VERSION ""

NS_ :

BS_:

BU_: CAM TESTER FRS VCU GW ESC ACU TCM

BO_ 71 FRS_Obj_39_Part02: 8 FRS
 SG_ FRS_Msg_CheckSum_39Obj02 : 63|8@0+ (1,0) [0|255] "bit"  CAM
 SG_ FRS_Msg_AliveCounter_39Obj02 : 51|4@0+ (1,0) [0|15] "bit"  CAM
 SG_ FRS_Obj_Type_39Obj : 33|2@0+ (1,0) [0|3] "bit"  CAM
 SG_ FRS_Obj_MeasFlag_39Obj : 52|1@0+ (1,0) [0|1] "bit"  CAM
 SG_ FRS_Obj_YVelRel_39Obj : 47|11@0+ (0.1,-102.4) [-102.4|102.3] "m/s"  CAM
 SG_ FRS_Obj_XVelRel_39Obj : 7|11@0+ (0.1,-102.4) [-102.4|102.3] "m/s"  CAM
 SG_ FRS_Obj_YPos_39Obj : 12|13@0+ (0.015625,-64) [-64|63.984375] "m"  CAM
 SG_ FRS_Obj_XPos_39Obj : 31|14@0+ (0.015625,0) [0|255.984375] "m"  CAM

BO_ 70 FRS_Obj_38_Part02: 8 FRS
 SG_ FRS_Msg_CheckSum_38Obj02 : 63|8@0+ (1,0) [0|255] "bit"  CAM
 SG_ FRS_Msg_AliveCounter_38Obj02 : 51|4@0+ (1,0) [0|15] "bit"  CAM
 SG_ FRS_Obj_Type_38Obj : 33|2@0+ (1,0) [0|3] "bit"  CAM
 SG_ FRS_Obj_MeasFlag_38Obj : 52|1@0+ (1,0) [0|1] "bit"  CAM
 SG_ FRS_Obj_YVelRel_38Obj : 47|11@0+ (0.1,-102.4) [-102.4|102.3] "m/s"  CAM
 SG_ FRS_Obj_XVelRel_38Obj : 7|11@0+ (0.1,-102.4) [-102.4|102.3] "m/s"  CAM
 SG_ FRS_Obj_YPos_38Obj : 12|13@0+ (0.015625,-64) [-64|63.984375] "m"  CAM
 SG_ FRS_Obj_XPos_38Obj : 31|14@0+ (0.015625,0) [0|255.984375] "m"  CAM

BO_ 69 FRS_Obj_37_Part02: 8 FRS
 SG_ FRS_Msg_CheckSum_37Obj02 : 63|8@0+ (1,0) [0|255] "bit"  CAM
 SG_ FRS_Msg_AliveCounter_37Obj02 : 51|4@0+ (1,0) [0|15] "bit"  CAM
 SG_ FRS_Obj_Type_37Obj : 33|2@0+ (1,0) [0|3] "bit"  CAM
 SG_ FRS_Obj_MeasFlag_37Obj : 52|1@0+ (1,0) [0|1] "bit"  CAM
 SG_ FRS_Obj_YVelRel_37Obj : 47|11@0+ (0.1,-102.4) [-102.4|102.3] "m/s"  CAM
 SG_ FRS_Obj_XVelRel_37Obj : 7|11@0+ (0.1,-102.4) [-102.4|102.3] "m/s"  CAM
 SG_ FRS_Obj_YPos_37Obj : 12|13@0+ (0.015625,-64) [-64|63.984375] "m"  CAM
 SG_ FRS_Obj_XPos_37Obj : 31|14@0+ (0.015625,0) [0|255.984375] "m"  CAM

BO_ 68 FRS_Obj_36_Part02: 8 FRS
 SG_ FRS_Msg_CheckSum_36Obj02 : 63|8@0+ (1,0) [0|255] "bit"  CAM
 SG_ FRS_Msg_AliveCounter_36Obj02 : 51|4@0+ (1,0) [0|15] "bit"  CAM
 SG_ FRS_Obj_Type_36Obj : 33|2@0+ (1,0) [0|3] "bit"  CAM
 SG_ FRS_Obj_MeasFlag_36Obj : 52|1@0+ (1,0) [0|1] "bit"  CAM
 SG_ FRS_Obj_YVelRel_36Obj : 47|11@0+ (0.1,-102.4) [-102.4|102.3] "m/s"  CAM
 SG_ FRS_Obj_XVelRel_36Obj : 7|11@0+ (0.1,-102.4) [-102.4|102.3] "m/s"  CAM
 SG_ FRS_Obj_YPos_36Obj : 12|13@0+ (0.015625,-64) [-64|63.984375] "m"  CAM
 SG_ FRS_Obj_XPos_36Obj : 31|14@0+ (0.015625,0) [0|255.984375] "m"  CAM

BO_ 67 FRS_Obj_35_Part02: 8 FRS
 SG_ FRS_Msg_CheckSum_35Obj02 : 63|8@0+ (1,0) [0|255] "bit"  CAM
 SG_ FRS_Msg_AliveCounter_35Obj02 : 51|4@0+ (1,0) [0|15] "bit"  CAM
 SG_ FRS_Obj_Type_35Obj : 33|2@0+ (1,0) [0|3] "bit"  CAM
 SG_ FRS_Obj_MeasFlag_35Obj : 52|1@0+ (1,0) [0|1] "bit"  CAM
 SG_ FRS_Obj_YVelRel_35Obj : 47|11@0+ (0.1,-102.4) [-102.4|102.3] "m/s"  CAM
 SG_ FRS_Obj_XVelRel_35Obj : 7|11@0+ (0.1,-102.4) [-102.4|102.3] "m/s"  CAM
 SG_ FRS_Obj_YPos_35Obj : 12|13@0+ (0.015625,-64) [-64|63.984375] "m"  CAM
 SG_ FRS_Obj_XPos_35Obj : 31|14@0+ (0.015625,0) [0|255.984375] "m"  CAM

BO_ 66 FRS_Obj_34_Part02: 8 FRS
 SG_ FRS_Msg_CheckSum_34Obj02 : 63|8@0+ (1,0) [0|255] "bit"  CAM
 SG_ FRS_Msg_AliveCounter_34Obj02 : 51|4@0+ (1,0) [0|15] "bit"  CAM
 SG_ FRS_Obj_Type_34Obj : 33|2@0+ (1,0) [0|3] "bit"  CAM
 SG_ FRS_Obj_MeasFlag_34Obj : 52|1@0+ (1,0) [0|1] "bit"  CAM
 SG_ FRS_Obj_YVelRel_34Obj : 47|11@0+ (0.1,-102.4) [-102.4|102.3] "m/s"  CAM
 SG_ FRS_Obj_XVelRel_34Obj : 7|11@0+ (0.1,-102.4) [-102.4|102.3] "m/s"  CAM
 SG_ FRS_Obj_YPos_34Obj : 12|13@0+ (0.015625,-64) [-64|63.984375] "m"  CAM
 SG_ FRS_Obj_XPos_34Obj : 31|14@0+ (0.015625,0) [0|255.984375] "m"  CAM

BO_ 65 FRS_Obj_33_Part02: 8 FRS
 SG_ FRS_Msg_CheckSum_33Obj02 : 63|8@0+ (1,0) [0|255] "bit"  CAM
 SG_ FRS_Msg_AliveCounter_33Obj02 : 51|4@0+ (1,0) [0|15] "bit"  CAM
 SG_ FRS_Obj_Type_33Obj : 33|2@0+ (1,0) [0|3] "bit"  CAM
 SG_ FRS_Obj_MeasFlag_33Obj : 52|1@0+ (1,0) [0|1] "bit"  CAM
 SG_ FRS_Obj_YVelRel_33Obj : 47|11@0+ (0.1,-102.4) [-102.4|102.3] "m/s"  CAM
 SG_ FRS_Obj_XVelRel_33Obj : 7|11@0+ (0.1,-102.4) [-102.4|102.3] "m/s"  CAM
 SG_ FRS_Obj_YPos_33Obj : 12|13@0+ (0.015625,-64) [-64|63.984375] "m"  CAM
 SG_ FRS_Obj_XPos_33Obj : 31|14@0+ (0.015625,0) [0|255.984375] "m"  CAM

BO_ 64 FRS_Obj_32_Part02: 8 FRS
 SG_ FRS_Msg_CheckSum_32Obj02 : 63|8@0+ (1,0) [0|255] "bit"  CAM
 SG_ FRS_Msg_AliveCounter_32Obj02 : 51|4@0+ (1,0) [0|15] "bit"  CAM
 SG_ FRS_Obj_Type_32Obj : 33|2@0+ (1,0) [0|3] "bit"  CAM
 SG_ FRS_Obj_MeasFlag_32Obj : 52|1@0+ (1,0) [0|1] "bit"  CAM
 SG_ FRS_Obj_YVelRel_32Obj : 47|11@0+ (0.1,-102.4) [-102.4|102.3] "m/s"  CAM
 SG_ FRS_Obj_XVelRel_32Obj : 7|11@0+ (0.1,-102.4) [-102.4|102.3] "m/s"  CAM
 SG_ FRS_Obj_YPos_32Obj : 12|13@0+ (0.015625,-64) [-64|63.984375] "m"  CAM
 SG_ FRS_Obj_XPos_32Obj : 31|14@0+ (0.015625,0) [0|255.984375] "m"  CAM

BO_ 63 FRS_Obj_31_Part02: 8 FRS
 SG_ FRS_Msg_CheckSum_31Obj02 : 63|8@0+ (1,0) [0|255] "bit"  CAM
 SG_ FRS_Msg_AliveCounter_31Obj02 : 51|4@0+ (1,0) [0|15] "bit"  CAM
 SG_ FRS_Obj_Type_31Obj : 33|2@0+ (1,0) [0|3] "bit"  CAM
 SG_ FRS_Obj_MeasFlag_31Obj : 52|1@0+ (1,0) [0|1] "bit"  CAM
 SG_ FRS_Obj_YVelRel_31Obj : 47|11@0+ (0.1,-102.4) [-102.4|102.3] "m/s"  CAM
 SG_ FRS_Obj_XVelRel_31Obj : 7|11@0+ (0.1,-102.4) [-102.4|102.3] "m/s"  CAM
 SG_ FRS_Obj_YPos_31Obj : 12|13@0+ (0.015625,-64) [-64|63.984375] "m"  CAM
 SG_ FRS_Obj_XPos_31Obj : 31|14@0+ (0.015625,0) [0|255.984375] "m"  CAM

BO_ 62 FRS_Obj_30_Part02: 8 FRS
 SG_ FRS_Msg_CheckSum_30Obj02 : 63|8@0+ (1,0) [0|255] "bit"  CAM
 SG_ FRS_Msg_AliveCounter_30Obj02 : 51|4@0+ (1,0) [0|15] "bit"  CAM
 SG_ FRS_Obj_Type_30Obj : 33|2@0+ (1,0) [0|3] "bit"  CAM
 SG_ FRS_Obj_MeasFlag_30Obj : 52|1@0+ (1,0) [0|1] "bit"  CAM
 SG_ FRS_Obj_YVelRel_30Obj : 47|11@0+ (0.1,-102.4) [-102.4|102.3] "m/s"  CAM
 SG_ FRS_Obj_XVelRel_30Obj : 7|11@0+ (0.1,-102.4) [-102.4|102.3] "m/s"  CAM
 SG_ FRS_Obj_YPos_30Obj : 12|13@0+ (0.015625,-64) [-64|63.984375] "m"  CAM
 SG_ FRS_Obj_XPos_30Obj : 31|14@0+ (0.015625,0) [0|255.984375] "m"  CAM

BO_ 61 FRS_Obj_29_Part02: 8 FRS
 SG_ FRS_Msg_CheckSum_29Obj02 : 63|8@0+ (1,0) [0|255] "bit"  CAM
 SG_ FRS_Msg_AliveCounter_29Obj02 : 51|4@0+ (1,0) [0|15] "bit"  CAM
 SG_ FRS_Obj_Type_29Obj : 33|2@0+ (1,0) [0|3] "bit"  CAM
 SG_ FRS_Obj_MeasFlag_29Obj : 52|1@0+ (1,0) [0|1] "bit"  CAM
 SG_ FRS_Obj_YVelRel_29Obj : 47|11@0+ (0.1,-102.4) [-102.4|102.3] "m/s"  CAM
 SG_ FRS_Obj_XVelRel_29Obj : 7|11@0+ (0.1,-102.4) [-102.4|102.3] "m/s"  CAM
 SG_ FRS_Obj_YPos_29Obj : 12|13@0+ (0.015625,-64) [-64|63.984375] "m"  CAM
 SG_ FRS_Obj_XPos_29Obj : 31|14@0+ (0.015625,0) [0|255.984375] "m"  CAM

BO_ 60 FRS_Obj_28_Part02: 8 FRS
 SG_ FRS_Msg_CheckSum_28Obj02 : 63|8@0+ (1,0) [0|255] "bit"  CAM
 SG_ FRS_Msg_AliveCounter_28Obj02 : 51|4@0+ (1,0) [0|15] "bit"  CAM
 SG_ FRS_Obj_Type_28Obj : 33|2@0+ (1,0) [0|3] "bit"  CAM
 SG_ FRS_Obj_MeasFlag_28Obj : 52|1@0+ (1,0) [0|1] "bit"  CAM
 SG_ FRS_Obj_YVelRel_28Obj : 47|11@0+ (0.1,-102.4) [-102.4|102.3] "m/s"  CAM
 SG_ FRS_Obj_XVelRel_28Obj : 7|11@0+ (0.1,-102.4) [-102.4|102.3] "m/s"  CAM
 SG_ FRS_Obj_YPos_28Obj : 12|13@0+ (0.015625,-64) [-64|63.984375] "m"  CAM
 SG_ FRS_Obj_XPos_28Obj : 31|14@0+ (0.015625,0) [0|255.984375] "m"  CAM

BO_ 59 FRS_Obj_27_Part02: 8 FRS
 SG_ FRS_Msg_CheckSum_27Obj02 : 63|8@0+ (1,0) [0|255] "bit"  CAM
 SG_ FRS_Msg_AliveCounter_27Obj02 : 51|4@0+ (1,0) [0|15] "bit"  CAM
 SG_ FRS_Obj_Type_27Obj : 33|2@0+ (1,0) [0|3] "bit"  CAM
 SG_ FRS_Obj_MeasFlag_27Obj : 52|1@0+ (1,0) [0|1] "bit"  CAM
 SG_ FRS_Obj_YVelRel_27Obj : 47|11@0+ (0.1,-102.4) [-102.4|102.3] "m/s"  CAM
 SG_ FRS_Obj_XVelRel_27Obj : 7|11@0+ (0.1,-102.4) [-102.4|102.3] "m/s"  CAM
 SG_ FRS_Obj_YPos_27Obj : 12|13@0+ (0.015625,-64) [-64|63.984375] "m"  CAM
 SG_ FRS_Obj_XPos_27Obj : 31|14@0+ (0.015625,0) [0|255.984375] "m"  CAM

BO_ 58 FRS_Obj_26_Part02: 8 FRS
 SG_ FRS_Msg_CheckSum_26Obj02 : 63|8@0+ (1,0) [0|255] "bit"  CAM
 SG_ FRS_Msg_AliveCounter_26Obj02 : 51|4@0+ (1,0) [0|15] "bit"  CAM
 SG_ FRS_Obj_Type_26Obj : 33|2@0+ (1,0) [0|3] "bit"  CAM
 SG_ FRS_Obj_MeasFlag_26Obj : 52|1@0+ (1,0) [0|1] "bit"  CAM
 SG_ FRS_Obj_YVelRel_26Obj : 47|11@0+ (0.1,-102.4) [-102.4|102.3] "m/s"  CAM
 SG_ FRS_Obj_XVelRel_26Obj : 7|11@0+ (0.1,-102.4) [-102.4|102.3] "m/s"  CAM
 SG_ FRS_Obj_YPos_26Obj : 12|13@0+ (0.015625,-64) [-64|63.984375] "m"  CAM
 SG_ FRS_Obj_XPos_26Obj : 31|14@0+ (0.015625,0) [0|255.984375] "m"  CAM

BO_ 57 FRS_Obj_25_Part02: 8 FRS
 SG_ FRS_Msg_CheckSum_25Obj02 : 63|8@0+ (1,0) [0|255] "bit"  CAM
 SG_ FRS_Msg_AliveCounter_25Obj02 : 51|4@0+ (1,0) [0|15] "bit"  CAM
 SG_ FRS_Obj_Type_25Obj : 33|2@0+ (1,0) [0|3] "bit"  CAM
 SG_ FRS_Obj_MeasFlag_25Obj : 52|1@0+ (1,0) [0|1] "bit"  CAM
 SG_ FRS_Obj_YVelRel_25Obj : 47|11@0+ (0.1,-102.4) [-102.4|102.3] "m/s"  CAM
 SG_ FRS_Obj_XVelRel_25Obj : 7|11@0+ (0.1,-102.4) [-102.4|102.3] "m/s"  CAM
 SG_ FRS_Obj_YPos_25Obj : 12|13@0+ (0.015625,-64) [-64|63.984375] "m"  CAM
 SG_ FRS_Obj_XPos_25Obj : 31|14@0+ (0.015625,0) [0|255.984375] "m"  CAM

BO_ 56 FRS_Obj_24_Part02: 8 FRS
 SG_ FRS_Msg_CheckSum_24Obj02 : 63|8@0+ (1,0) [0|255] "bit"  CAM
 SG_ FRS_Msg_AliveCounter_24Obj02 : 51|4@0+ (1,0) [0|15] "bit"  CAM
 SG_ FRS_Obj_Type_24Obj : 33|2@0+ (1,0) [0|3] "bit"  CAM
 SG_ FRS_Obj_MeasFlag_24Obj : 52|1@0+ (1,0) [0|1] "bit"  CAM
 SG_ FRS_Obj_YVelRel_24Obj : 47|11@0+ (0.1,-102.4) [-102.4|102.3] "m/s"  CAM
 SG_ FRS_Obj_XVelRel_24Obj : 7|11@0+ (0.1,-102.4) [-102.4|102.3] "m/s"  CAM
 SG_ FRS_Obj_YPos_24Obj : 12|13@0+ (0.015625,-64) [-64|63.984375] "m"  CAM
 SG_ FRS_Obj_XPos_24Obj : 31|14@0+ (0.015625,0) [0|255.984375] "m"  CAM

BO_ 55 FRS_Obj_23_Part02: 8 FRS
 SG_ FRS_Msg_CheckSum_23Obj02 : 63|8@0+ (1,0) [0|255] "bit"  CAM
 SG_ FRS_Msg_AliveCounter_23Obj02 : 51|4@0+ (1,0) [0|15] "bit"  CAM
 SG_ FRS_Obj_Type_23Obj : 33|2@0+ (1,0) [0|3] "bit"  CAM
 SG_ FRS_Obj_MeasFlag_23Obj : 52|1@0+ (1,0) [0|1] "bit"  CAM
 SG_ FRS_Obj_YVelRel_23Obj : 47|11@0+ (0.1,-102.4) [-102.4|102.3] "m/s"  CAM
 SG_ FRS_Obj_XVelRel_23Obj : 7|11@0+ (0.1,-102.4) [-102.4|102.3] "m/s"  CAM
 SG_ FRS_Obj_YPos_23Obj : 12|13@0+ (0.015625,-64) [-64|63.984375] "m"  CAM
 SG_ FRS_Obj_XPos_23Obj : 31|14@0+ (0.015625,0) [0|255.984375] "m"  CAM

BO_ 54 FRS_Obj_22_Part02: 8 FRS
 SG_ FRS_Msg_CheckSum_22Obj02 : 63|8@0+ (1,0) [0|255] "bit"  CAM
 SG_ FRS_Msg_AliveCounter_22Obj02 : 51|4@0+ (1,0) [0|15] "bit"  CAM
 SG_ FRS_Obj_Type_22Obj : 33|2@0+ (1,0) [0|3] "bit"  CAM
 SG_ FRS_Obj_MeasFlag_22Obj : 52|1@0+ (1,0) [0|1] "bit"  CAM
 SG_ FRS_Obj_YVelRel_22Obj : 47|11@0+ (0.1,-102.4) [-102.4|102.3] "m/s"  CAM
 SG_ FRS_Obj_XVelRel_22Obj : 7|11@0+ (0.1,-102.4) [-102.4|102.3] "m/s"  CAM
 SG_ FRS_Obj_YPos_22Obj : 12|13@0+ (0.015625,-64) [-64|63.984375] "m"  CAM
 SG_ FRS_Obj_XPos_22Obj : 31|14@0+ (0.015625,0) [0|255.984375] "m"  CAM

BO_ 53 FRS_Obj_21_Part02: 8 FRS
 SG_ FRS_Msg_CheckSum_21Obj02 : 63|8@0+ (1,0) [0|255] "bit"  CAM
 SG_ FRS_Msg_AliveCounter_21Obj02 : 51|4@0+ (1,0) [0|15] "bit"  CAM
 SG_ FRS_Obj_Type_21Obj : 33|2@0+ (1,0) [0|3] "bit"  CAM
 SG_ FRS_Obj_MeasFlag_21Obj : 52|1@0+ (1,0) [0|1] "bit"  CAM
 SG_ FRS_Obj_YVelRel_21Obj : 47|11@0+ (0.1,-102.4) [-102.4|102.3] "m/s"  CAM
 SG_ FRS_Obj_XVelRel_21Obj : 7|11@0+ (0.1,-102.4) [-102.4|102.3] "m/s"  CAM
 SG_ FRS_Obj_YPos_21Obj : 12|13@0+ (0.015625,-64) [-64|63.984375] "m"  CAM
 SG_ FRS_Obj_XPos_21Obj : 31|14@0+ (0.015625,0) [0|255.984375] "m"  CAM

BO_ 52 FRS_Obj_20_Part02: 8 FRS
 SG_ FRS_Msg_CheckSum_20Obj02 : 63|8@0+ (1,0) [0|255] "bit"  CAM
 SG_ FRS_Msg_AliveCounter_20Obj02 : 51|4@0+ (1,0) [0|15] "bit"  CAM
 SG_ FRS_Obj_Type_20Obj : 33|2@0+ (1,0) [0|3] "bit"  CAM
 SG_ FRS_Obj_MeasFlag_20Obj : 52|1@0+ (1,0) [0|1] "bit"  CAM
 SG_ FRS_Obj_YVelRel_20Obj : 47|11@0+ (0.1,-102.4) [-102.4|102.3] "m/s"  CAM
 SG_ FRS_Obj_XVelRel_20Obj : 7|11@0+ (0.1,-102.4) [-102.4|102.3] "m/s"  CAM
 SG_ FRS_Obj_YPos_20Obj : 12|13@0+ (0.015625,-64) [-64|63.984375] "m"  CAM
 SG_ FRS_Obj_XPos_20Obj : 31|14@0+ (0.015625,0) [0|255.984375] "m"  CAM

BO_ 51 FRS_Obj_19_Part02: 8 FRS
 SG_ FRS_Msg_CheckSum_19Obj02 : 63|8@0+ (1,0) [0|255] "bit"  CAM
 SG_ FRS_Msg_AliveCounter_19Obj02 : 51|4@0+ (1,0) [0|15] "bit"  CAM
 SG_ FRS_Obj_Type_19Obj : 33|2@0+ (1,0) [0|3] "bit"  CAM
 SG_ FRS_Obj_MeasFlag_19Obj : 52|1@0+ (1,0) [0|1] "bit"  CAM
 SG_ FRS_Obj_YVelRel_19Obj : 47|11@0+ (0.1,-102.4) [-102.4|102.3] "m/s"  CAM
 SG_ FRS_Obj_XVelRel_19Obj : 7|11@0+ (0.1,-102.4) [-102.4|102.3] "m/s"  CAM
 SG_ FRS_Obj_YPos_19Obj : 12|13@0+ (0.015625,-64) [-64|63.984375] "m"  CAM
 SG_ FRS_Obj_XPos_19Obj : 31|14@0+ (0.015625,0) [0|255.984375] "m"  CAM

BO_ 50 FRS_Obj_18_Part02: 8 FRS
 SG_ FRS_Msg_CheckSum_18Obj02 : 63|8@0+ (1,0) [0|255] "bit"  CAM
 SG_ FRS_Msg_AliveCounter_18Obj02 : 51|4@0+ (1,0) [0|15] "bit"  CAM
 SG_ FRS_Obj_Type_18Obj : 33|2@0+ (1,0) [0|3] "bit"  CAM
 SG_ FRS_Obj_MeasFlag_18Obj : 52|1@0+ (1,0) [0|1] "bit"  CAM
 SG_ FRS_Obj_YVelRel_18Obj : 47|11@0+ (0.1,-102.4) [-102.4|102.3] "m/s"  CAM
 SG_ FRS_Obj_XVelRel_18Obj : 7|11@0+ (0.1,-102.4) [-102.4|102.3] "m/s"  CAM
 SG_ FRS_Obj_YPos_18Obj : 12|13@0+ (0.015625,-64) [-64|63.984375] "m"  CAM
 SG_ FRS_Obj_XPos_18Obj : 31|14@0+ (0.015625,0) [0|255.984375] "m"  CAM

BO_ 49 FRS_Obj_17_Part02: 8 FRS
 SG_ FRS_Msg_CheckSum_17Obj02 : 63|8@0+ (1,0) [0|255] "bit"  CAM
 SG_ FRS_Msg_AliveCounter_17Obj02 : 51|4@0+ (1,0) [0|15] "bit"  CAM
 SG_ FRS_Obj_Type_17Obj : 33|2@0+ (1,0) [0|3] "bit"  CAM
 SG_ FRS_Obj_MeasFlag_17Obj : 52|1@0+ (1,0) [0|1] "bit"  CAM
 SG_ FRS_Obj_YVelRel_17Obj : 47|11@0+ (0.1,-102.4) [-102.4|102.3] "m/s"  CAM
 SG_ FRS_Obj_XVelRel_17Obj : 7|11@0+ (0.1,-102.4) [-102.4|102.3] "m/s"  CAM
 SG_ FRS_Obj_YPos_17Obj : 12|13@0+ (0.015625,-64) [-64|63.984375] "m"  CAM
 SG_ FRS_Obj_XPos_17Obj : 31|14@0+ (0.015625,0) [0|255.984375] "m"  CAM

BO_ 48 FRS_Obj_16_Part02: 8 FRS
 SG_ FRS_Msg_CheckSum_16Obj02 : 63|8@0+ (1,0) [0|255] "bit"  CAM
 SG_ FRS_Msg_AliveCounter_16Obj02 : 51|4@0+ (1,0) [0|15] "bit"  CAM
 SG_ FRS_Obj_Type_16Obj : 33|2@0+ (1,0) [0|3] "bit"  CAM
 SG_ FRS_Obj_MeasFlag_16Obj : 52|1@0+ (1,0) [0|1] "bit"  CAM
 SG_ FRS_Obj_YVelRel_16Obj : 47|11@0+ (0.1,-102.4) [-102.4|102.3] "m/s"  CAM
 SG_ FRS_Obj_XVelRel_16Obj : 7|11@0+ (0.1,-102.4) [-102.4|102.3] "m/s"  CAM
 SG_ FRS_Obj_YPos_16Obj : 12|13@0+ (0.015625,-64) [-64|63.984375] "m"  CAM
 SG_ FRS_Obj_XPos_16Obj : 31|14@0+ (0.015625,0) [0|255.984375] "m"  CAM

BO_ 47 FRS_Obj_15_Part02: 8 FRS
 SG_ FRS_Msg_CheckSum_15Obj02 : 63|8@0+ (1,0) [0|255] "bit"  CAM
 SG_ FRS_Msg_AliveCounter_15Obj02 : 51|4@0+ (1,0) [0|15] "bit"  CAM
 SG_ FRS_Obj_Type_15Obj : 33|2@0+ (1,0) [0|3] "bit"  CAM
 SG_ FRS_Obj_MeasFlag_15Obj : 52|1@0+ (1,0) [0|1] "bit"  CAM
 SG_ FRS_Obj_YVelRel_15Obj : 47|11@0+ (0.1,-102.4) [-102.4|102.3] "m/s"  CAM
 SG_ FRS_Obj_XVelRel_15Obj : 7|11@0+ (0.1,-102.4) [-102.4|102.3] "m/s"  CAM
 SG_ FRS_Obj_YPos_15Obj : 12|13@0+ (0.015625,-64) [-64|63.984375] "m"  CAM
 SG_ FRS_Obj_XPos_15Obj : 31|14@0+ (0.015625,0) [0|255.984375] "m"  CAM

BO_ 46 FRS_Obj_14_Part02: 8 FRS
 SG_ FRS_Msg_CheckSum_14Obj02 : 63|8@0+ (1,0) [0|255] "bit"  CAM
 SG_ FRS_Msg_AliveCounter_14Obj02 : 51|4@0+ (1,0) [0|15] "bit"  CAM
 SG_ FRS_Obj_Type_14Obj : 33|2@0+ (1,0) [0|3] "bit"  CAM
 SG_ FRS_Obj_MeasFlag_14Obj : 52|1@0+ (1,0) [0|1] "bit"  CAM
 SG_ FRS_Obj_YVelRel_14Obj : 47|11@0+ (0.1,-102.4) [-102.4|102.3] "m/s"  CAM
 SG_ FRS_Obj_XVelRel_14Obj : 7|11@0+ (0.1,-102.4) [-102.4|102.3] "m/s"  CAM
 SG_ FRS_Obj_YPos_14Obj : 12|13@0+ (0.015625,-64) [-64|63.984375] "m"  CAM
 SG_ FRS_Obj_XPos_14Obj : 31|14@0+ (0.015625,0) [0|255.984375] "m"  CAM

BO_ 45 FRS_Obj_13_Part02: 8 FRS
 SG_ FRS_Msg_CheckSum_13Obj02 : 63|8@0+ (1,0) [0|255] "bit"  CAM
 SG_ FRS_Msg_AliveCounter_13Obj02 : 51|4@0+ (1,0) [0|15] "bit"  CAM
 SG_ FRS_Obj_Type_13Obj : 33|2@0+ (1,0) [0|3] "bit"  CAM
 SG_ FRS_Obj_MeasFlag_13Obj : 52|1@0+ (1,0) [0|1] "bit"  CAM
 SG_ FRS_Obj_YVelRel_13Obj : 47|11@0+ (0.1,-102.4) [-102.4|102.3] "m/s"  CAM
 SG_ FRS_Obj_XVelRel_13Obj : 7|11@0+ (0.1,-102.4) [-102.4|102.3] "m/s"  CAM
 SG_ FRS_Obj_YPos_13Obj : 12|13@0+ (0.015625,-64) [-64|63.984375] "m"  CAM
 SG_ FRS_Obj_XPos_13Obj : 31|14@0+ (0.015625,0) [0|255.984375] "m"  CAM

BO_ 44 FRS_Obj_12_Part02: 8 FRS
 SG_ FRS_Msg_CheckSum_12Obj02 : 63|8@0+ (1,0) [0|255] "bit"  CAM
 SG_ FRS_Msg_AliveCounter_12Obj02 : 51|4@0+ (1,0) [0|15] "bit"  CAM
 SG_ FRS_Obj_Type_12Obj : 33|2@0+ (1,0) [0|3] "bit"  CAM
 SG_ FRS_Obj_MeasFlag_12Obj : 52|1@0+ (1,0) [0|1] "bit"  CAM
 SG_ FRS_Obj_YVelRel_12Obj : 47|11@0+ (0.1,-102.4) [-102.4|102.3] "m/s"  CAM
 SG_ FRS_Obj_XVelRel_12Obj : 7|11@0+ (0.1,-102.4) [-102.4|102.3] "m/s"  CAM
 SG_ FRS_Obj_YPos_12Obj : 12|13@0+ (0.015625,-64) [-64|63.984375] "m"  CAM
 SG_ FRS_Obj_XPos_12Obj : 31|14@0+ (0.015625,0) [0|255.984375] "m"  CAM

BO_ 43 FRS_Obj_11_Part02: 8 FRS
 SG_ FRS_Msg_CheckSum_11Obj02 : 63|8@0+ (1,0) [0|255] "bit"  CAM
 SG_ FRS_Msg_AliveCounter_11Obj02 : 51|4@0+ (1,0) [0|15] "bit"  CAM
 SG_ FRS_Obj_Type_11Obj : 33|2@0+ (1,0) [0|3] "bit"  CAM
 SG_ FRS_Obj_MeasFlag_11Obj : 52|1@0+ (1,0) [0|1] "bit"  CAM
 SG_ FRS_Obj_YVelRel_11Obj : 47|11@0+ (0.1,-102.4) [-102.4|102.3] "m/s"  CAM
 SG_ FRS_Obj_XVelRel_11Obj : 7|11@0+ (0.1,-102.4) [-102.4|102.3] "m/s"  CAM
 SG_ FRS_Obj_YPos_11Obj : 12|13@0+ (0.015625,-64) [-64|63.984375] "m"  CAM
 SG_ FRS_Obj_XPos_11Obj : 31|14@0+ (0.015625,0) [0|255.984375] "m"  CAM

BO_ 42 FRS_Obj_10_Part02: 8 FRS
 SG_ FRS_Msg_CheckSum_10Obj02 : 63|8@0+ (1,0) [0|255] "bit"  CAM
 SG_ FRS_Msg_AliveCounter_10Obj02 : 51|4@0+ (1,0) [0|15] "bit"  CAM
 SG_ FRS_Obj_Type_10Obj : 33|2@0+ (1,0) [0|3] "bit"  CAM
 SG_ FRS_Obj_MeasFlag_10Obj : 52|1@0+ (1,0) [0|1] "bit"  CAM
 SG_ FRS_Obj_YVelRel_10Obj : 47|11@0+ (0.1,-102.4) [-102.4|102.3] "m/s"  CAM
 SG_ FRS_Obj_XVelRel_10Obj : 7|11@0+ (0.1,-102.4) [-102.4|102.3] "m/s"  CAM
 SG_ FRS_Obj_YPos_10Obj : 12|13@0+ (0.015625,-64) [-64|63.984375] "m"  CAM
 SG_ FRS_Obj_XPos_10Obj : 31|14@0+ (0.015625,0) [0|255.984375] "m"  CAM

BO_ 41 FRS_Obj_09_Part02: 8 FRS
 SG_ FRS_Msg_CheckSum_09Obj02 : 63|8@0+ (1,0) [0|255] "bit"  CAM
 SG_ FRS_Msg_AliveCounter_09Obj02 : 51|4@0+ (1,0) [0|15] "bit"  CAM
 SG_ FRS_Obj_Type_09Obj : 33|2@0+ (1,0) [0|3] "bit"  CAM
 SG_ FRS_Obj_MeasFlag_09Obj : 52|1@0+ (1,0) [0|1] "bit"  CAM
 SG_ FRS_Obj_YVelRel_09Obj : 47|11@0+ (0.1,-102.4) [-102.4|102.3] "m/s"  CAM
 SG_ FRS_Obj_XVelRel_09Obj : 7|11@0+ (0.1,-102.4) [-102.4|102.3] "m/s"  CAM
 SG_ FRS_Obj_YPos_09Obj : 12|13@0+ (0.015625,-64) [-64|63.984375] "m"  CAM
 SG_ FRS_Obj_XPos_09Obj : 31|14@0+ (0.015625,0) [0|255.984375] "m"  CAM

BO_ 40 FRS_Obj_08_Part02: 8 FRS
 SG_ FRS_Msg_CheckSum_08Obj02 : 63|8@0+ (1,0) [0|255] "bit"  CAM
 SG_ FRS_Msg_AliveCounter_08Obj02 : 51|4@0+ (1,0) [0|15] "bit"  CAM
 SG_ FRS_Obj_Type_08Obj : 33|2@0+ (1,0) [0|3] "bit"  CAM
 SG_ FRS_Obj_MeasFlag_08Obj : 52|1@0+ (1,0) [0|1] "bit"  CAM
 SG_ FRS_Obj_YVelRel_08Obj : 47|11@0+ (0.1,-102.4) [-102.4|102.3] "m/s"  CAM
 SG_ FRS_Obj_XVelRel_08Obj : 7|11@0+ (0.1,-102.4) [-102.4|102.3] "m/s"  CAM
 SG_ FRS_Obj_YPos_08Obj : 12|13@0+ (0.015625,-64) [-64|63.984375] "m"  CAM
 SG_ FRS_Obj_XPos_08Obj : 31|14@0+ (0.015625,0) [0|255.984375] "m"  CAM

BO_ 39 FRS_Obj_07_Part02: 8 FRS
 SG_ FRS_Msg_CheckSum_07Obj02 : 63|8@0+ (1,0) [0|255] "bit"  CAM
 SG_ FRS_Msg_AliveCounter_07Obj02 : 51|4@0+ (1,0) [0|15] "bit"  CAM
 SG_ FRS_Obj_Type_07Obj : 33|2@0+ (1,0) [0|3] "bit"  CAM
 SG_ FRS_Obj_MeasFlag_07Obj : 52|1@0+ (1,0) [0|1] "bit"  CAM
 SG_ FRS_Obj_YVelRel_07Obj : 47|11@0+ (0.1,-102.4) [-102.4|102.3] "m/s"  CAM
 SG_ FRS_Obj_XVelRel_07Obj : 7|11@0+ (0.1,-102.4) [-102.4|102.3] "m/s"  CAM
 SG_ FRS_Obj_YPos_07Obj : 12|13@0+ (0.015625,-64) [-64|63.984375] "m"  CAM
 SG_ FRS_Obj_XPos_07Obj : 31|14@0+ (0.015625,0) [0|255.984375] "m"  CAM

BO_ 38 FRS_Obj_06_Part02: 8 FRS
 SG_ FRS_Msg_CheckSum_06Obj02 : 63|8@0+ (1,0) [0|255] "bit"  CAM
 SG_ FRS_Msg_AliveCounter_06Obj02 : 51|4@0+ (1,0) [0|15] "bit"  CAM
 SG_ FRS_Obj_Type_06Obj : 33|2@0+ (1,0) [0|3] "bit"  CAM
 SG_ FRS_Obj_MeasFlag_06Obj : 52|1@0+ (1,0) [0|1] "bit"  CAM
 SG_ FRS_Obj_YVelRel_06Obj : 47|11@0+ (0.1,-102.4) [-102.4|102.3] "m/s"  CAM
 SG_ FRS_Obj_XVelRel_06Obj : 7|11@0+ (0.1,-102.4) [-102.4|102.3] "m/s"  CAM
 SG_ FRS_Obj_YPos_06Obj : 12|13@0+ (0.015625,-64) [-64|63.984375] "m"  CAM
 SG_ FRS_Obj_XPos_06Obj : 31|14@0+ (0.015625,0) [0|255.984375] "m"  CAM

BO_ 37 FRS_Obj_05_Part02: 8 FRS
 SG_ FRS_Msg_CheckSum_05Obj02 : 63|8@0+ (1,0) [0|255] "bit"  CAM
 SG_ FRS_Msg_AliveCounter_05Obj02 : 51|4@0+ (1,0) [0|15] "bit"  CAM
 SG_ FRS_Obj_Type_05Obj : 33|2@0+ (1,0) [0|3] "bit"  CAM
 SG_ FRS_Obj_MeasFlag_05Obj : 52|1@0+ (1,0) [0|1] "bit"  CAM
 SG_ FRS_Obj_YVelRel_05Obj : 47|11@0+ (0.1,-102.4) [-102.4|102.3] "m/s"  CAM
 SG_ FRS_Obj_XVelRel_05Obj : 7|11@0+ (0.1,-102.4) [-102.4|102.3] "m/s"  CAM
 SG_ FRS_Obj_YPos_05Obj : 12|13@0+ (0.015625,-64) [-64|63.984375] "m"  CAM
 SG_ FRS_Obj_XPos_05Obj : 31|14@0+ (0.015625,0) [0|255.984375] "m"  CAM

BO_ 36 FRS_Obj_04_Part02: 8 FRS
 SG_ FRS_Msg_CheckSum_04Obj02 : 63|8@0+ (1,0) [0|255] "bit"  CAM
 SG_ FRS_Msg_AliveCounter_04Obj02 : 51|4@0+ (1,0) [0|15] "bit"  CAM
 SG_ FRS_Obj_Type_04Obj : 33|2@0+ (1,0) [0|3] "bit"  CAM
 SG_ FRS_Obj_MeasFlag_04Obj : 52|1@0+ (1,0) [0|1] "bit"  CAM
 SG_ FRS_Obj_YVelRel_04Obj : 47|11@0+ (0.1,-102.4) [-102.4|102.3] "m/s"  CAM
 SG_ FRS_Obj_XVelRel_04Obj : 7|11@0+ (0.1,-102.4) [-102.4|102.3] "m/s"  CAM
 SG_ FRS_Obj_YPos_04Obj : 12|13@0+ (0.015625,-64) [-64|63.984375] "m"  CAM
 SG_ FRS_Obj_XPos_04Obj : 31|14@0+ (0.015625,0) [0|255.984375] "m"  CAM

BO_ 35 FRS_Obj_03_Part02: 8 FRS
 SG_ FRS_Msg_CheckSum_03Obj02 : 63|8@0+ (1,0) [0|255] "bit"  CAM
 SG_ FRS_Msg_AliveCounter_03Obj02 : 51|4@0+ (1,0) [0|15] "bit"  CAM
 SG_ FRS_Obj_Type_03Obj : 33|2@0+ (1,0) [0|3] "bit"  CAM
 SG_ FRS_Obj_MeasFlag_03Obj : 52|1@0+ (1,0) [0|1] "bit"  CAM
 SG_ FRS_Obj_YVelRel_03Obj : 47|11@0+ (0.1,-102.4) [-102.4|102.3] "m/s"  CAM
 SG_ FRS_Obj_XVelRel_03Obj : 7|11@0+ (0.1,-102.4) [-102.4|102.3] "m/s"  CAM
 SG_ FRS_Obj_YPos_03Obj : 12|13@0+ (0.015625,-64) [-64|63.984375] "m"  CAM
 SG_ FRS_Obj_XPos_03Obj : 31|14@0+ (0.015625,0) [0|255.984375] "m"  CAM

BO_ 34 FRS_Obj_02_Part02: 8 FRS
 SG_ FRS_Msg_CheckSum_02Obj02 : 63|8@0+ (1,0) [0|255] "bit"  CAM
 SG_ FRS_Msg_AliveCounter_02Obj02 : 51|4@0+ (1,0) [0|15] "bit"  CAM
 SG_ FRS_Obj_Type_02Obj : 33|2@0+ (1,0) [0|3] "bit"  CAM
 SG_ FRS_Obj_MeasFlag_02Obj : 52|1@0+ (1,0) [0|1] "bit"  CAM
 SG_ FRS_Obj_YVelRel_02Obj : 47|11@0+ (0.1,-102.4) [-102.4|102.3] "m/s"  CAM
 SG_ FRS_Obj_XVelRel_02Obj : 7|11@0+ (0.1,-102.4) [-102.4|102.3] "m/s"  CAM
 SG_ FRS_Obj_YPos_02Obj : 12|13@0+ (0.015625,-64) [-64|63.984375] "m"  CAM
 SG_ FRS_Obj_XPos_02Obj : 31|14@0+ (0.015625,0) [0|255.984375] "m"  CAM

BO_ 33 FRS_Obj_01_Part02: 8 FRS
 SG_ FRS_Msg_CheckSum_01Obj02 : 63|8@0+ (1,0) [0|255] "bit"  CAM
 SG_ FRS_Msg_AliveCounter_01Obj02 : 51|4@0+ (1,0) [0|15] "bit"  CAM
 SG_ FRS_Obj_Type_01Obj : 33|2@0+ (1,0) [0|3] "bit"  CAM
 SG_ FRS_Obj_MeasFlag_01Obj : 52|1@0+ (1,0) [0|1] "bit"  CAM
 SG_ FRS_Obj_YVelRel_01Obj : 47|11@0+ (0.1,-102.4) [-102.4|102.3] "m/s"  CAM
 SG_ FRS_Obj_XVelRel_01Obj : 7|11@0+ (0.1,-102.4) [-102.4|102.3] "m/s"  CAM
 SG_ FRS_Obj_YPos_01Obj : 12|13@0+ (0.015625,-64) [-64|63.984375] "m"  CAM
 SG_ FRS_Obj_XPos_01Obj : 31|14@0+ (0.015625,0) [0|255.984375] "m"  CAM

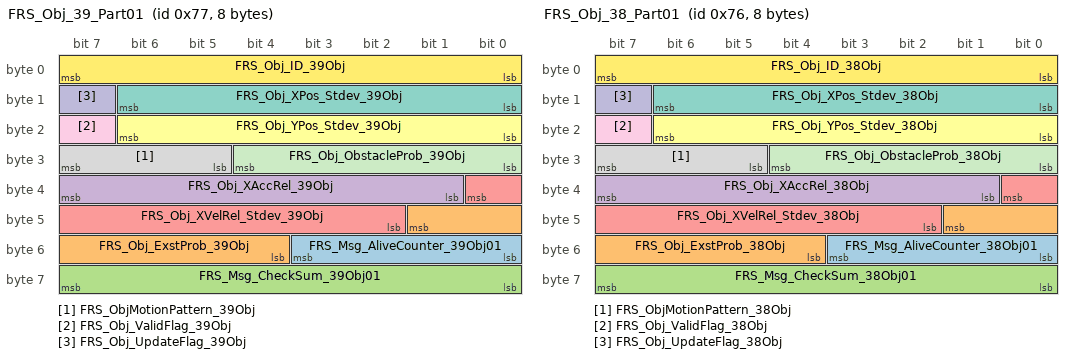
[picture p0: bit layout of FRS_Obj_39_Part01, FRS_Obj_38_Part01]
BO_ 119 FRS_Obj_39_Part01: 8 FRS
 SG_ FRS_Msg_AliveCounter_39Obj01 : 51|4@0+ (1,0) [0|15] "bit"  CAM
 SG_ FRS_Obj_ExstProb_39Obj : 41|6@0+ (1.5873,0) [0|99.9999] "%"  CAM
 SG_ FRS_Msg_CheckSum_39Obj01 : 63|8@0+ (1,0) [0|255] "bit"  CAM
 SG_ FRS_Obj_XAccRel_39Obj : 39|7@0+ (0.15,-9.6) [-9.6|9.45] "m/s2"  CAM
 SG_ FRS_Obj_XVelRel_Stdev_39Obj : 32|7@0+ (0.05,0) [0|6.35] "m/s"  CAM
 SG_ FRS_Obj_YPos_Stdev_39Obj : 22|7@0+ (0.1,0) [0|12.7] "m"  CAM
 SG_ FRS_Obj_XPos_Stdev_39Obj : 14|7@0+ (0.1,0) [0|12.7] "m"  CAM
 SG_ FRS_ObjMotionPattern_39Obj : 31|3@0+ (1,0) [0|7] "bit"  CAM
 SG_ FRS_Obj_ValidFlag_39Obj : 23|1@0+ (1,0) [0|1] "bit"  CAM
 SG_ FRS_Obj_UpdateFlag_39Obj : 15|1@0+ (1,0) [0|1] "bit"  CAM
 SG_ FRS_Obj_ObstacleProb_39Obj : 28|5@0+ (3.2258,0) [0|99.9998] "%"  CAM
 SG_ FRS_Obj_ID_39Obj : 7|8@0+ (1,0) [0|255] "bit"  CAM

BO_ 118 FRS_Obj_38_Part01: 8 FRS
 SG_ FRS_Msg_AliveCounter_38Obj01 : 51|4@0+ (1,0) [0|15] "bit"  CAM
 SG_ FRS_Obj_ExstProb_38Obj : 41|6@0+ (1.5873,0) [0|99.9999] "%"  CAM
 SG_ FRS_Msg_CheckSum_38Obj01 : 63|8@0+ (1,0) [0|255] "bit"  CAM
 SG_ FRS_Obj_XAccRel_38Obj : 39|7@0+ (0.15,-9.6) [-9.6|9.45] "m/s2"  CAM
 SG_ FRS_Obj_XVelRel_Stdev_38Obj : 32|7@0+ (0.05,0) [0|6.35] "m/s"  CAM
 SG_ FRS_Obj_YPos_Stdev_38Obj : 22|7@0+ (0.1,0) [0|12.7] "m"  CAM
 SG_ FRS_Obj_XPos_Stdev_38Obj : 14|7@0+ (0.1,0) [0|12.7] "m"  CAM
 SG_ FRS_ObjMotionPattern_38Obj : 31|3@0+ (1,0) [0|7] "bit"  CAM
 SG_ FRS_Obj_ValidFlag_38Obj : 23|1@0+ (1,0) [0|1] "bit"  CAM
 SG_ FRS_Obj_UpdateFlag_38Obj : 15|1@0+ (1,0) [0|1] "bit"  CAM
 SG_ FRS_Obj_ObstacleProb_38Obj : 28|5@0+ (3.2258,0) [0|99.9998] "%"  CAM
 SG_ FRS_Obj_ID_38Obj : 7|8@0+ (1,0) [0|255] "bit"  CAM

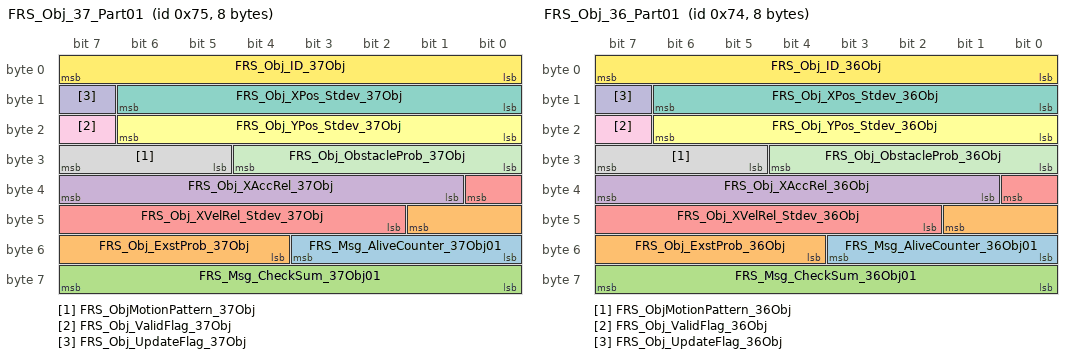
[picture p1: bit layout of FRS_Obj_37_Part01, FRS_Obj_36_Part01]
BO_ 117 FRS_Obj_37_Part01: 8 FRS
 SG_ FRS_Msg_AliveCounter_37Obj01 : 51|4@0+ (1,0) [0|15] "bit"  CAM
 SG_ FRS_Obj_ExstProb_37Obj : 41|6@0+ (1.5873,0) [0|99.9999] "%"  CAM
 SG_ FRS_Msg_CheckSum_37Obj01 : 63|8@0+ (1,0) [0|255] "bit"  CAM
 SG_ FRS_Obj_XAccRel_37Obj : 39|7@0+ (0.15,-9.6) [-9.6|9.45] "m/s2"  CAM
 SG_ FRS_Obj_XVelRel_Stdev_37Obj : 32|7@0+ (0.05,0) [0|6.35] "m/s"  CAM
 SG_ FRS_Obj_YPos_Stdev_37Obj : 22|7@0+ (0.1,0) [0|12.7] "m"  CAM
 SG_ FRS_Obj_XPos_Stdev_37Obj : 14|7@0+ (0.1,0) [0|12.7] "m"  CAM
 SG_ FRS_ObjMotionPattern_37Obj : 31|3@0+ (1,0) [0|7] "bit"  CAM
 SG_ FRS_Obj_ValidFlag_37Obj : 23|1@0+ (1,0) [0|1] "bit"  CAM
 SG_ FRS_Obj_UpdateFlag_37Obj : 15|1@0+ (1,0) [0|1] "bit"  CAM
 SG_ FRS_Obj_ObstacleProb_37Obj : 28|5@0+ (3.2258,0) [0|99.9998] "%"  CAM
 SG_ FRS_Obj_ID_37Obj : 7|8@0+ (1,0) [0|255] "bit"  CAM

BO_ 116 FRS_Obj_36_Part01: 8 FRS
 SG_ FRS_Msg_AliveCounter_36Obj01 : 51|4@0+ (1,0) [0|15] "bit"  CAM
 SG_ FRS_Obj_ExstProb_36Obj : 41|6@0+ (1.5873,0) [0|99.9999] "%"  CAM
 SG_ FRS_Msg_CheckSum_36Obj01 : 63|8@0+ (1,0) [0|255] "bit"  CAM
 SG_ FRS_Obj_XAccRel_36Obj : 39|7@0+ (0.15,-9.6) [-9.6|9.45] "m/s2"  CAM
 SG_ FRS_Obj_XVelRel_Stdev_36Obj : 32|7@0+ (0.05,0) [0|6.35] "m/s"  CAM
 SG_ FRS_Obj_YPos_Stdev_36Obj : 22|7@0+ (0.1,0) [0|12.7] "m"  CAM
 SG_ FRS_Obj_XPos_Stdev_36Obj : 14|7@0+ (0.1,0) [0|12.7] "m"  CAM
 SG_ FRS_ObjMotionPattern_36Obj : 31|3@0+ (1,0) [0|7] "bit"  CAM
 SG_ FRS_Obj_ValidFlag_36Obj : 23|1@0+ (1,0) [0|1] "bit"  CAM
 SG_ FRS_Obj_UpdateFlag_36Obj : 15|1@0+ (1,0) [0|1] "bit"  CAM
 SG_ FRS_Obj_ObstacleProb_36Obj : 28|5@0+ (3.2258,0) [0|99.9998] "%"  CAM
 SG_ FRS_Obj_ID_36Obj : 7|8@0+ (1,0) [0|255] "bit"  CAM

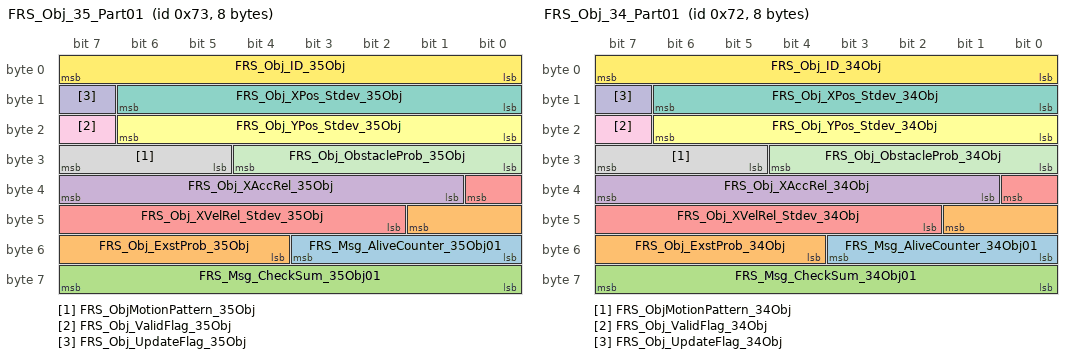
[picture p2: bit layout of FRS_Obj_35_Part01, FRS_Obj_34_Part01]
BO_ 115 FRS_Obj_35_Part01: 8 FRS
 SG_ FRS_Msg_AliveCounter_35Obj01 : 51|4@0+ (1,0) [0|15] "bit"  CAM
 SG_ FRS_Obj_ExstProb_35Obj : 41|6@0+ (1.5873,0) [0|99.9999] "%"  CAM
 SG_ FRS_Msg_CheckSum_35Obj01 : 63|8@0+ (1,0) [0|255] "bit"  CAM
 SG_ FRS_Obj_XAccRel_35Obj : 39|7@0+ (0.15,-9.6) [-9.6|9.45] "m/s2"  CAM
 SG_ FRS_Obj_XVelRel_Stdev_35Obj : 32|7@0+ (0.05,0) [0|6.35] "m/s"  CAM
 SG_ FRS_Obj_YPos_Stdev_35Obj : 22|7@0+ (0.1,0) [0|12.7] "m"  CAM
 SG_ FRS_Obj_XPos_Stdev_35Obj : 14|7@0+ (0.1,0) [0|12.7] "m"  CAM
 SG_ FRS_ObjMotionPattern_35Obj : 31|3@0+ (1,0) [0|7] "bit"  CAM
 SG_ FRS_Obj_ValidFlag_35Obj : 23|1@0+ (1,0) [0|1] "bit"  CAM
 SG_ FRS_Obj_UpdateFlag_35Obj : 15|1@0+ (1,0) [0|1] "bit"  CAM
 SG_ FRS_Obj_ObstacleProb_35Obj : 28|5@0+ (3.2258,0) [0|99.9998] "%"  CAM
 SG_ FRS_Obj_ID_35Obj : 7|8@0+ (1,0) [0|255] "bit"  CAM

BO_ 114 FRS_Obj_34_Part01: 8 FRS
 SG_ FRS_Msg_AliveCounter_34Obj01 : 51|4@0+ (1,0) [0|15] "bit"  CAM
 SG_ FRS_Obj_ExstProb_34Obj : 41|6@0+ (1.5873,0) [0|99.9999] "%"  CAM
 SG_ FRS_Msg_CheckSum_34Obj01 : 63|8@0+ (1,0) [0|255] "bit"  CAM
 SG_ FRS_Obj_XAccRel_34Obj : 39|7@0+ (0.15,-9.6) [-9.6|9.45] "m/s2"  CAM
 SG_ FRS_Obj_XVelRel_Stdev_34Obj : 32|7@0+ (0.05,0) [0|6.35] "m/s"  CAM
 SG_ FRS_Obj_YPos_Stdev_34Obj : 22|7@0+ (0.1,0) [0|12.7] "m"  CAM
 SG_ FRS_Obj_XPos_Stdev_34Obj : 14|7@0+ (0.1,0) [0|12.7] "m"  CAM
 SG_ FRS_ObjMotionPattern_34Obj : 31|3@0+ (1,0) [0|7] "bit"  CAM
 SG_ FRS_Obj_ValidFlag_34Obj : 23|1@0+ (1,0) [0|1] "bit"  CAM
 SG_ FRS_Obj_UpdateFlag_34Obj : 15|1@0+ (1,0) [0|1] "bit"  CAM
 SG_ FRS_Obj_ObstacleProb_34Obj : 28|5@0+ (3.2258,0) [0|99.9998] "%"  CAM
 SG_ FRS_Obj_ID_34Obj : 7|8@0+ (1,0) [0|255] "bit"  CAM

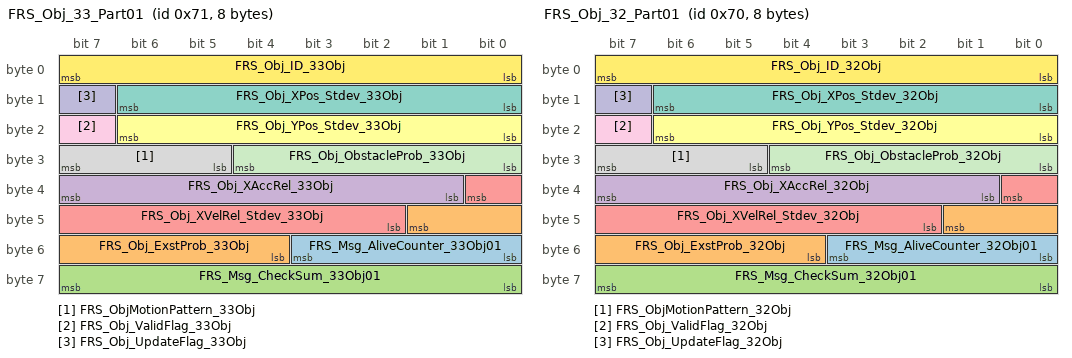
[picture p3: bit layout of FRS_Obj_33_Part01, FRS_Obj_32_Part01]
BO_ 113 FRS_Obj_33_Part01: 8 FRS
 SG_ FRS_Msg_AliveCounter_33Obj01 : 51|4@0+ (1,0) [0|15] "bit"  CAM
 SG_ FRS_Obj_ExstProb_33Obj : 41|6@0+ (1.5873,0) [0|99.9999] "%"  CAM
 SG_ FRS_Msg_CheckSum_33Obj01 : 63|8@0+ (1,0) [0|255] "bit"  CAM
 SG_ FRS_Obj_XAccRel_33Obj : 39|7@0+ (0.15,-9.6) [-9.6|9.45] "m/s2"  CAM
 SG_ FRS_Obj_XVelRel_Stdev_33Obj : 32|7@0+ (0.05,0) [0|6.35] "m/s"  CAM
 SG_ FRS_Obj_YPos_Stdev_33Obj : 22|7@0+ (0.1,0) [0|12.7] "m"  CAM
 SG_ FRS_Obj_XPos_Stdev_33Obj : 14|7@0+ (0.1,0) [0|12.7] "m"  CAM
 SG_ FRS_ObjMotionPattern_33Obj : 31|3@0+ (1,0) [0|7] "bit"  CAM
 SG_ FRS_Obj_ValidFlag_33Obj : 23|1@0+ (1,0) [0|1] "bit"  CAM
 SG_ FRS_Obj_UpdateFlag_33Obj : 15|1@0+ (1,0) [0|1] "bit"  CAM
 SG_ FRS_Obj_ObstacleProb_33Obj : 28|5@0+ (3.2258,0) [0|99.9998] "%"  CAM
 SG_ FRS_Obj_ID_33Obj : 7|8@0+ (1,0) [0|255] "bit"  CAM

BO_ 112 FRS_Obj_32_Part01: 8 FRS
 SG_ FRS_Msg_AliveCounter_32Obj01 : 51|4@0+ (1,0) [0|15] "bit"  CAM
 SG_ FRS_Obj_ExstProb_32Obj : 41|6@0+ (1.5873,0) [0|99.9999] "%"  CAM
 SG_ FRS_Msg_CheckSum_32Obj01 : 63|8@0+ (1,0) [0|255] "bit"  CAM
 SG_ FRS_Obj_XAccRel_32Obj : 39|7@0+ (0.15,-9.6) [-9.6|9.45] "m/s2"  CAM
 SG_ FRS_Obj_XVelRel_Stdev_32Obj : 32|7@0+ (0.05,0) [0|6.35] "m/s"  CAM
 SG_ FRS_Obj_YPos_Stdev_32Obj : 22|7@0+ (0.1,0) [0|12.7] "m"  CAM
 SG_ FRS_Obj_XPos_Stdev_32Obj : 14|7@0+ (0.1,0) [0|12.7] "m"  CAM
 SG_ FRS_ObjMotionPattern_32Obj : 31|3@0+ (1,0) [0|7] "bit"  CAM
 SG_ FRS_Obj_ValidFlag_32Obj : 23|1@0+ (1,0) [0|1] "bit"  CAM
 SG_ FRS_Obj_UpdateFlag_32Obj : 15|1@0+ (1,0) [0|1] "bit"  CAM
 SG_ FRS_Obj_ObstacleProb_32Obj : 28|5@0+ (3.2258,0) [0|99.9998] "%"  CAM
 SG_ FRS_Obj_ID_32Obj : 7|8@0+ (1,0) [0|255] "bit"  CAM

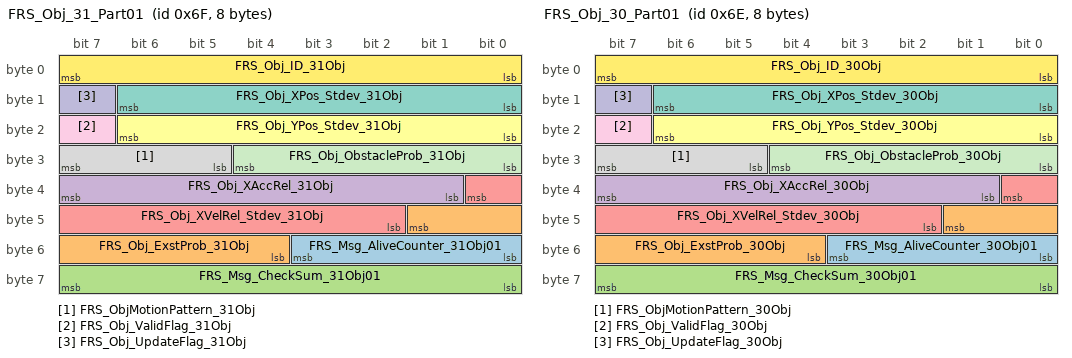
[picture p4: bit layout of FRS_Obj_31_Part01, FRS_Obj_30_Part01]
BO_ 111 FRS_Obj_31_Part01: 8 FRS
 SG_ FRS_Msg_AliveCounter_31Obj01 : 51|4@0+ (1,0) [0|15] "bit"  CAM
 SG_ FRS_Obj_ExstProb_31Obj : 41|6@0+ (1.5873,0) [0|99.9999] "%"  CAM
 SG_ FRS_Msg_CheckSum_31Obj01 : 63|8@0+ (1,0) [0|255] "bit"  CAM
 SG_ FRS_Obj_XAccRel_31Obj : 39|7@0+ (0.15,-9.6) [-9.6|9.45] "m/s2"  CAM
 SG_ FRS_Obj_XVelRel_Stdev_31Obj : 32|7@0+ (0.05,0) [0|6.35] "m/s"  CAM
 SG_ FRS_Obj_YPos_Stdev_31Obj : 22|7@0+ (0.1,0) [0|12.7] "m"  CAM
 SG_ FRS_Obj_XPos_Stdev_31Obj : 14|7@0+ (0.1,0) [0|12.7] "m"  CAM
 SG_ FRS_ObjMotionPattern_31Obj : 31|3@0+ (1,0) [0|7] "bit"  CAM
 SG_ FRS_Obj_ValidFlag_31Obj : 23|1@0+ (1,0) [0|1] "bit"  CAM
 SG_ FRS_Obj_UpdateFlag_31Obj : 15|1@0+ (1,0) [0|1] "bit"  CAM
 SG_ FRS_Obj_ObstacleProb_31Obj : 28|5@0+ (3.2258,0) [0|99.9998] "%"  CAM
 SG_ FRS_Obj_ID_31Obj : 7|8@0+ (1,0) [0|255] "bit"  CAM

BO_ 110 FRS_Obj_30_Part01: 8 FRS
 SG_ FRS_Msg_AliveCounter_30Obj01 : 51|4@0+ (1,0) [0|15] "bit"  CAM
 SG_ FRS_Obj_ExstProb_30Obj : 41|6@0+ (1.5873,0) [0|99.9999] "%"  CAM
 SG_ FRS_Msg_CheckSum_30Obj01 : 63|8@0+ (1,0) [0|255] "bit"  CAM
 SG_ FRS_Obj_XAccRel_30Obj : 39|7@0+ (0.15,-9.6) [-9.6|9.45] "m/s2"  CAM
 SG_ FRS_Obj_XVelRel_Stdev_30Obj : 32|7@0+ (0.05,0) [0|6.35] "m/s"  CAM
 SG_ FRS_Obj_YPos_Stdev_30Obj : 22|7@0+ (0.1,0) [0|12.7] "m"  CAM
 SG_ FRS_Obj_XPos_Stdev_30Obj : 14|7@0+ (0.1,0) [0|12.7] "m"  CAM
 SG_ FRS_ObjMotionPattern_30Obj : 31|3@0+ (1,0) [0|7] "bit"  CAM
 SG_ FRS_Obj_ValidFlag_30Obj : 23|1@0+ (1,0) [0|1] "bit"  CAM
 SG_ FRS_Obj_UpdateFlag_30Obj : 15|1@0+ (1,0) [0|1] "bit"  CAM
 SG_ FRS_Obj_ObstacleProb_30Obj : 28|5@0+ (3.2258,0) [0|99.9998] "%"  CAM
 SG_ FRS_Obj_ID_30Obj : 7|8@0+ (1,0) [0|255] "bit"  CAM

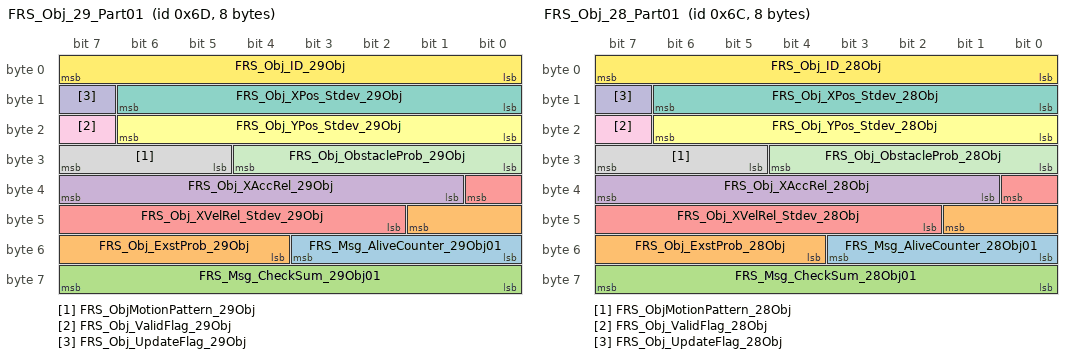
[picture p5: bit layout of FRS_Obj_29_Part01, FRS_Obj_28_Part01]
BO_ 109 FRS_Obj_29_Part01: 8 FRS
 SG_ FRS_Msg_AliveCounter_29Obj01 : 51|4@0+ (1,0) [0|15] "bit"  CAM
 SG_ FRS_Obj_ExstProb_29Obj : 41|6@0+ (1.5873,0) [0|99.9999] "%"  CAM
 SG_ FRS_Msg_CheckSum_29Obj01 : 63|8@0+ (1,0) [0|255] "bit"  CAM
 SG_ FRS_Obj_XAccRel_29Obj : 39|7@0+ (0.15,-9.6) [-9.6|9.45] "m/s2"  CAM
 SG_ FRS_Obj_XVelRel_Stdev_29Obj : 32|7@0+ (0.05,0) [0|6.35] "m/s"  CAM
 SG_ FRS_Obj_YPos_Stdev_29Obj : 22|7@0+ (0.1,0) [0|12.7] "m"  CAM
 SG_ FRS_Obj_XPos_Stdev_29Obj : 14|7@0+ (0.1,0) [0|12.7] "m"  CAM
 SG_ FRS_ObjMotionPattern_29Obj : 31|3@0+ (1,0) [0|7] "bit"  CAM
 SG_ FRS_Obj_ValidFlag_29Obj : 23|1@0+ (1,0) [0|1] "bit"  CAM
 SG_ FRS_Obj_UpdateFlag_29Obj : 15|1@0+ (1,0) [0|1] "bit"  CAM
 SG_ FRS_Obj_ObstacleProb_29Obj : 28|5@0+ (3.2258,0) [0|99.9998] "%"  CAM
 SG_ FRS_Obj_ID_29Obj : 7|8@0+ (1,0) [0|255] "bit"  CAM

BO_ 108 FRS_Obj_28_Part01: 8 FRS
 SG_ FRS_Msg_AliveCounter_28Obj01 : 51|4@0+ (1,0) [0|15] "bit"  CAM
 SG_ FRS_Obj_ExstProb_28Obj : 41|6@0+ (1.5873,0) [0|99.9999] "%"  CAM
 SG_ FRS_Msg_CheckSum_28Obj01 : 63|8@0+ (1,0) [0|255] "bit"  CAM
 SG_ FRS_Obj_XAccRel_28Obj : 39|7@0+ (0.15,-9.6) [-9.6|9.45] "m/s2"  CAM
 SG_ FRS_Obj_XVelRel_Stdev_28Obj : 32|7@0+ (0.05,0) [0|6.35] "m/s"  CAM
 SG_ FRS_Obj_YPos_Stdev_28Obj : 22|7@0+ (0.1,0) [0|12.7] "m"  CAM
 SG_ FRS_Obj_XPos_Stdev_28Obj : 14|7@0+ (0.1,0) [0|12.7] "m"  CAM
 SG_ FRS_ObjMotionPattern_28Obj : 31|3@0+ (1,0) [0|7] "bit"  CAM
 SG_ FRS_Obj_ValidFlag_28Obj : 23|1@0+ (1,0) [0|1] "bit"  CAM
 SG_ FRS_Obj_UpdateFlag_28Obj : 15|1@0+ (1,0) [0|1] "bit"  CAM
 SG_ FRS_Obj_ObstacleProb_28Obj : 28|5@0+ (3.2258,0) [0|99.9998] "%"  CAM
 SG_ FRS_Obj_ID_28Obj : 7|8@0+ (1,0) [0|255] "bit"  CAM

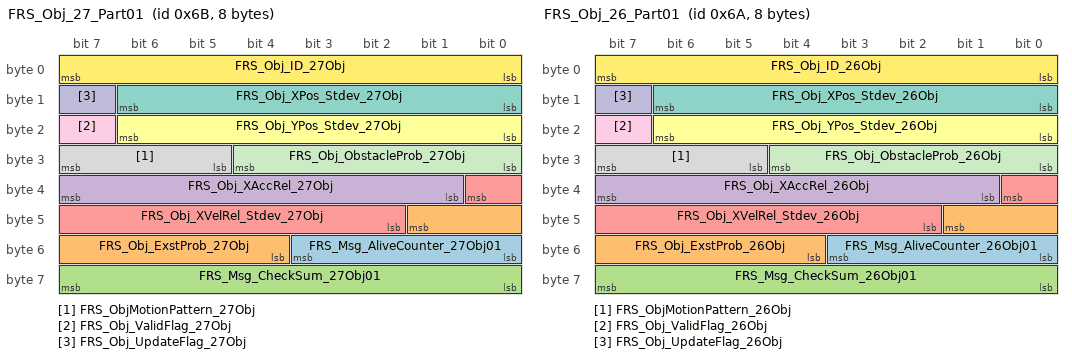
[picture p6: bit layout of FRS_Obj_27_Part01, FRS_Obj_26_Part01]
BO_ 107 FRS_Obj_27_Part01: 8 FRS
 SG_ FRS_Msg_AliveCounter_27Obj01 : 51|4@0+ (1,0) [0|15] "bit"  CAM
 SG_ FRS_Obj_ExstProb_27Obj : 41|6@0+ (1.5873,0) [0|99.9999] "%"  CAM
 SG_ FRS_Msg_CheckSum_27Obj01 : 63|8@0+ (1,0) [0|255] "bit"  CAM
 SG_ FRS_Obj_XAccRel_27Obj : 39|7@0+ (0.15,-9.6) [-9.6|9.45] "m/s2"  CAM
 SG_ FRS_Obj_XVelRel_Stdev_27Obj : 32|7@0+ (0.05,0) [0|6.35] "m/s"  CAM
 SG_ FRS_Obj_YPos_Stdev_27Obj : 22|7@0+ (0.1,0) [0|12.7] "m"  CAM
 SG_ FRS_Obj_XPos_Stdev_27Obj : 14|7@0+ (0.1,0) [0|12.7] "m"  CAM
 SG_ FRS_ObjMotionPattern_27Obj : 31|3@0+ (1,0) [0|7] "bit"  CAM
 SG_ FRS_Obj_ValidFlag_27Obj : 23|1@0+ (1,0) [0|1] "bit"  CAM
 SG_ FRS_Obj_UpdateFlag_27Obj : 15|1@0+ (1,0) [0|1] "bit"  CAM
 SG_ FRS_Obj_ObstacleProb_27Obj : 28|5@0+ (3.2258,0) [0|99.9998] "%"  CAM
 SG_ FRS_Obj_ID_27Obj : 7|8@0+ (1,0) [0|255] "bit"  CAM

BO_ 106 FRS_Obj_26_Part01: 8 FRS
 SG_ FRS_Msg_AliveCounter_26Obj01 : 51|4@0+ (1,0) [0|15] "bit"  CAM
 SG_ FRS_Obj_ExstProb_26Obj : 41|6@0+ (1.5873,0) [0|99.9999] "%"  CAM
 SG_ FRS_Msg_CheckSum_26Obj01 : 63|8@0+ (1,0) [0|255] "bit"  CAM
 SG_ FRS_Obj_XAccRel_26Obj : 39|7@0+ (0.15,-9.6) [-9.6|9.45] "m/s2"  CAM
 SG_ FRS_Obj_XVelRel_Stdev_26Obj : 32|7@0+ (0.05,0) [0|6.35] "m/s"  CAM
 SG_ FRS_Obj_YPos_Stdev_26Obj : 22|7@0+ (0.1,0) [0|12.7] "m"  CAM
 SG_ FRS_Obj_XPos_Stdev_26Obj : 14|7@0+ (0.1,0) [0|12.7] "m"  CAM
 SG_ FRS_ObjMotionPattern_26Obj : 31|3@0+ (1,0) [0|7] "bit"  CAM
 SG_ FRS_Obj_ValidFlag_26Obj : 23|1@0+ (1,0) [0|1] "bit"  CAM
 SG_ FRS_Obj_UpdateFlag_26Obj : 15|1@0+ (1,0) [0|1] "bit"  CAM
 SG_ FRS_Obj_ObstacleProb_26Obj : 28|5@0+ (3.2258,0) [0|99.9998] "%"  CAM
 SG_ FRS_Obj_ID_26Obj : 7|8@0+ (1,0) [0|255] "bit"  CAM

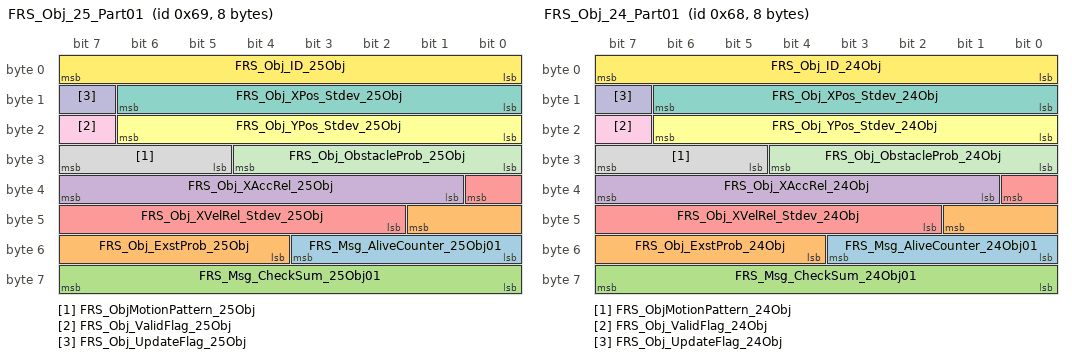
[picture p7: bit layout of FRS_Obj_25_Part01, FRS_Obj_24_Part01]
BO_ 105 FRS_Obj_25_Part01: 8 FRS
 SG_ FRS_Msg_AliveCounter_25Obj01 : 51|4@0+ (1,0) [0|15] "bit"  CAM
 SG_ FRS_Obj_ExstProb_25Obj : 41|6@0+ (1.5873,0) [0|99.9999] "%"  CAM
 SG_ FRS_Msg_CheckSum_25Obj01 : 63|8@0+ (1,0) [0|255] "bit"  CAM
 SG_ FRS_Obj_XAccRel_25Obj : 39|7@0+ (0.15,-9.6) [-9.6|9.45] "m/s2"  CAM
 SG_ FRS_Obj_XVelRel_Stdev_25Obj : 32|7@0+ (0.05,0) [0|6.35] "m/s"  CAM
 SG_ FRS_Obj_YPos_Stdev_25Obj : 22|7@0+ (0.1,0) [0|12.7] "m"  CAM
 SG_ FRS_Obj_XPos_Stdev_25Obj : 14|7@0+ (0.1,0) [0|12.7] "m"  CAM
 SG_ FRS_ObjMotionPattern_25Obj : 31|3@0+ (1,0) [0|7] "bit"  CAM
 SG_ FRS_Obj_ValidFlag_25Obj : 23|1@0+ (1,0) [0|1] "bit"  CAM
 SG_ FRS_Obj_UpdateFlag_25Obj : 15|1@0+ (1,0) [0|1] "bit"  CAM
 SG_ FRS_Obj_ObstacleProb_25Obj : 28|5@0+ (3.2258,0) [0|99.9998] "%"  CAM
 SG_ FRS_Obj_ID_25Obj : 7|8@0+ (1,0) [0|255] "bit"  CAM

BO_ 104 FRS_Obj_24_Part01: 8 FRS
 SG_ FRS_Msg_AliveCounter_24Obj01 : 51|4@0+ (1,0) [0|15] "bit"  CAM
 SG_ FRS_Obj_ExstProb_24Obj : 41|6@0+ (1.5873,0) [0|99.9999] "%"  CAM
 SG_ FRS_Msg_CheckSum_24Obj01 : 63|8@0+ (1,0) [0|255] "bit"  CAM
 SG_ FRS_Obj_XAccRel_24Obj : 39|7@0+ (0.15,-9.6) [-9.6|9.45] "m/s2"  CAM
 SG_ FRS_Obj_XVelRel_Stdev_24Obj : 32|7@0+ (0.05,0) [0|6.35] "m/s"  CAM
 SG_ FRS_Obj_YPos_Stdev_24Obj : 22|7@0+ (0.1,0) [0|12.7] "m"  CAM
 SG_ FRS_Obj_XPos_Stdev_24Obj : 14|7@0+ (0.1,0) [0|12.7] "m"  CAM
 SG_ FRS_ObjMotionPattern_24Obj : 31|3@0+ (1,0) [0|7] "bit"  CAM
 SG_ FRS_Obj_ValidFlag_24Obj : 23|1@0+ (1,0) [0|1] "bit"  CAM
 SG_ FRS_Obj_UpdateFlag_24Obj : 15|1@0+ (1,0) [0|1] "bit"  CAM
 SG_ FRS_Obj_ObstacleProb_24Obj : 28|5@0+ (3.2258,0) [0|99.9998] "%"  CAM
 SG_ FRS_Obj_ID_24Obj : 7|8@0+ (1,0) [0|255] "bit"  CAM

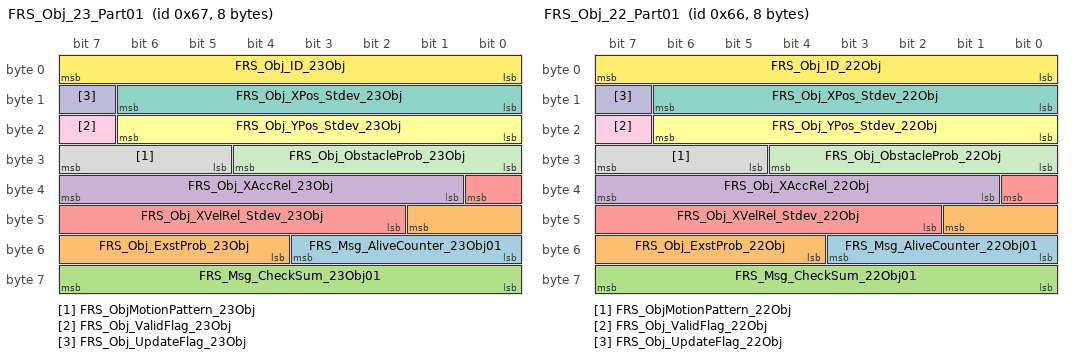
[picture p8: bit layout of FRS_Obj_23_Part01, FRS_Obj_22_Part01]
BO_ 103 FRS_Obj_23_Part01: 8 FRS
 SG_ FRS_Msg_AliveCounter_23Obj01 : 51|4@0+ (1,0) [0|15] "bit"  CAM
 SG_ FRS_Obj_ExstProb_23Obj : 41|6@0+ (1.5873,0) [0|99.9999] "%"  CAM
 SG_ FRS_Msg_CheckSum_23Obj01 : 63|8@0+ (1,0) [0|255] "bit"  CAM
 SG_ FRS_Obj_XAccRel_23Obj : 39|7@0+ (0.15,-9.6) [-9.6|9.45] "m/s2"  CAM
 SG_ FRS_Obj_XVelRel_Stdev_23Obj : 32|7@0+ (0.05,0) [0|6.35] "m/s"  CAM
 SG_ FRS_Obj_YPos_Stdev_23Obj : 22|7@0+ (0.1,0) [0|12.7] "m"  CAM
 SG_ FRS_Obj_XPos_Stdev_23Obj : 14|7@0+ (0.1,0) [0|12.7] "m"  CAM
 SG_ FRS_ObjMotionPattern_23Obj : 31|3@0+ (1,0) [0|7] "bit"  CAM
 SG_ FRS_Obj_ValidFlag_23Obj : 23|1@0+ (1,0) [0|1] "bit"  CAM
 SG_ FRS_Obj_UpdateFlag_23Obj : 15|1@0+ (1,0) [0|1] "bit"  CAM
 SG_ FRS_Obj_ObstacleProb_23Obj : 28|5@0+ (3.2258,0) [0|99.9998] "%"  CAM
 SG_ FRS_Obj_ID_23Obj : 7|8@0+ (1,0) [0|255] "bit"  CAM

BO_ 102 FRS_Obj_22_Part01: 8 FRS
 SG_ FRS_Msg_AliveCounter_22Obj01 : 51|4@0+ (1,0) [0|15] "bit"  CAM
 SG_ FRS_Obj_ExstProb_22Obj : 41|6@0+ (1.5873,0) [0|99.9999] "%"  CAM
 SG_ FRS_Msg_CheckSum_22Obj01 : 63|8@0+ (1,0) [0|255] "bit"  CAM
 SG_ FRS_Obj_XAccRel_22Obj : 39|7@0+ (0.15,-9.6) [-9.6|9.45] "m/s2"  CAM
 SG_ FRS_Obj_XVelRel_Stdev_22Obj : 32|7@0+ (0.05,0) [0|6.35] "m/s"  CAM
 SG_ FRS_Obj_YPos_Stdev_22Obj : 22|7@0+ (0.1,0) [0|12.7] "m"  CAM
 SG_ FRS_Obj_XPos_Stdev_22Obj : 14|7@0+ (0.1,0) [0|12.7] "m"  CAM
 SG_ FRS_ObjMotionPattern_22Obj : 31|3@0+ (1,0) [0|7] "bit"  CAM
 SG_ FRS_Obj_ValidFlag_22Obj : 23|1@0+ (1,0) [0|1] "bit"  CAM
 SG_ FRS_Obj_UpdateFlag_22Obj : 15|1@0+ (1,0) [0|1] "bit"  CAM
 SG_ FRS_Obj_ObstacleProb_22Obj : 28|5@0+ (3.2258,0) [0|99.9998] "%"  CAM
 SG_ FRS_Obj_ID_22Obj : 7|8@0+ (1,0) [0|255] "bit"  CAM

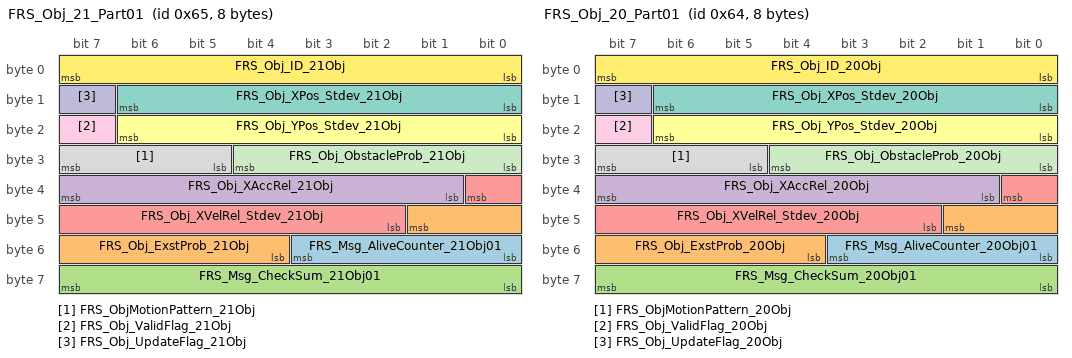
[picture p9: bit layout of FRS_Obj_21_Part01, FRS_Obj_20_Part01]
BO_ 101 FRS_Obj_21_Part01: 8 FRS
 SG_ FRS_Msg_AliveCounter_21Obj01 : 51|4@0+ (1,0) [0|15] "bit"  CAM
 SG_ FRS_Obj_ExstProb_21Obj : 41|6@0+ (1.5873,0) [0|99.9999] "%"  CAM
 SG_ FRS_Msg_CheckSum_21Obj01 : 63|8@0+ (1,0) [0|255] "bit"  CAM
 SG_ FRS_Obj_XAccRel_21Obj : 39|7@0+ (0.15,-9.6) [-9.6|9.45] "m/s2"  CAM
 SG_ FRS_Obj_XVelRel_Stdev_21Obj : 32|7@0+ (0.05,0) [0|6.35] "m/s"  CAM
 SG_ FRS_Obj_YPos_Stdev_21Obj : 22|7@0+ (0.1,0) [0|12.7] "m"  CAM
 SG_ FRS_Obj_XPos_Stdev_21Obj : 14|7@0+ (0.1,0) [0|12.7] "m"  CAM
 SG_ FRS_ObjMotionPattern_21Obj : 31|3@0+ (1,0) [0|7] "bit"  CAM
 SG_ FRS_Obj_ValidFlag_21Obj : 23|1@0+ (1,0) [0|1] "bit"  CAM
 SG_ FRS_Obj_UpdateFlag_21Obj : 15|1@0+ (1,0) [0|1] "bit"  CAM
 SG_ FRS_Obj_ObstacleProb_21Obj : 28|5@0+ (3.2258,0) [0|99.9998] "%"  CAM
 SG_ FRS_Obj_ID_21Obj : 7|8@0+ (1,0) [0|255] "bit"  CAM

BO_ 100 FRS_Obj_20_Part01: 8 FRS
 SG_ FRS_Msg_AliveCounter_20Obj01 : 51|4@0+ (1,0) [0|15] "bit"  CAM
 SG_ FRS_Obj_ExstProb_20Obj : 41|6@0+ (1.5873,0) [0|99.9999] "%"  CAM
 SG_ FRS_Msg_CheckSum_20Obj01 : 63|8@0+ (1,0) [0|255] "bit"  CAM
 SG_ FRS_Obj_XAccRel_20Obj : 39|7@0+ (0.15,-9.6) [-9.6|9.45] "m/s2"  CAM
 SG_ FRS_Obj_XVelRel_Stdev_20Obj : 32|7@0+ (0.05,0) [0|6.35] "m/s"  CAM
 SG_ FRS_Obj_YPos_Stdev_20Obj : 22|7@0+ (0.1,0) [0|12.7] "m"  CAM
 SG_ FRS_Obj_XPos_Stdev_20Obj : 14|7@0+ (0.1,0) [0|12.7] "m"  CAM
 SG_ FRS_ObjMotionPattern_20Obj : 31|3@0+ (1,0) [0|7] "bit"  CAM
 SG_ FRS_Obj_ValidFlag_20Obj : 23|1@0+ (1,0) [0|1] "bit"  CAM
 SG_ FRS_Obj_UpdateFlag_20Obj : 15|1@0+ (1,0) [0|1] "bit"  CAM
 SG_ FRS_Obj_ObstacleProb_20Obj : 28|5@0+ (3.2258,0) [0|99.9998] "%"  CAM
 SG_ FRS_Obj_ID_20Obj : 7|8@0+ (1,0) [0|255] "bit"  CAM

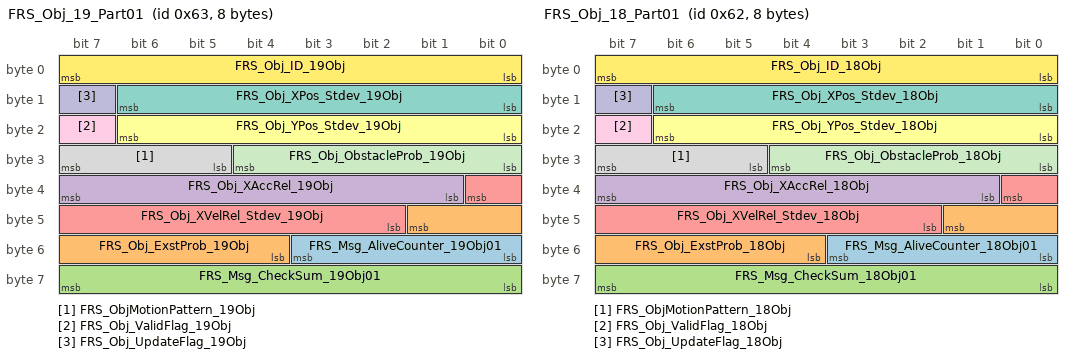
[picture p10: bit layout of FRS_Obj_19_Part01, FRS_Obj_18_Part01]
BO_ 99 FRS_Obj_19_Part01: 8 FRS
 SG_ FRS_Msg_AliveCounter_19Obj01 : 51|4@0+ (1,0) [0|15] "bit"  CAM
 SG_ FRS_Obj_ExstProb_19Obj : 41|6@0+ (1.5873,0) [0|99.9999] "%"  CAM
 SG_ FRS_Msg_CheckSum_19Obj01 : 63|8@0+ (1,0) [0|255] "bit"  CAM
 SG_ FRS_Obj_XAccRel_19Obj : 39|7@0+ (0.15,-9.6) [-9.6|9.45] "m/s2"  CAM
 SG_ FRS_Obj_XVelRel_Stdev_19Obj : 32|7@0+ (0.05,0) [0|6.35] "m/s"  CAM
 SG_ FRS_Obj_YPos_Stdev_19Obj : 22|7@0+ (0.1,0) [0|12.7] "m"  CAM
 SG_ FRS_Obj_XPos_Stdev_19Obj : 14|7@0+ (0.1,0) [0|12.7] "m"  CAM
 SG_ FRS_ObjMotionPattern_19Obj : 31|3@0+ (1,0) [0|7] "bit"  CAM
 SG_ FRS_Obj_ValidFlag_19Obj : 23|1@0+ (1,0) [0|1] "bit"  CAM
 SG_ FRS_Obj_UpdateFlag_19Obj : 15|1@0+ (1,0) [0|1] "bit"  CAM
 SG_ FRS_Obj_ObstacleProb_19Obj : 28|5@0+ (3.2258,0) [0|99.9998] "%"  CAM
 SG_ FRS_Obj_ID_19Obj : 7|8@0+ (1,0) [0|255] "bit"  CAM

BO_ 98 FRS_Obj_18_Part01: 8 FRS
 SG_ FRS_Msg_AliveCounter_18Obj01 : 51|4@0+ (1,0) [0|15] "bit"  CAM
 SG_ FRS_Obj_ExstProb_18Obj : 41|6@0+ (1.5873,0) [0|99.9999] "%"  CAM
 SG_ FRS_Msg_CheckSum_18Obj01 : 63|8@0+ (1,0) [0|255] "bit"  CAM
 SG_ FRS_Obj_XAccRel_18Obj : 39|7@0+ (0.15,-9.6) [-9.6|9.45] "m/s2"  CAM
 SG_ FRS_Obj_XVelRel_Stdev_18Obj : 32|7@0+ (0.05,0) [0|6.35] "m/s"  CAM
 SG_ FRS_Obj_YPos_Stdev_18Obj : 22|7@0+ (0.1,0) [0|12.7] "m"  CAM
 SG_ FRS_Obj_XPos_Stdev_18Obj : 14|7@0+ (0.1,0) [0|12.7] "m"  CAM
 SG_ FRS_ObjMotionPattern_18Obj : 31|3@0+ (1,0) [0|7] "bit"  CAM
 SG_ FRS_Obj_ValidFlag_18Obj : 23|1@0+ (1,0) [0|1] "bit"  CAM
 SG_ FRS_Obj_UpdateFlag_18Obj : 15|1@0+ (1,0) [0|1] "bit"  CAM
 SG_ FRS_Obj_ObstacleProb_18Obj : 28|5@0+ (3.2258,0) [0|99.9998] "%"  CAM
 SG_ FRS_Obj_ID_18Obj : 7|8@0+ (1,0) [0|255] "bit"  CAM

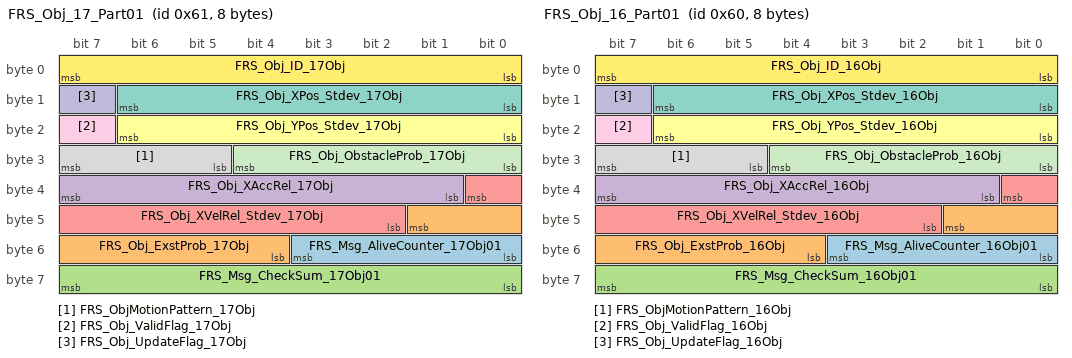
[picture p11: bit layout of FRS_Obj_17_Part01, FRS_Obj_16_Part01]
BO_ 97 FRS_Obj_17_Part01: 8 FRS
 SG_ FRS_Msg_AliveCounter_17Obj01 : 51|4@0+ (1,0) [0|15] "bit"  CAM
 SG_ FRS_Obj_ExstProb_17Obj : 41|6@0+ (1.5873,0) [0|99.9999] "%"  CAM
 SG_ FRS_Msg_CheckSum_17Obj01 : 63|8@0+ (1,0) [0|255] "bit"  CAM
 SG_ FRS_Obj_XAccRel_17Obj : 39|7@0+ (0.15,-9.6) [-9.6|9.45] "m/s2"  CAM
 SG_ FRS_Obj_XVelRel_Stdev_17Obj : 32|7@0+ (0.05,0) [0|6.35] "m/s"  CAM
 SG_ FRS_Obj_YPos_Stdev_17Obj : 22|7@0+ (0.1,0) [0|12.7] "m"  CAM
 SG_ FRS_Obj_XPos_Stdev_17Obj : 14|7@0+ (0.1,0) [0|12.7] "m"  CAM
 SG_ FRS_ObjMotionPattern_17Obj : 31|3@0+ (1,0) [0|7] "bit"  CAM
 SG_ FRS_Obj_ValidFlag_17Obj : 23|1@0+ (1,0) [0|1] "bit"  CAM
 SG_ FRS_Obj_UpdateFlag_17Obj : 15|1@0+ (1,0) [0|1] "bit"  CAM
 SG_ FRS_Obj_ObstacleProb_17Obj : 28|5@0+ (3.2258,0) [0|99.9998] "%"  CAM
 SG_ FRS_Obj_ID_17Obj : 7|8@0+ (1,0) [0|255] "bit"  CAM

BO_ 96 FRS_Obj_16_Part01: 8 FRS
 SG_ FRS_Msg_AliveCounter_16Obj01 : 51|4@0+ (1,0) [0|15] "bit"  CAM
 SG_ FRS_Obj_ExstProb_16Obj : 41|6@0+ (1.5873,0) [0|99.9999] "%"  CAM
 SG_ FRS_Msg_CheckSum_16Obj01 : 63|8@0+ (1,0) [0|255] "bit"  CAM
 SG_ FRS_Obj_XAccRel_16Obj : 39|7@0+ (0.15,-9.6) [-9.6|9.45] "m/s2"  CAM
 SG_ FRS_Obj_XVelRel_Stdev_16Obj : 32|7@0+ (0.05,0) [0|6.35] "m/s"  CAM
 SG_ FRS_Obj_YPos_Stdev_16Obj : 22|7@0+ (0.1,0) [0|12.7] "m"  CAM
 SG_ FRS_Obj_XPos_Stdev_16Obj : 14|7@0+ (0.1,0) [0|12.7] "m"  CAM
 SG_ FRS_ObjMotionPattern_16Obj : 31|3@0+ (1,0) [0|7] "bit"  CAM
 SG_ FRS_Obj_ValidFlag_16Obj : 23|1@0+ (1,0) [0|1] "bit"  CAM
 SG_ FRS_Obj_UpdateFlag_16Obj : 15|1@0+ (1,0) [0|1] "bit"  CAM
 SG_ FRS_Obj_ObstacleProb_16Obj : 28|5@0+ (3.2258,0) [0|99.9998] "%"  CAM
 SG_ FRS_Obj_ID_16Obj : 7|8@0+ (1,0) [0|255] "bit"  CAM

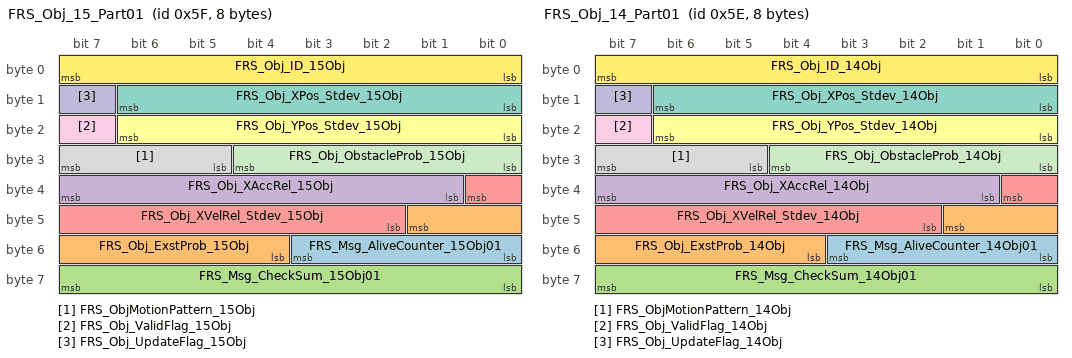
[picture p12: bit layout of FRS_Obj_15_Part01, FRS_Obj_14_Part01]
BO_ 95 FRS_Obj_15_Part01: 8 FRS
 SG_ FRS_Msg_AliveCounter_15Obj01 : 51|4@0+ (1,0) [0|15] "bit"  CAM
 SG_ FRS_Obj_ExstProb_15Obj : 41|6@0+ (1.5873,0) [0|99.9999] "%"  CAM
 SG_ FRS_Msg_CheckSum_15Obj01 : 63|8@0+ (1,0) [0|255] "bit"  CAM
 SG_ FRS_Obj_XAccRel_15Obj : 39|7@0+ (0.15,-9.6) [-9.6|9.45] "m/s2"  CAM
 SG_ FRS_Obj_XVelRel_Stdev_15Obj : 32|7@0+ (0.05,0) [0|6.35] "m/s"  CAM
 SG_ FRS_Obj_YPos_Stdev_15Obj : 22|7@0+ (0.1,0) [0|12.7] "m"  CAM
 SG_ FRS_Obj_XPos_Stdev_15Obj : 14|7@0+ (0.1,0) [0|12.7] "m"  CAM
 SG_ FRS_ObjMotionPattern_15Obj : 31|3@0+ (1,0) [0|7] "bit"  CAM
 SG_ FRS_Obj_ValidFlag_15Obj : 23|1@0+ (1,0) [0|1] "bit"  CAM
 SG_ FRS_Obj_UpdateFlag_15Obj : 15|1@0+ (1,0) [0|1] "bit"  CAM
 SG_ FRS_Obj_ObstacleProb_15Obj : 28|5@0+ (3.2258,0) [0|99.9998] "%"  CAM
 SG_ FRS_Obj_ID_15Obj : 7|8@0+ (1,0) [0|255] "bit"  CAM

BO_ 94 FRS_Obj_14_Part01: 8 FRS
 SG_ FRS_Msg_AliveCounter_14Obj01 : 51|4@0+ (1,0) [0|15] "bit"  CAM
 SG_ FRS_Obj_ExstProb_14Obj : 41|6@0+ (1.5873,0) [0|99.9999] "%"  CAM
 SG_ FRS_Msg_CheckSum_14Obj01 : 63|8@0+ (1,0) [0|255] "bit"  CAM
 SG_ FRS_Obj_XAccRel_14Obj : 39|7@0+ (0.15,-9.6) [-9.6|9.45] "m/s2"  CAM
 SG_ FRS_Obj_XVelRel_Stdev_14Obj : 32|7@0+ (0.05,0) [0|6.35] "m/s"  CAM
 SG_ FRS_Obj_YPos_Stdev_14Obj : 22|7@0+ (0.1,0) [0|12.7] "m"  CAM
 SG_ FRS_Obj_XPos_Stdev_14Obj : 14|7@0+ (0.1,0) [0|12.7] "m"  CAM
 SG_ FRS_ObjMotionPattern_14Obj : 31|3@0+ (1,0) [0|7] "bit"  CAM
 SG_ FRS_Obj_ValidFlag_14Obj : 23|1@0+ (1,0) [0|1] "bit"  CAM
 SG_ FRS_Obj_UpdateFlag_14Obj : 15|1@0+ (1,0) [0|1] "bit"  CAM
 SG_ FRS_Obj_ObstacleProb_14Obj : 28|5@0+ (3.2258,0) [0|99.9998] "%"  CAM
 SG_ FRS_Obj_ID_14Obj : 7|8@0+ (1,0) [0|255] "bit"  CAM

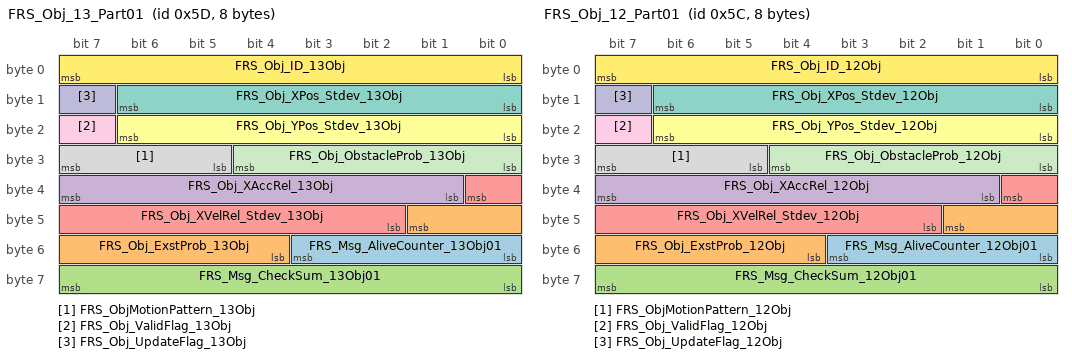
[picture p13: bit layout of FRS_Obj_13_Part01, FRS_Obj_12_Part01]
BO_ 93 FRS_Obj_13_Part01: 8 FRS
 SG_ FRS_Msg_AliveCounter_13Obj01 : 51|4@0+ (1,0) [0|15] "bit"  CAM
 SG_ FRS_Obj_ExstProb_13Obj : 41|6@0+ (1.5873,0) [0|99.9999] "%"  CAM
 SG_ FRS_Msg_CheckSum_13Obj01 : 63|8@0+ (1,0) [0|255] "bit"  CAM
 SG_ FRS_Obj_XAccRel_13Obj : 39|7@0+ (0.15,-9.6) [-9.6|9.45] "m/s2"  CAM
 SG_ FRS_Obj_XVelRel_Stdev_13Obj : 32|7@0+ (0.05,0) [0|6.35] "m/s"  CAM
 SG_ FRS_Obj_YPos_Stdev_13Obj : 22|7@0+ (0.1,0) [0|12.7] "m"  CAM
 SG_ FRS_Obj_XPos_Stdev_13Obj : 14|7@0+ (0.1,0) [0|12.7] "m"  CAM
 SG_ FRS_ObjMotionPattern_13Obj : 31|3@0+ (1,0) [0|7] "bit"  CAM
 SG_ FRS_Obj_ValidFlag_13Obj : 23|1@0+ (1,0) [0|1] "bit"  CAM
 SG_ FRS_Obj_UpdateFlag_13Obj : 15|1@0+ (1,0) [0|1] "bit"  CAM
 SG_ FRS_Obj_ObstacleProb_13Obj : 28|5@0+ (3.2258,0) [0|99.9998] "%"  CAM
 SG_ FRS_Obj_ID_13Obj : 7|8@0+ (1,0) [0|255] "bit"  CAM

BO_ 92 FRS_Obj_12_Part01: 8 FRS
 SG_ FRS_Msg_AliveCounter_12Obj01 : 51|4@0+ (1,0) [0|15] "bit"  CAM
 SG_ FRS_Obj_ExstProb_12Obj : 41|6@0+ (1.5873,0) [0|99.9999] "%"  CAM
 SG_ FRS_Msg_CheckSum_12Obj01 : 63|8@0+ (1,0) [0|255] "bit"  CAM
 SG_ FRS_Obj_XAccRel_12Obj : 39|7@0+ (0.15,-9.6) [-9.6|9.45] "m/s2"  CAM
 SG_ FRS_Obj_XVelRel_Stdev_12Obj : 32|7@0+ (0.05,0) [0|6.35] "m/s"  CAM
 SG_ FRS_Obj_YPos_Stdev_12Obj : 22|7@0+ (0.1,0) [0|12.7] "m"  CAM
 SG_ FRS_Obj_XPos_Stdev_12Obj : 14|7@0+ (0.1,0) [0|12.7] "m"  CAM
 SG_ FRS_ObjMotionPattern_12Obj : 31|3@0+ (1,0) [0|7] "bit"  CAM
 SG_ FRS_Obj_ValidFlag_12Obj : 23|1@0+ (1,0) [0|1] "bit"  CAM
 SG_ FRS_Obj_UpdateFlag_12Obj : 15|1@0+ (1,0) [0|1] "bit"  CAM
 SG_ FRS_Obj_ObstacleProb_12Obj : 28|5@0+ (3.2258,0) [0|99.9998] "%"  CAM
 SG_ FRS_Obj_ID_12Obj : 7|8@0+ (1,0) [0|255] "bit"  CAM

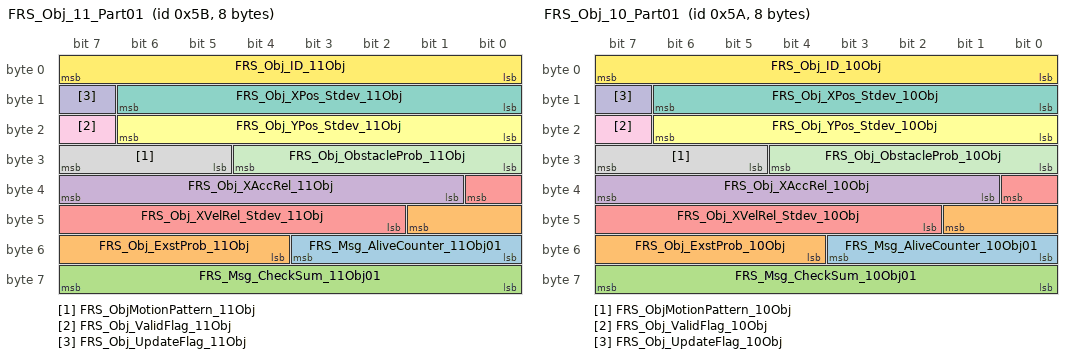
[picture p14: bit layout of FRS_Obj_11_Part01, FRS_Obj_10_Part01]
BO_ 91 FRS_Obj_11_Part01: 8 FRS
 SG_ FRS_Msg_AliveCounter_11Obj01 : 51|4@0+ (1,0) [0|15] "bit"  CAM
 SG_ FRS_Obj_ExstProb_11Obj : 41|6@0+ (1.5873,0) [0|99.9999] "%"  CAM
 SG_ FRS_Msg_CheckSum_11Obj01 : 63|8@0+ (1,0) [0|255] "bit"  CAM
 SG_ FRS_Obj_XAccRel_11Obj : 39|7@0+ (0.15,-9.6) [-9.6|9.45] "m/s2"  CAM
 SG_ FRS_Obj_XVelRel_Stdev_11Obj : 32|7@0+ (0.05,0) [0|6.35] "m/s"  CAM
 SG_ FRS_Obj_YPos_Stdev_11Obj : 22|7@0+ (0.1,0) [0|12.7] "m"  CAM
 SG_ FRS_Obj_XPos_Stdev_11Obj : 14|7@0+ (0.1,0) [0|12.7] "m"  CAM
 SG_ FRS_ObjMotionPattern_11Obj : 31|3@0+ (1,0) [0|7] "bit"  CAM
 SG_ FRS_Obj_ValidFlag_11Obj : 23|1@0+ (1,0) [0|1] "bit"  CAM
 SG_ FRS_Obj_UpdateFlag_11Obj : 15|1@0+ (1,0) [0|1] "bit"  CAM
 SG_ FRS_Obj_ObstacleProb_11Obj : 28|5@0+ (3.2258,0) [0|99.9998] "%"  CAM
 SG_ FRS_Obj_ID_11Obj : 7|8@0+ (1,0) [0|255] "bit"  CAM

BO_ 90 FRS_Obj_10_Part01: 8 FRS
 SG_ FRS_Msg_AliveCounter_10Obj01 : 51|4@0+ (1,0) [0|15] "bit"  CAM
 SG_ FRS_Obj_ExstProb_10Obj : 41|6@0+ (1.5873,0) [0|99.9999] "%"  CAM
 SG_ FRS_Msg_CheckSum_10Obj01 : 63|8@0+ (1,0) [0|255] "bit"  CAM
 SG_ FRS_Obj_XAccRel_10Obj : 39|7@0+ (0.15,-9.6) [-9.6|9.45] "m/s2"  CAM
 SG_ FRS_Obj_XVelRel_Stdev_10Obj : 32|7@0+ (0.05,0) [0|6.35] "m/s"  CAM
 SG_ FRS_Obj_YPos_Stdev_10Obj : 22|7@0+ (0.1,0) [0|12.7] "m"  CAM
 SG_ FRS_Obj_XPos_Stdev_10Obj : 14|7@0+ (0.1,0) [0|12.7] "m"  CAM
 SG_ FRS_ObjMotionPattern_10Obj : 31|3@0+ (1,0) [0|7] "bit"  CAM
 SG_ FRS_Obj_ValidFlag_10Obj : 23|1@0+ (1,0) [0|1] "bit"  CAM
 SG_ FRS_Obj_UpdateFlag_10Obj : 15|1@0+ (1,0) [0|1] "bit"  CAM
 SG_ FRS_Obj_ObstacleProb_10Obj : 28|5@0+ (3.2258,0) [0|99.9998] "%"  CAM
 SG_ FRS_Obj_ID_10Obj : 7|8@0+ (1,0) [0|255] "bit"  CAM

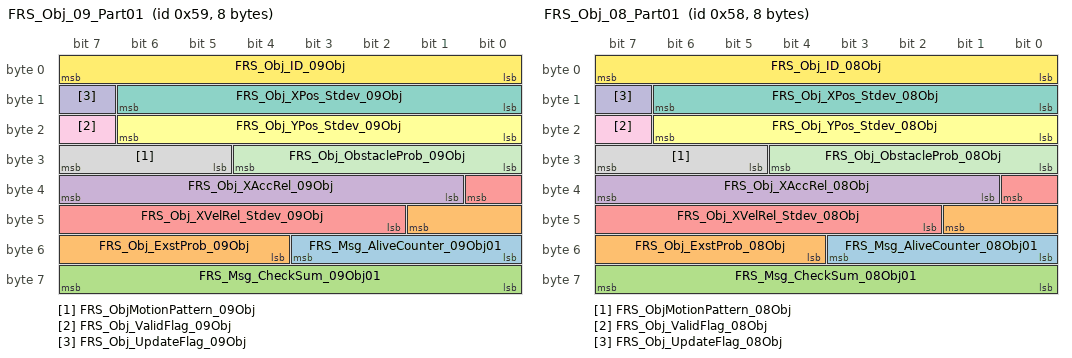
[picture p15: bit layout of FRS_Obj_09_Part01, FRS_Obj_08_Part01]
BO_ 89 FRS_Obj_09_Part01: 8 FRS
 SG_ FRS_Msg_AliveCounter_09Obj01 : 51|4@0+ (1,0) [0|15] "bit"  CAM
 SG_ FRS_Obj_ExstProb_09Obj : 41|6@0+ (1.5873,0) [0|99.9999] "%"  CAM
 SG_ FRS_Msg_CheckSum_09Obj01 : 63|8@0+ (1,0) [0|255] "bit"  CAM
 SG_ FRS_Obj_XAccRel_09Obj : 39|7@0+ (0.15,-9.6) [-9.6|9.45] "m/s2"  CAM
 SG_ FRS_Obj_XVelRel_Stdev_09Obj : 32|7@0+ (0.05,0) [0|6.35] "m/s"  CAM
 SG_ FRS_Obj_YPos_Stdev_09Obj : 22|7@0+ (0.1,0) [0|12.7] "m"  CAM
 SG_ FRS_Obj_XPos_Stdev_09Obj : 14|7@0+ (0.1,0) [0|12.7] "m"  CAM
 SG_ FRS_ObjMotionPattern_09Obj : 31|3@0+ (1,0) [0|7] "bit"  CAM
 SG_ FRS_Obj_ValidFlag_09Obj : 23|1@0+ (1,0) [0|1] "bit"  CAM
 SG_ FRS_Obj_UpdateFlag_09Obj : 15|1@0+ (1,0) [0|1] "bit"  CAM
 SG_ FRS_Obj_ObstacleProb_09Obj : 28|5@0+ (3.2258,0) [0|99.9998] "%"  CAM
 SG_ FRS_Obj_ID_09Obj : 7|8@0+ (1,0) [0|255] "bit"  CAM

BO_ 88 FRS_Obj_08_Part01: 8 FRS
 SG_ FRS_Msg_AliveCounter_08Obj01 : 51|4@0+ (1,0) [0|15] "bit"  CAM
 SG_ FRS_Obj_ExstProb_08Obj : 41|6@0+ (1.5873,0) [0|99.9999] "%"  CAM
 SG_ FRS_Msg_CheckSum_08Obj01 : 63|8@0+ (1,0) [0|255] "bit"  CAM
 SG_ FRS_Obj_XAccRel_08Obj : 39|7@0+ (0.15,-9.6) [-9.6|9.45] "m/s2"  CAM
 SG_ FRS_Obj_XVelRel_Stdev_08Obj : 32|7@0+ (0.05,0) [0|6.35] "m/s"  CAM
 SG_ FRS_Obj_YPos_Stdev_08Obj : 22|7@0+ (0.1,0) [0|12.7] "m"  CAM
 SG_ FRS_Obj_XPos_Stdev_08Obj : 14|7@0+ (0.1,0) [0|12.7] "m"  CAM
 SG_ FRS_ObjMotionPattern_08Obj : 31|3@0+ (1,0) [0|7] "bit"  CAM
 SG_ FRS_Obj_ValidFlag_08Obj : 23|1@0+ (1,0) [0|1] "bit"  CAM
 SG_ FRS_Obj_UpdateFlag_08Obj : 15|1@0+ (1,0) [0|1] "bit"  CAM
 SG_ FRS_Obj_ObstacleProb_08Obj : 28|5@0+ (3.2258,0) [0|99.9998] "%"  CAM
 SG_ FRS_Obj_ID_08Obj : 7|8@0+ (1,0) [0|255] "bit"  CAM

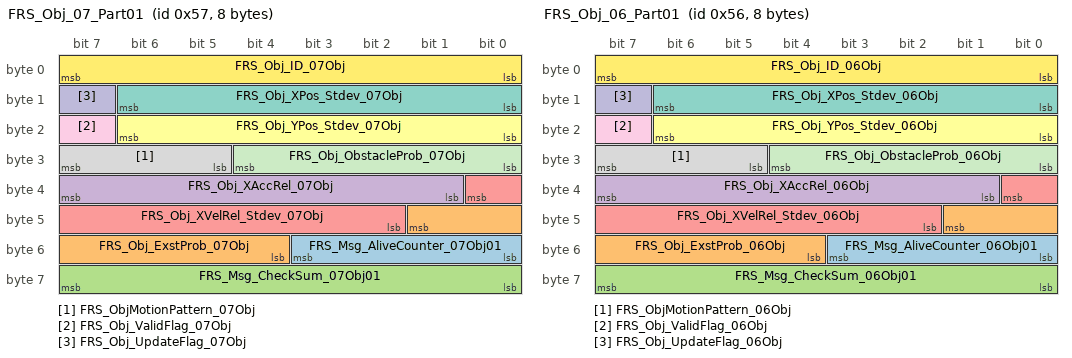
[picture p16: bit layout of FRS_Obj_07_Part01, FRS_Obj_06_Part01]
BO_ 87 FRS_Obj_07_Part01: 8 FRS
 SG_ FRS_Msg_AliveCounter_07Obj01 : 51|4@0+ (1,0) [0|15] "bit"  CAM
 SG_ FRS_Obj_ExstProb_07Obj : 41|6@0+ (1.5873,0) [0|99.9999] "%"  CAM
 SG_ FRS_Msg_CheckSum_07Obj01 : 63|8@0+ (1,0) [0|255] "bit"  CAM
 SG_ FRS_Obj_XAccRel_07Obj : 39|7@0+ (0.15,-9.6) [-9.6|9.45] "m/s2"  CAM
 SG_ FRS_Obj_XVelRel_Stdev_07Obj : 32|7@0+ (0.05,0) [0|6.35] "m/s"  CAM
 SG_ FRS_Obj_YPos_Stdev_07Obj : 22|7@0+ (0.1,0) [0|12.7] "m"  CAM
 SG_ FRS_Obj_XPos_Stdev_07Obj : 14|7@0+ (0.1,0) [0|12.7] "m"  CAM
 SG_ FRS_ObjMotionPattern_07Obj : 31|3@0+ (1,0) [0|7] "bit"  CAM
 SG_ FRS_Obj_ValidFlag_07Obj : 23|1@0+ (1,0) [0|1] "bit"  CAM
 SG_ FRS_Obj_UpdateFlag_07Obj : 15|1@0+ (1,0) [0|1] "bit"  CAM
 SG_ FRS_Obj_ObstacleProb_07Obj : 28|5@0+ (3.2258,0) [0|99.9998] "%"  CAM
 SG_ FRS_Obj_ID_07Obj : 7|8@0+ (1,0) [0|255] "bit"  CAM

BO_ 86 FRS_Obj_06_Part01: 8 FRS
 SG_ FRS_Msg_AliveCounter_06Obj01 : 51|4@0+ (1,0) [0|15] "bit"  CAM
 SG_ FRS_Obj_ExstProb_06Obj : 41|6@0+ (1.5873,0) [0|99.9999] "%"  CAM
 SG_ FRS_Msg_CheckSum_06Obj01 : 63|8@0+ (1,0) [0|255] "bit"  CAM
 SG_ FRS_Obj_XAccRel_06Obj : 39|7@0+ (0.15,-9.6) [-9.6|9.45] "m/s2"  CAM
 SG_ FRS_Obj_XVelRel_Stdev_06Obj : 32|7@0+ (0.05,0) [0|6.35] "m/s"  CAM
 SG_ FRS_Obj_YPos_Stdev_06Obj : 22|7@0+ (0.1,0) [0|12.7] "m"  CAM
 SG_ FRS_Obj_XPos_Stdev_06Obj : 14|7@0+ (0.1,0) [0|12.7] "m"  CAM
 SG_ FRS_ObjMotionPattern_06Obj : 31|3@0+ (1,0) [0|7] "bit"  CAM
 SG_ FRS_Obj_ValidFlag_06Obj : 23|1@0+ (1,0) [0|1] "bit"  CAM
 SG_ FRS_Obj_UpdateFlag_06Obj : 15|1@0+ (1,0) [0|1] "bit"  CAM
 SG_ FRS_Obj_ObstacleProb_06Obj : 28|5@0+ (3.2258,0) [0|99.9998] "%"  CAM
 SG_ FRS_Obj_ID_06Obj : 7|8@0+ (1,0) [0|255] "bit"  CAM

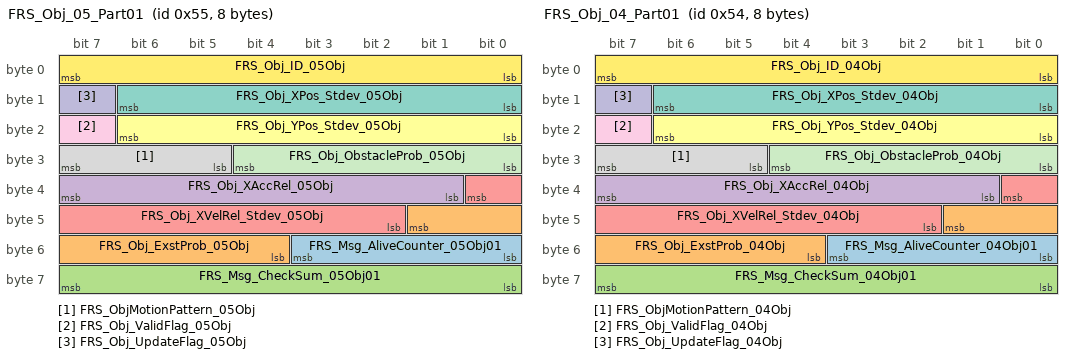
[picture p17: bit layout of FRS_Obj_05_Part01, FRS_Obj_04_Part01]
BO_ 85 FRS_Obj_05_Part01: 8 FRS
 SG_ FRS_Msg_AliveCounter_05Obj01 : 51|4@0+ (1,0) [0|15] "bit"  CAM
 SG_ FRS_Obj_ExstProb_05Obj : 41|6@0+ (1.5873,0) [0|99.9999] "%"  CAM
 SG_ FRS_Msg_CheckSum_05Obj01 : 63|8@0+ (1,0) [0|255] "bit"  CAM
 SG_ FRS_Obj_XAccRel_05Obj : 39|7@0+ (0.15,-9.6) [-9.6|9.45] "m/s2"  CAM
 SG_ FRS_Obj_XVelRel_Stdev_05Obj : 32|7@0+ (0.05,0) [0|6.35] "m/s"  CAM
 SG_ FRS_Obj_YPos_Stdev_05Obj : 22|7@0+ (0.1,0) [0|12.7] "m"  CAM
 SG_ FRS_Obj_XPos_Stdev_05Obj : 14|7@0+ (0.1,0) [0|12.7] "m"  CAM
 SG_ FRS_ObjMotionPattern_05Obj : 31|3@0+ (1,0) [0|7] "bit"  CAM
 SG_ FRS_Obj_ValidFlag_05Obj : 23|1@0+ (1,0) [0|1] "bit"  CAM
 SG_ FRS_Obj_UpdateFlag_05Obj : 15|1@0+ (1,0) [0|1] "bit"  CAM
 SG_ FRS_Obj_ObstacleProb_05Obj : 28|5@0+ (3.2258,0) [0|99.9998] "%"  CAM
 SG_ FRS_Obj_ID_05Obj : 7|8@0+ (1,0) [0|255] "bit"  CAM

BO_ 84 FRS_Obj_04_Part01: 8 FRS
 SG_ FRS_Msg_AliveCounter_04Obj01 : 51|4@0+ (1,0) [0|15] "bit"  CAM
 SG_ FRS_Obj_ExstProb_04Obj : 41|6@0+ (1.5873,0) [0|99.9999] "%"  CAM
 SG_ FRS_Msg_CheckSum_04Obj01 : 63|8@0+ (1,0) [0|255] "bit"  CAM
 SG_ FRS_Obj_XAccRel_04Obj : 39|7@0+ (0.15,-9.6) [-9.6|9.45] "m/s2"  CAM
 SG_ FRS_Obj_XVelRel_Stdev_04Obj : 32|7@0+ (0.05,0) [0|6.35] "m/s"  CAM
 SG_ FRS_Obj_YPos_Stdev_04Obj : 22|7@0+ (0.1,0) [0|12.7] "m"  CAM
 SG_ FRS_Obj_XPos_Stdev_04Obj : 14|7@0+ (0.1,0) [0|12.7] "m"  CAM
 SG_ FRS_ObjMotionPattern_04Obj : 31|3@0+ (1,0) [0|7] "bit"  CAM
 SG_ FRS_Obj_ValidFlag_04Obj : 23|1@0+ (1,0) [0|1] "bit"  CAM
 SG_ FRS_Obj_UpdateFlag_04Obj : 15|1@0+ (1,0) [0|1] "bit"  CAM
 SG_ FRS_Obj_ObstacleProb_04Obj : 28|5@0+ (3.2258,0) [0|99.9998] "%"  CAM
 SG_ FRS_Obj_ID_04Obj : 7|8@0+ (1,0) [0|255] "bit"  CAM

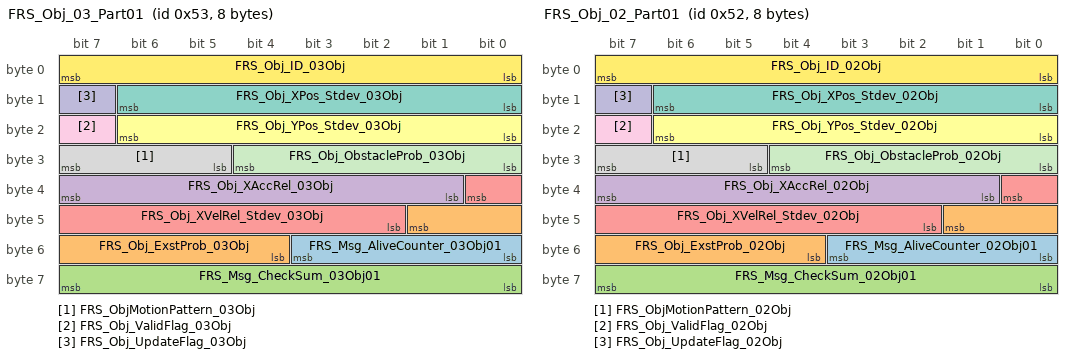
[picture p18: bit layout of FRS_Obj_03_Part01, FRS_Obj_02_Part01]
BO_ 83 FRS_Obj_03_Part01: 8 FRS
 SG_ FRS_Msg_AliveCounter_03Obj01 : 51|4@0+ (1,0) [0|15] "bit"  CAM
 SG_ FRS_Obj_ExstProb_03Obj : 41|6@0+ (1.5873,0) [0|99.9999] "%"  CAM
 SG_ FRS_Msg_CheckSum_03Obj01 : 63|8@0+ (1,0) [0|255] "bit"  CAM
 SG_ FRS_Obj_XAccRel_03Obj : 39|7@0+ (0.15,-9.6) [-9.6|9.45] "m/s2"  CAM
 SG_ FRS_Obj_XVelRel_Stdev_03Obj : 32|7@0+ (0.05,0) [0|6.35] "m/s"  CAM
 SG_ FRS_Obj_YPos_Stdev_03Obj : 22|7@0+ (0.1,0) [0|12.7] "m"  CAM
 SG_ FRS_Obj_XPos_Stdev_03Obj : 14|7@0+ (0.1,0) [0|12.7] "m"  CAM
 SG_ FRS_ObjMotionPattern_03Obj : 31|3@0+ (1,0) [0|7] "bit"  CAM
 SG_ FRS_Obj_ValidFlag_03Obj : 23|1@0+ (1,0) [0|1] "bit"  CAM
 SG_ FRS_Obj_UpdateFlag_03Obj : 15|1@0+ (1,0) [0|1] "bit"  CAM
 SG_ FRS_Obj_ObstacleProb_03Obj : 28|5@0+ (3.2258,0) [0|99.9998] "%"  CAM
 SG_ FRS_Obj_ID_03Obj : 7|8@0+ (1,0) [0|255] "bit"  CAM

BO_ 82 FRS_Obj_02_Part01: 8 FRS
 SG_ FRS_Msg_AliveCounter_02Obj01 : 51|4@0+ (1,0) [0|15] "bit"  CAM
 SG_ FRS_Obj_ExstProb_02Obj : 41|6@0+ (1.5873,0) [0|99.9999] "%"  CAM
 SG_ FRS_Msg_CheckSum_02Obj01 : 63|8@0+ (1,0) [0|255] "bit"  CAM
 SG_ FRS_Obj_XAccRel_02Obj : 39|7@0+ (0.15,-9.6) [-9.6|9.45] "m/s2"  CAM
 SG_ FRS_Obj_XVelRel_Stdev_02Obj : 32|7@0+ (0.05,0) [0|6.35] "m/s"  CAM
 SG_ FRS_Obj_YPos_Stdev_02Obj : 22|7@0+ (0.1,0) [0|12.7] "m"  CAM
 SG_ FRS_Obj_XPos_Stdev_02Obj : 14|7@0+ (0.1,0) [0|12.7] "m"  CAM
 SG_ FRS_ObjMotionPattern_02Obj : 31|3@0+ (1,0) [0|7] "bit"  CAM
 SG_ FRS_Obj_ValidFlag_02Obj : 23|1@0+ (1,0) [0|1] "bit"  CAM
 SG_ FRS_Obj_UpdateFlag_02Obj : 15|1@0+ (1,0) [0|1] "bit"  CAM
 SG_ FRS_Obj_ObstacleProb_02Obj : 28|5@0+ (3.2258,0) [0|99.9998] "%"  CAM
 SG_ FRS_Obj_ID_02Obj : 7|8@0+ (1,0) [0|255] "bit"  CAM

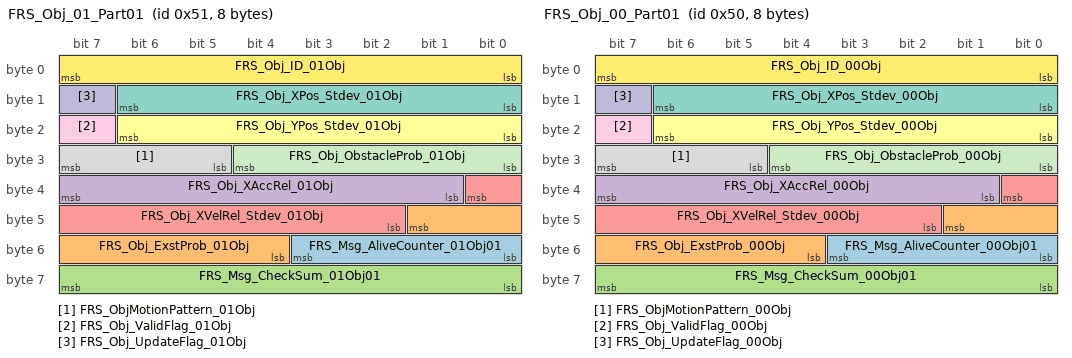
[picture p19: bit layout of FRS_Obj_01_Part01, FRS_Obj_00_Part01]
BO_ 81 FRS_Obj_01_Part01: 8 FRS
 SG_ FRS_Msg_AliveCounter_01Obj01 : 51|4@0+ (1,0) [0|15] "bit"  CAM
 SG_ FRS_Obj_ExstProb_01Obj : 41|6@0+ (1.5873,0) [0|99.9999] "%"  CAM
 SG_ FRS_Msg_CheckSum_01Obj01 : 63|8@0+ (1,0) [0|255] "bit"  CAM
 SG_ FRS_Obj_XAccRel_01Obj : 39|7@0+ (0.15,-9.6) [-9.6|9.45] "m/s2"  CAM
 SG_ FRS_Obj_XVelRel_Stdev_01Obj : 32|7@0+ (0.05,0) [0|6.35] "m/s"  CAM
 SG_ FRS_Obj_YPos_Stdev_01Obj : 22|7@0+ (0.1,0) [0|12.7] "m"  CAM
 SG_ FRS_Obj_XPos_Stdev_01Obj : 14|7@0+ (0.1,0) [0|12.7] "m"  CAM
 SG_ FRS_ObjMotionPattern_01Obj : 31|3@0+ (1,0) [0|7] "bit"  CAM
 SG_ FRS_Obj_ValidFlag_01Obj : 23|1@0+ (1,0) [0|1] "bit"  CAM
 SG_ FRS_Obj_UpdateFlag_01Obj : 15|1@0+ (1,0) [0|1] "bit"  CAM
 SG_ FRS_Obj_ObstacleProb_01Obj : 28|5@0+ (3.2258,0) [0|99.9998] "%"  CAM
 SG_ FRS_Obj_ID_01Obj : 7|8@0+ (1,0) [0|255] "bit"  CAM

BO_ 32 FRS_Obj_00_Part02: 8 FRS
 SG_ FRS_Msg_CheckSum_00Obj02 : 63|8@0+ (1,0) [0|255] "bit"  CAM
 SG_ FRS_Msg_AliveCounter_00Obj02 : 51|4@0+ (1,0) [0|15] "bit"  CAM
 SG_ FRS_Obj_Type_00Obj : 33|2@0+ (1,0) [0|3] "bit"  CAM
 SG_ FRS_Obj_MeasFlag_00Obj : 52|1@0+ (1,0) [0|1] "bit"  CAM
 SG_ FRS_Obj_YVelRel_00Obj : 47|11@0+ (0.1,-102.4) [-102.4|102.3] "m/s"  CAM
 SG_ FRS_Obj_XVelRel_00Obj : 7|11@0+ (0.1,-102.4) [-102.4|102.3] "m/s"  CAM
 SG_ FRS_Obj_YPos_00Obj : 12|13@0+ (0.015625,-64) [-64|63.984375] "m"  CAM
 SG_ FRS_Obj_XPos_00Obj : 31|14@0+ (0.015625,0) [0|255.984375] "m"  CAM

BO_ 80 FRS_Obj_00_Part01: 8 FRS
 SG_ FRS_Msg_AliveCounter_00Obj01 : 51|4@0+ (1,0) [0|15] "bit"  CAM
 SG_ FRS_Obj_ExstProb_00Obj : 41|6@0+ (1.5873,0) [0|99.9999] "%"  CAM
 SG_ FRS_Msg_CheckSum_00Obj01 : 63|8@0+ (1,0) [0|255] "bit"  CAM
 SG_ FRS_Obj_XAccRel_00Obj : 39|7@0+ (0.15,-9.6) [-9.6|9.45] "m/s2"  CAM
 SG_ FRS_Obj_XVelRel_Stdev_00Obj : 32|7@0+ (0.05,0) [0|6.35] "m/s"  CAM
 SG_ FRS_Obj_YPos_Stdev_00Obj : 22|7@0+ (0.1,0) [0|12.7] "m"  CAM
 SG_ FRS_Obj_XPos_Stdev_00Obj : 14|7@0+ (0.1,0) [0|12.7] "m"  CAM
 SG_ FRS_ObjMotionPattern_00Obj : 31|3@0+ (1,0) [0|7] "bit"  CAM
 SG_ FRS_Obj_ValidFlag_00Obj : 23|1@0+ (1,0) [0|1] "bit"  CAM
 SG_ FRS_Obj_UpdateFlag_00Obj : 15|1@0+ (1,0) [0|1] "bit"  CAM
 SG_ FRS_Obj_ObstacleProb_00Obj : 28|5@0+ (3.2258,0) [0|99.9998] "%"  CAM
 SG_ FRS_Obj_ID_00Obj : 7|8@0+ (1,0) [0|255] "bit"  CAM

BO_ 128 FRS_Status: 8 FRS
 SG_ FRS_Status_HWErr : 55|1@0+ (1,0) [0|1] "bit"  CAM
 SG_ FRS_Status_BlkProg : 40|1@0+ (1,0) [0|1] "bit"  CAM
 SG_ FRS_Status_MisAlign : 54|3@0+ (1,0) [0|7] "bit"  CAM
 SG_ FRS_Fail : 41|1@0+ (1,0) [0|1] "bit"  CAM
 SG_ FRS_MeasEnabled : 42|1@0+ (1,0) [0|1] "bit"  CAM
 SG_ FRS_Host_Yaw : 37|11@0+ (0.1,-102.4) [-102.4|102.3] "deg/s"  CAM
 SG_ FRS_HostSpeed : 17|12@0+ (0.025,-20) [-20|82.375] "m/s"  CAM
 SG_ FRS_TimeStamp : 1|16@0+ (1,0) [0|65535] "s"  CAM
 SG_ FRS_Latency : 7|6@0+ (3,0) [0|189] "ms"  CAM
 SG_ FRS_Msg_CheckSum : 63|8@0+ (1,0) [0|255] "bit"  CAM
 SG_ FRS_Msg_AliveCounter : 51|4@0+ (1,0) [0|15] "bit"  CAM

BO_ 1074 NWM_FRS: 8 FRS
 SG_ FRS_AWB : 12|1@0+ (1,0) [0|1] "bit" Vector__XXX
 SG_ FRS_Address : 7|8@0+ (1,0) [0|127] "bit" Vector__XXX
 SG_ FRS_RMR : 8|1@0+ (1,0) [0|1] "bit" Vector__XXX
 SG_ FRS_NMSts : 24|1@0+ (1,0) [0|1] "bit" Vector__XXX
 SG_ FRS_Stayawake_reasons : 39|32@0+ (1,0) [0|127] "bit" Vector__XXX
 SG_ FRS_Wakeup_reasons : 23|8@0+ (1,0) [0|255] "bit" Vector__XXX

BO_ 291 ESC_RearWheelSpeedsKPH: 8 ESC
 SG_ ESC_RWheelSpeedsKPH_CheckSum : 63|8@0+ (1,0) [0|255] "bit"  FRS
 SG_ ESC_RWheelSpeedsKPH_AliveCounter : 51|4@0+ (1,0) [0|15] "bit"  FRS
 SG_ ESC_RRWheelSpeedKPH : 23|13@0+ (0.05625,0) [0|460.63125] "KPH"  FRS
 SG_ ESC_RRWheelSpeedInvalid : 24|1@0+ (1,0) [0|1] "bit"  FRS
 SG_ ESC_RRWheelDirection : 26|2@0+ (1,0) [0|3] "bit"  FRS
 SG_ ESC_RLWheelSpeedKPH : 7|13@0+ (0.05625,0) [0|460.63125] "KPH"  FRS
 SG_ ESC_RLWheelDirection : 10|2@0+ (1,0) [0|3] "bit"  FRS
 SG_ ESC_RLWheelSpeedInvalid : 8|1@0+ (1,0) [0|1] "bit"  FRS

BO_ 290 ESC_FrontWheelSpeedsKPH: 8 ESC
 SG_ ESC_FWheelSpeedsKPH_CheckSum : 63|8@0+ (1,0) [0|255] "bit"  FRS
 SG_ ESC_FWheelSpeedsKPH_AliveCounter : 51|4@0+ (1,0) [0|15] "bit"  FRS
 SG_ ESC_FRWheelDirection : 26|2@0+ (1,0) [0|3] "bit"  FRS
 SG_ ESC_FRWheelSpeedInvalid : 24|1@0+ (1,0) [0|1] "bit"  FRS
 SG_ ESC_FRWheelSpeedKPH : 23|13@0+ (0.05625,0) [0|460.63125] "KPH"  FRS
 SG_ ESC_FLWheelDirection : 10|2@0+ (1,0) [0|3] "bit"  FRS
 SG_ ESC_FLWheelSpeedInvalid : 8|1@0+ (1,0) [0|1] "bit"  FRS
 SG_ ESC_FLWheelSpeedKPH : 7|13@0+ (0.05625,0) [0|460.63125] "KPH"  FRS

BO_ 2015 Func_DiagReq: 8 GW
 SG_ Func_DiagReq_RXNpdu : 7|64@0+ (1,0) [0|0] ""  FRS

BO_ 804 AlvBlMsg_TX: 8 FRS
 SG_ AlvBlMsg_TXNpdu : 7|64@0+ (1,0) [0|0] ""  GW

BO_ 1010 AlvBlMsg_RX: 8 GW
 SG_ AlvBlMsg_RXNpdu : 7|64@0+ (1,0) [0|0] ""  FRS

BO_ 1704 DevelopMessage_TX: 8 FRS
 SG_ DevelopMessage_TXNpdu : 7|64@0+ (1,0) [0|0] ""  TESTER

BO_ 1696 DevelopMessage_RX: 8 TESTER
 SG_ DevelopMessage_RXNpdu : 7|64@0+ (1,0) [0|0] ""  FRS

BO_ 357 VCU_ModeControl: 8 VCU
 SG_ VCU_ModeControl_CheckSum : 63|8@0+ (1,0) [0|255] "bit"  FRS
 SG_ VCU_ModeControl_AliveCounter : 51|4@0+ (1,0) [0|15] "bit"  FRS
 SG_ VCU_CurrentGearPosition : 23|4@0+ (1,0) [0|15] "bit"  FRS

BO_ 304 YRS1: 8 ACU
 SG_ YRS_LateralSensorState : 12|2@0+ (1,0) [0|3] "bit"  FRS
 SG_ YRS1_CheckSum : 7|8@0+ (1,0) [0|255] "bit"  FRS
 SG_ YRS_LateralAcce : 23|16@0+ (0.001,-2) [-2|2] "g"  FRS
 SG_ YRS_YawRate : 39|16@0+ (0.01,-180) [-180|180] "°/s"  FRS
 SG_ YRS1_AliveCounter : 59|4@0+ (1,0) [0|15] "bit"  FRS
 SG_ YRS_YawRateSensorState : 10|2@0+ (1,0) [0|3] "bit"  FRS

BO_ 305 YRS2: 8 ACU
 SG_ YRS_LongitSensorState : 15|2@0+ (1,0) [0|3] "bit"  FRS
 SG_ YRS2_CheckSum : 7|8@0+ (1,0) [0|255] "bit"  FRS
 SG_ YRS_LongitAcce : 23|16@0+ (0.001,-2) [-2|2] "g"  FRS
 SG_ YRS2_AliveCounter : 59|4@0+ (1,0) [0|15] "bit"  FRS

BO_ 224 SAS_Status: 8 TCM
 SG_ SAS_FailureSts : 31|1@0+ (1,0) [0|1] "bit"  FRS
 SG_ SAS_Status_AliveCounter : 39|4@0+ (1,0) [0|15] "bit"  FRS
 SG_ SAS_Status_CheckSum : 47|8@0+ (1,0) [0|255] "bit"  FRS
 SG_ SAS_SteerWheelAngle : 7|16@0- (0.1,0) [-780|779.9] "°/bit"  FRS

BO_ 293 ESC_Status: 8 ESC
 SG_ ESC_VehicleSpeedInvalid : 18|1@0+ (1,0) [0|1] "bit"  FRS
 SG_ ESC_VehicleSpeed : 15|13@0+ (0.05625,0) [0|460.63125] "KPH"  FRS
 SG_ ESC_Status_AliveCounter : 51|4@0+ (1,0) [0|15] "bit"  FRS
 SG_ ESC_Status_CheckSum : 63|8@0+ (1,0) [0|255] "bit"  FRS

BO_ 133 EMS_EngineRPM: 8 GW
 SG_ EMS_EngineRPM_AliveCounter : 63|4@0+ (1,0) [0|15] "bit"  FRS
 SG_ EMS_EngineRPM_CheckSum : 39|8@0+ (1,0) [0|255] "bit"  FRS
 SG_ EMS_EngStatus : 47|3@0+ (1,0) [0|7] "bit"  FRS

BO_ 275 TCU_Status: 8 GW
 SG_ TCU_Status_AliveCounter : 51|4@0+ (1,0) [0|15] "bit"  FRS
 SG_ TCU_CurrentGearPosition : 39|4@0+ (1,0) [0|15] "bit"  FRS
 SG_ TCU_Status_CheckSum : 63|8@0+ (1,0) [0|255] "bit"  FRS

BO_ 608 IPK_SettingRequest: 8 GW
 SG_ IPK_AEB_FCWSenlevel : 15|2@0+ (1,0) [0|3] "bit"  FRS
 SG_ IPK_ALOD_ControlTypeReq : 7|2@0+ (1,0) [0|3] "bit"  FRS
 SG_ IPK_AEB_AEBStateReq : 3|2@0+ (1,0) [0|3] "bit"  FRS
 SG_ IPK_AEB_FCWStateReq : 1|2@0+ (1,0) [0|3] "bit"  FRS

BO_ 1009 IPK_TotalOdometer: 8 GW
 SG_ IPK_IPKTotalOdometer : 7|24@0+ (0.1,0) [0|999999] "KM"  FRS

CM_ " ";
CM_ BO_ 304 "Transmitted by ACU , including ACU YRS signals";
CM_ SG_ 304 YRS1_CheckSum "YRS1_Checksum";
CM_ SG_ 304 YRS_LateralAcce "Indicates Lateral Acceleration
0x0FA1~0xFFFF: Invalid";
CM_ SG_ 304 YRS_YawRate "Indicates Yaw Rate
0x8CA1~0xFFFF: Invalid";
CM_ SG_ 304 YRS1_AliveCounter "Indicates the message sending number";
CM_ SG_ 304 YRS_YawRateSensorState "Indicates YawRate Sensor State";
CM_ BO_ 305 "Transmitted by ACU , including ACU YRS signals";
CM_ SG_ 305 YRS2_CheckSum "YRS2_CheckSum";
CM_ SG_ 305 YRS_LongitAcce "Indicates Longitudinal Acceleration
0x0FA1~0xFFFF: Invalid";
CM_ SG_ 305 YRS2_AliveCounter "Indicates the message sending number";
CM_ BO_ 224 "Transmitted by SAS, including SAS sensor status singals";
CM_ SG_ 224 SAS_FailureSts "SAS failure status";
CM_ SG_ 224 SAS_Status_AliveCounter "Message counter";
CM_ SG_ 224 SAS_Status_CheckSum "SAS_Status checksum ";
CM_ SG_ 224 SAS_SteerWheelAngle "Actual steering wheel angle";
CM_ BO_ 293 "Transmitted by ESC, including ESC status ,Vehicle Speed and Brake switch status";
CM_ SG_ 293 ESC_VehicleSpeedInvalid "Signal from ABS_ESC to indicate if VehicleSpeed is valid";
CM_ SG_ 293 ESC_VehicleSpeed "Vehicle Speed";
CM_ SG_ 293 ESC_Status_AliveCounter "Message Rolling counter";
CM_ SG_ 293 ESC_Status_CheckSum "ESC_Status checksum ";
CM_ BO_ 133 "Transmitted by EMS, including RPM and accel. padel position status";
CM_ SG_ 133 EMS_EngStatus "Engine running status";
CM_ BO_ 275 "Transmitted by TCU, including TCU req and states";
CM_ SG_ 275 TCU_CurrentGearPosition "TCU current Gear status";
CM_ SG_ 275 TCU_Status_CheckSum "TCU_Status checksum ";
CM_ BO_ 608 "Transmitted by IPK, including IPK for FRS, FCS command signal";
CM_ BO_ 1009 "Transmitted by IPK , including Total Odometer";
CM_ SG_ 1009 IPK_IPKTotalOdometer "The total odometer displayed in IPK";
BA_DEF_  "NmAsrWaitBusSleepTime" INT 0 65535;
BA_DEF_  "NmAsrTimeoutTime" INT 0 65535;
BA_DEF_  "NmAsrRepeatMessageTime" INT 0 65535;
BA_DEF_ BU_  "NmAsrNodeIdentifier" INT 0 255;
BA_DEF_ BU_  "NmAsrNode" ENUM  "no","yes";
BA_DEF_  "NmAsrMessageCount" INT 0 256;
BA_DEF_ BO_  "NmAsrMessage" ENUM  "no","yes";
BA_DEF_ BU_  "NmAsrCanMsgReducedTime" INT 0 65535;
BA_DEF_  "NmAsrCanMsgCycleTime" INT 0 65535;
BA_DEF_  "NmAsrBaseAddress" HEX 0 65535;
BA_DEF_ BO_  "DiagState" ENUM  "No","Yes";
BA_DEF_ BO_  "DiagRequest" ENUM  "No","Yes";
BA_DEF_ BO_  "GenMsgSendType" ENUM  "Cyclic","NotUsed","NotUsed","NotUsed","NotUsed","NotUsed","NotUsed","NotUsed","NoMsgSendType";
BA_DEF_ BO_  "GenMsgCycleTime" INT 0 0;
BA_DEF_ SG_  "GenSigSendType" ENUM  "Cyclic","OnWrite","NotUsed","OnChange","NotUsed","NotUsed","NotUsed","NoSigSendType";
BA_DEF_ SG_  "GenSigStartValue" INT 0 0;
BA_DEF_ SG_  "GenSigInactiveValue" INT 0 0;
BA_DEF_  "DBName" STRING ;
BA_DEF_ BU_  "NodeLayerModules" STRING ;
BA_DEF_ BU_  "ILUsed" ENUM  "No","Yes";
BA_DEF_  "Manufacturer" STRING ;
BA_DEF_  "NmType" STRING ;
BA_DEF_ BO_  "GenMsgILSupport" ENUM  "No","Yes";
BA_DEF_  "BusType" STRING ;
BA_DEF_DEF_  "NmAsrWaitBusSleepTime" 750;
BA_DEF_DEF_  "NmAsrTimeoutTime" 1000;
BA_DEF_DEF_  "NmAsrRepeatMessageTime" 400;
BA_DEF_DEF_  "NmAsrNodeIdentifier" 0;
BA_DEF_DEF_  "NmAsrNode" "yes";
BA_DEF_DEF_  "NmAsrMessageCount" 64;
BA_DEF_DEF_  "NmAsrMessage" "no";
BA_DEF_DEF_  "NmAsrCanMsgReducedTime" 50;
BA_DEF_DEF_  "NmAsrCanMsgCycleTime" 100;
BA_DEF_DEF_  "NmAsrBaseAddress" 1024;
BA_DEF_DEF_  "DiagState" "No";
BA_DEF_DEF_  "DiagRequest" "No";
BA_DEF_DEF_  "GenMsgSendType" "NoMsgSendType";
BA_DEF_DEF_  "GenMsgCycleTime" 0;
BA_DEF_DEF_  "GenSigSendType" "Cyclic";
BA_DEF_DEF_  "GenSigStartValue" 0;
BA_DEF_DEF_  "GenSigInactiveValue" 0;
BA_DEF_DEF_  "DBName" "";
BA_DEF_DEF_  "NodeLayerModules" "CANoeILNLVector.dll";
BA_DEF_DEF_  "ILUsed" "Yes";
BA_DEF_DEF_  "Manufacturer" "";
BA_DEF_DEF_  "NmType" "";
BA_DEF_DEF_  "GenMsgILSupport" "Yes";
BA_DEF_DEF_  "BusType" "CAN";
BA_ "NmAsrCanMsgCycleTime" 500;
BA_ "NmAsrRepeatMessageTime" 1600;
BA_ "NmAsrTimeoutTime" 2000;
BA_ "NmAsrWaitBusSleepTime" 2000;
BA_ "NmType" "NmAsr";
BA_ "Manufacturer" "vector";
BA_ "DBName" "FS11Public";
BA_ "NmAsrNodeIdentifier" BU_ FRS 40;
BA_ "NmAsrCanMsgReducedTime" BU_ FRS 250;
BA_ "GenMsgCycleTime" BO_ 71 50;
BA_ "GenMsgSendType" BO_ 71 0;
BA_ "GenMsgCycleTime" BO_ 70 50;
BA_ "GenMsgSendType" BO_ 70 0;
BA_ "GenMsgCycleTime" BO_ 69 50;
BA_ "GenMsgSendType" BO_ 69 0;
BA_ "GenMsgCycleTime" BO_ 68 50;
BA_ "GenMsgSendType" BO_ 68 0;
BA_ "GenMsgCycleTime" BO_ 67 50;
BA_ "GenMsgSendType" BO_ 67 0;
BA_ "GenMsgCycleTime" BO_ 66 50;
BA_ "GenMsgSendType" BO_ 66 0;
BA_ "GenMsgCycleTime" BO_ 65 50;
BA_ "GenMsgSendType" BO_ 65 0;
BA_ "GenMsgCycleTime" BO_ 64 50;
BA_ "GenMsgSendType" BO_ 64 0;
BA_ "GenMsgCycleTime" BO_ 63 50;
BA_ "GenMsgSendType" BO_ 63 0;
BA_ "GenMsgCycleTime" BO_ 62 50;
BA_ "GenMsgSendType" BO_ 62 0;
BA_ "GenMsgCycleTime" BO_ 61 50;
BA_ "GenMsgSendType" BO_ 61 0;
BA_ "GenMsgCycleTime" BO_ 60 50;
BA_ "GenMsgSendType" BO_ 60 0;
BA_ "GenMsgCycleTime" BO_ 59 50;
BA_ "GenMsgSendType" BO_ 59 0;
BA_ "GenMsgCycleTime" BO_ 58 50;
BA_ "GenMsgSendType" BO_ 58 0;
BA_ "GenMsgCycleTime" BO_ 57 50;
BA_ "GenMsgSendType" BO_ 57 0;
BA_ "GenMsgCycleTime" BO_ 56 50;
BA_ "GenMsgSendType" BO_ 56 0;
BA_ "GenMsgCycleTime" BO_ 55 50;
BA_ "GenMsgSendType" BO_ 55 0;
BA_ "GenMsgCycleTime" BO_ 54 50;
BA_ "GenMsgSendType" BO_ 54 0;
BA_ "GenMsgCycleTime" BO_ 53 50;
BA_ "GenMsgSendType" BO_ 53 0;
BA_ "GenMsgCycleTime" BO_ 52 50;
BA_ "GenMsgSendType" BO_ 52 0;
BA_ "GenMsgCycleTime" BO_ 51 50;
BA_ "GenMsgSendType" BO_ 51 0;
BA_ "GenMsgCycleTime" BO_ 50 50;
BA_ "GenMsgSendType" BO_ 50 0;
BA_ "GenMsgCycleTime" BO_ 49 50;
BA_ "GenMsgSendType" BO_ 49 0;
BA_ "GenMsgCycleTime" BO_ 48 50;
BA_ "GenMsgSendType" BO_ 48 0;
BA_ "GenMsgCycleTime" BO_ 47 50;
BA_ "GenMsgSendType" BO_ 47 0;
BA_ "GenMsgCycleTime" BO_ 46 50;
BA_ "GenMsgSendType" BO_ 46 0;
BA_ "GenMsgCycleTime" BO_ 45 50;
BA_ "GenMsgSendType" BO_ 45 0;
BA_ "GenMsgCycleTime" BO_ 44 50;
BA_ "GenMsgSendType" BO_ 44 0;
BA_ "GenMsgCycleTime" BO_ 43 50;
BA_ "GenMsgSendType" BO_ 43 0;
BA_ "GenMsgCycleTime" BO_ 42 50;
BA_ "GenMsgSendType" BO_ 42 0;
BA_ "GenMsgCycleTime" BO_ 41 50;
BA_ "GenMsgSendType" BO_ 41 0;
BA_ "GenMsgCycleTime" BO_ 40 50;
BA_ "GenMsgSendType" BO_ 40 0;
BA_ "GenMsgCycleTime" BO_ 39 50;
BA_ "GenMsgSendType" BO_ 39 0;
BA_ "GenMsgCycleTime" BO_ 38 50;
BA_ "GenMsgSendType" BO_ 38 0;
BA_ "GenMsgCycleTime" BO_ 37 50;
BA_ "GenMsgSendType" BO_ 37 0;
BA_ "GenMsgCycleTime" BO_ 36 50;
BA_ "GenMsgSendType" BO_ 36 0;
BA_ "GenMsgCycleTime" BO_ 35 50;
BA_ "GenMsgSendType" BO_ 35 0;
BA_ "GenMsgCycleTime" BO_ 34 50;
BA_ "GenMsgSendType" BO_ 34 0;
BA_ "GenMsgCycleTime" BO_ 33 50;
BA_ "GenMsgSendType" BO_ 33 0;
BA_ "GenMsgSendType" BO_ 119 0;
BA_ "GenMsgCycleTime" BO_ 119 50;
BA_ "GenMsgSendType" BO_ 118 0;
BA_ "GenMsgCycleTime" BO_ 118 50;
BA_ "GenMsgSendType" BO_ 117 0;
BA_ "GenMsgCycleTime" BO_ 117 50;
BA_ "GenMsgSendType" BO_ 116 0;
BA_ "GenMsgCycleTime" BO_ 116 50;
BA_ "GenMsgSendType" BO_ 115 0;
BA_ "GenMsgCycleTime" BO_ 115 50;
BA_ "GenMsgSendType" BO_ 114 0;
BA_ "GenMsgCycleTime" BO_ 114 50;
BA_ "GenMsgSendType" BO_ 113 0;
BA_ "GenMsgCycleTime" BO_ 113 50;
BA_ "GenMsgSendType" BO_ 112 0;
BA_ "GenMsgCycleTime" BO_ 112 50;
BA_ "GenMsgSendType" BO_ 111 0;
BA_ "GenMsgCycleTime" BO_ 111 50;
BA_ "GenMsgSendType" BO_ 110 0;
BA_ "GenMsgCycleTime" BO_ 110 50;
BA_ "GenMsgSendType" BO_ 109 0;
BA_ "GenMsgCycleTime" BO_ 109 50;
BA_ "GenMsgSendType" BO_ 108 0;
BA_ "GenMsgCycleTime" BO_ 108 50;
BA_ "GenMsgSendType" BO_ 107 0;
BA_ "GenMsgCycleTime" BO_ 107 50;
BA_ "GenMsgSendType" BO_ 106 0;
BA_ "GenMsgCycleTime" BO_ 106 50;
BA_ "GenMsgSendType" BO_ 105 0;
BA_ "GenMsgCycleTime" BO_ 105 50;
BA_ "GenMsgSendType" BO_ 104 0;
BA_ "GenMsgCycleTime" BO_ 104 50;
BA_ "GenMsgSendType" BO_ 103 0;
BA_ "GenMsgCycleTime" BO_ 103 50;
BA_ "GenMsgSendType" BO_ 102 0;
BA_ "GenMsgCycleTime" BO_ 102 50;
BA_ "GenMsgSendType" BO_ 101 0;
BA_ "GenMsgCycleTime" BO_ 101 50;
BA_ "GenMsgSendType" BO_ 100 0;
BA_ "GenMsgCycleTime" BO_ 100 50;
BA_ "GenMsgSendType" BO_ 99 0;
BA_ "GenMsgCycleTime" BO_ 99 50;
BA_ "GenMsgSendType" BO_ 98 0;
BA_ "GenMsgCycleTime" BO_ 98 50;
BA_ "GenMsgSendType" BO_ 97 0;
BA_ "GenMsgCycleTime" BO_ 97 50;
BA_ "GenMsgSendType" BO_ 96 0;
BA_ "GenMsgCycleTime" BO_ 96 50;
BA_ "GenMsgSendType" BO_ 95 0;
BA_ "GenMsgCycleTime" BO_ 95 50;
BA_ "GenMsgSendType" BO_ 94 0;
BA_ "GenMsgCycleTime" BO_ 94 50;
BA_ "GenMsgSendType" BO_ 93 0;
BA_ "GenMsgCycleTime" BO_ 93 50;
BA_ "GenMsgSendType" BO_ 92 0;
BA_ "GenMsgCycleTime" BO_ 92 50;
BA_ "GenMsgSendType" BO_ 91 0;
BA_ "GenMsgCycleTime" BO_ 91 50;
BA_ "GenMsgSendType" BO_ 90 0;
BA_ "GenMsgCycleTime" BO_ 90 50;
BA_ "GenMsgSendType" BO_ 89 0;
BA_ "GenMsgCycleTime" BO_ 89 50;
BA_ "GenMsgSendType" BO_ 88 0;
BA_ "GenMsgCycleTime" BO_ 88 50;
BA_ "GenMsgSendType" BO_ 87 0;
BA_ "GenMsgCycleTime" BO_ 87 50;
BA_ "GenMsgSendType" BO_ 86 0;
BA_ "GenMsgCycleTime" BO_ 86 50;
BA_ "GenMsgSendType" BO_ 85 0;
BA_ "GenMsgCycleTime" BO_ 85 50;
BA_ "GenMsgSendType" BO_ 84 0;
BA_ "GenMsgCycleTime" BO_ 84 50;
BA_ "GenMsgSendType" BO_ 83 0;
BA_ "GenMsgCycleTime" BO_ 83 50;
BA_ "GenMsgSendType" BO_ 82 0;
BA_ "GenMsgCycleTime" BO_ 82 50;
BA_ "GenMsgSendType" BO_ 81 0;
BA_ "GenMsgCycleTime" BO_ 81 50;
BA_ "GenMsgSendType" BO_ 32 0;
BA_ "GenMsgCycleTime" BO_ 32 50;
BA_ "GenMsgSendType" BO_ 80 0;
BA_ "GenMsgCycleTime" BO_ 80 50;
BA_ "GenMsgSendType" BO_ 128 0;
BA_ "GenMsgCycleTime" BO_ 128 50;
BA_ "GenMsgILSupport" BO_ 1074 0;
BA_ "NmAsrMessage" BO_ 1074 1;
BA_ "GenMsgSendType" BO_ 291 0;
BA_ "GenMsgCycleTime" BO_ 291 20;
BA_ "GenMsgSendType" BO_ 290 0;
BA_ "GenMsgCycleTime" BO_ 290 20;
BA_ "GenMsgILSupport" BO_ 2015 0;
BA_ "DiagRequest" BO_ 2015 1;
BA_ "DiagState" BO_ 2015 1;
BA_ "GenMsgILSupport" BO_ 804 0;
BA_ "GenMsgILSupport" BO_ 1010 0;
BA_ "GenMsgILSupport" BO_ 1704 0;
BA_ "GenMsgILSupport" BO_ 1696 0;
BA_ "GenMsgSendType" BO_ 357 0;
BA_ "GenMsgCycleTime" BO_ 357 20;
BA_ "GenMsgSendType" BO_ 304 0;
BA_ "GenMsgCycleTime" BO_ 304 20;
BA_ "GenMsgSendType" BO_ 305 0;
BA_ "GenMsgCycleTime" BO_ 305 20;
BA_ "GenMsgSendType" BO_ 224 0;
BA_ "GenMsgCycleTime" BO_ 224 10;
BA_ "GenMsgSendType" BO_ 293 0;
BA_ "GenMsgCycleTime" BO_ 293 20;
BA_ "GenMsgSendType" BO_ 133 0;
BA_ "GenMsgCycleTime" BO_ 133 10;
BA_ "GenMsgSendType" BO_ 275 0;
BA_ "GenMsgCycleTime" BO_ 275 20;
BA_ "GenMsgSendType" BO_ 608 0;
BA_ "GenMsgCycleTime" BO_ 608 100;
BA_ "GenMsgSendType" BO_ 1009 0;
BA_ "GenMsgCycleTime" BO_ 1009 1000;
BA_ "GenSigStartValue" SG_ 71 FRS_Obj_YVelRel_39Obj 1024;
BA_ "GenSigStartValue" SG_ 71 FRS_Obj_XVelRel_39Obj 1024;
BA_ "GenSigStartValue" SG_ 71 FRS_Obj_YPos_39Obj 4096;
BA_ "GenSigStartValue" SG_ 70 FRS_Obj_YVelRel_38Obj 1024;
BA_ "GenSigStartValue" SG_ 70 FRS_Obj_XVelRel_38Obj 1024;
BA_ "GenSigStartValue" SG_ 70 FRS_Obj_YPos_38Obj 4096;
BA_ "GenSigStartValue" SG_ 69 FRS_Obj_YVelRel_37Obj 1024;
BA_ "GenSigStartValue" SG_ 69 FRS_Obj_XVelRel_37Obj 1024;
BA_ "GenSigStartValue" SG_ 69 FRS_Obj_YPos_37Obj 4096;
BA_ "GenSigStartValue" SG_ 68 FRS_Obj_YVelRel_36Obj 1024;
BA_ "GenSigStartValue" SG_ 68 FRS_Obj_XVelRel_36Obj 1024;
BA_ "GenSigStartValue" SG_ 68 FRS_Obj_YPos_36Obj 4096;
BA_ "GenSigStartValue" SG_ 67 FRS_Obj_YVelRel_35Obj 1024;
BA_ "GenSigStartValue" SG_ 67 FRS_Obj_XVelRel_35Obj 1024;
BA_ "GenSigStartValue" SG_ 67 FRS_Obj_YPos_35Obj 4096;
BA_ "GenSigStartValue" SG_ 66 FRS_Obj_YVelRel_34Obj 1024;
BA_ "GenSigStartValue" SG_ 66 FRS_Obj_XVelRel_34Obj 1024;
BA_ "GenSigStartValue" SG_ 66 FRS_Obj_YPos_34Obj 4096;
BA_ "GenSigStartValue" SG_ 65 FRS_Obj_YVelRel_33Obj 1024;
BA_ "GenSigStartValue" SG_ 65 FRS_Obj_XVelRel_33Obj 1024;
BA_ "GenSigStartValue" SG_ 65 FRS_Obj_YPos_33Obj 4096;
BA_ "GenSigStartValue" SG_ 64 FRS_Obj_YVelRel_32Obj 1024;
BA_ "GenSigStartValue" SG_ 64 FRS_Obj_XVelRel_32Obj 1024;
BA_ "GenSigStartValue" SG_ 64 FRS_Obj_YPos_32Obj 4096;
BA_ "GenSigStartValue" SG_ 63 FRS_Obj_YVelRel_31Obj 1024;
BA_ "GenSigStartValue" SG_ 63 FRS_Obj_XVelRel_31Obj 1024;
BA_ "GenSigStartValue" SG_ 63 FRS_Obj_YPos_31Obj 4096;
BA_ "GenSigStartValue" SG_ 62 FRS_Obj_YVelRel_30Obj 1024;
BA_ "GenSigStartValue" SG_ 62 FRS_Obj_XVelRel_30Obj 1024;
BA_ "GenSigStartValue" SG_ 62 FRS_Obj_YPos_30Obj 4096;
BA_ "GenSigStartValue" SG_ 61 FRS_Obj_YVelRel_29Obj 1024;
BA_ "GenSigStartValue" SG_ 61 FRS_Obj_XVelRel_29Obj 1024;
BA_ "GenSigStartValue" SG_ 61 FRS_Obj_YPos_29Obj 4096;
BA_ "GenSigStartValue" SG_ 60 FRS_Obj_YVelRel_28Obj 1024;
BA_ "GenSigStartValue" SG_ 60 FRS_Obj_XVelRel_28Obj 1024;
BA_ "GenSigStartValue" SG_ 60 FRS_Obj_YPos_28Obj 4096;
BA_ "GenSigStartValue" SG_ 59 FRS_Obj_YVelRel_27Obj 1024;
BA_ "GenSigStartValue" SG_ 59 FRS_Obj_XVelRel_27Obj 1024;
BA_ "GenSigStartValue" SG_ 59 FRS_Obj_YPos_27Obj 4096;
BA_ "GenSigStartValue" SG_ 58 FRS_Obj_YVelRel_26Obj 1024;
BA_ "GenSigStartValue" SG_ 58 FRS_Obj_XVelRel_26Obj 1024;
BA_ "GenSigStartValue" SG_ 58 FRS_Obj_YPos_26Obj 4096;
BA_ "GenSigStartValue" SG_ 57 FRS_Obj_YVelRel_25Obj 1024;
BA_ "GenSigStartValue" SG_ 57 FRS_Obj_XVelRel_25Obj 1024;
BA_ "GenSigStartValue" SG_ 57 FRS_Obj_YPos_25Obj 4096;
BA_ "GenSigStartValue" SG_ 56 FRS_Obj_YVelRel_24Obj 1024;
BA_ "GenSigStartValue" SG_ 56 FRS_Obj_XVelRel_24Obj 1024;
BA_ "GenSigStartValue" SG_ 56 FRS_Obj_YPos_24Obj 4096;
BA_ "GenSigStartValue" SG_ 55 FRS_Obj_YVelRel_23Obj 1024;
BA_ "GenSigStartValue" SG_ 55 FRS_Obj_XVelRel_23Obj 1024;
BA_ "GenSigStartValue" SG_ 55 FRS_Obj_YPos_23Obj 4096;
BA_ "GenSigStartValue" SG_ 54 FRS_Obj_YVelRel_22Obj 1024;
BA_ "GenSigStartValue" SG_ 54 FRS_Obj_XVelRel_22Obj 1024;
BA_ "GenSigStartValue" SG_ 54 FRS_Obj_YPos_22Obj 4096;
BA_ "GenSigStartValue" SG_ 53 FRS_Obj_YVelRel_21Obj 1024;
BA_ "GenSigStartValue" SG_ 53 FRS_Obj_XVelRel_21Obj 1024;
BA_ "GenSigStartValue" SG_ 53 FRS_Obj_YPos_21Obj 4096;
BA_ "GenSigStartValue" SG_ 52 FRS_Obj_YVelRel_20Obj 1024;
BA_ "GenSigStartValue" SG_ 52 FRS_Obj_XVelRel_20Obj 1024;
BA_ "GenSigStartValue" SG_ 52 FRS_Obj_YPos_20Obj 4096;
BA_ "GenSigStartValue" SG_ 51 FRS_Obj_YVelRel_19Obj 1024;
BA_ "GenSigStartValue" SG_ 51 FRS_Obj_XVelRel_19Obj 1024;
BA_ "GenSigStartValue" SG_ 51 FRS_Obj_YPos_19Obj 4096;
BA_ "GenSigStartValue" SG_ 50 FRS_Obj_YVelRel_18Obj 1024;
BA_ "GenSigStartValue" SG_ 50 FRS_Obj_XVelRel_18Obj 1024;
BA_ "GenSigStartValue" SG_ 50 FRS_Obj_YPos_18Obj 4096;
BA_ "GenSigStartValue" SG_ 49 FRS_Obj_YVelRel_17Obj 1024;
BA_ "GenSigStartValue" SG_ 49 FRS_Obj_XVelRel_17Obj 1024;
BA_ "GenSigStartValue" SG_ 49 FRS_Obj_YPos_17Obj 4096;
BA_ "GenSigStartValue" SG_ 48 FRS_Obj_YVelRel_16Obj 1024;
BA_ "GenSigStartValue" SG_ 48 FRS_Obj_XVelRel_16Obj 1024;
BA_ "GenSigStartValue" SG_ 48 FRS_Obj_YPos_16Obj 4096;
BA_ "GenSigStartValue" SG_ 47 FRS_Obj_YVelRel_15Obj 1024;
BA_ "GenSigStartValue" SG_ 47 FRS_Obj_XVelRel_15Obj 1024;
BA_ "GenSigStartValue" SG_ 47 FRS_Obj_YPos_15Obj 4096;
BA_ "GenSigStartValue" SG_ 46 FRS_Obj_YVelRel_14Obj 1024;
BA_ "GenSigStartValue" SG_ 46 FRS_Obj_XVelRel_14Obj 1024;
BA_ "GenSigStartValue" SG_ 46 FRS_Obj_YPos_14Obj 4096;
BA_ "GenSigStartValue" SG_ 45 FRS_Obj_YVelRel_13Obj 1024;
BA_ "GenSigStartValue" SG_ 45 FRS_Obj_XVelRel_13Obj 1024;
BA_ "GenSigStartValue" SG_ 45 FRS_Obj_YPos_13Obj 4096;
BA_ "GenSigStartValue" SG_ 44 FRS_Obj_YVelRel_12Obj 1024;
BA_ "GenSigStartValue" SG_ 44 FRS_Obj_XVelRel_12Obj 1024;
BA_ "GenSigStartValue" SG_ 44 FRS_Obj_YPos_12Obj 4096;
BA_ "GenSigStartValue" SG_ 43 FRS_Obj_YVelRel_11Obj 1024;
BA_ "GenSigStartValue" SG_ 43 FRS_Obj_XVelRel_11Obj 1024;
BA_ "GenSigStartValue" SG_ 43 FRS_Obj_YPos_11Obj 4096;
BA_ "GenSigStartValue" SG_ 42 FRS_Obj_YVelRel_10Obj 1024;
BA_ "GenSigStartValue" SG_ 42 FRS_Obj_XVelRel_10Obj 1024;
BA_ "GenSigStartValue" SG_ 42 FRS_Obj_YPos_10Obj 4096;
BA_ "GenSigStartValue" SG_ 41 FRS_Obj_YVelRel_09Obj 1024;
BA_ "GenSigStartValue" SG_ 41 FRS_Obj_XVelRel_09Obj 1024;
BA_ "GenSigStartValue" SG_ 41 FRS_Obj_YPos_09Obj 4096;
BA_ "GenSigStartValue" SG_ 40 FRS_Obj_YVelRel_08Obj 1024;
BA_ "GenSigStartValue" SG_ 40 FRS_Obj_XVelRel_08Obj 1024;
BA_ "GenSigStartValue" SG_ 40 FRS_Obj_YPos_08Obj 4096;
BA_ "GenSigStartValue" SG_ 39 FRS_Obj_YVelRel_07Obj 1024;
BA_ "GenSigStartValue" SG_ 39 FRS_Obj_XVelRel_07Obj 1024;
BA_ "GenSigStartValue" SG_ 39 FRS_Obj_YPos_07Obj 4096;
BA_ "GenSigStartValue" SG_ 38 FRS_Obj_YVelRel_06Obj 1024;
BA_ "GenSigStartValue" SG_ 38 FRS_Obj_XVelRel_06Obj 1024;
BA_ "GenSigStartValue" SG_ 38 FRS_Obj_YPos_06Obj 4096;
BA_ "GenSigStartValue" SG_ 37 FRS_Obj_YVelRel_05Obj 1024;
BA_ "GenSigStartValue" SG_ 37 FRS_Obj_XVelRel_05Obj 1024;
BA_ "GenSigStartValue" SG_ 37 FRS_Obj_YPos_05Obj 4096;
BA_ "GenSigStartValue" SG_ 36 FRS_Obj_YVelRel_04Obj 1024;
BA_ "GenSigStartValue" SG_ 36 FRS_Obj_XVelRel_04Obj 1024;
BA_ "GenSigStartValue" SG_ 36 FRS_Obj_YPos_04Obj 4096;
BA_ "GenSigStartValue" SG_ 35 FRS_Obj_YVelRel_03Obj 1024;
BA_ "GenSigStartValue" SG_ 35 FRS_Obj_XVelRel_03Obj 1024;
BA_ "GenSigStartValue" SG_ 35 FRS_Obj_YPos_03Obj 4096;
BA_ "GenSigStartValue" SG_ 34 FRS_Obj_YVelRel_02Obj 1024;
BA_ "GenSigStartValue" SG_ 34 FRS_Obj_XVelRel_02Obj 1024;
BA_ "GenSigStartValue" SG_ 34 FRS_Obj_YPos_02Obj 4096;
BA_ "GenSigStartValue" SG_ 33 FRS_Obj_YVelRel_01Obj 1024;
BA_ "GenSigStartValue" SG_ 33 FRS_Obj_XVelRel_01Obj 1024;
BA_ "GenSigStartValue" SG_ 33 FRS_Obj_YPos_01Obj 4096;
BA_ "GenSigStartValue" SG_ 119 FRS_Obj_XAccRel_39Obj 64;
BA_ "GenSigStartValue" SG_ 119 FRS_Obj_ID_39Obj 255;
BA_ "GenSigStartValue" SG_ 118 FRS_Obj_XAccRel_38Obj 64;
BA_ "GenSigStartValue" SG_ 118 FRS_Obj_ID_38Obj 255;
BA_ "GenSigStartValue" SG_ 117 FRS_Obj_XAccRel_37Obj 64;
BA_ "GenSigStartValue" SG_ 117 FRS_Obj_ID_37Obj 255;
BA_ "GenSigStartValue" SG_ 116 FRS_Obj_XAccRel_36Obj 64;
BA_ "GenSigStartValue" SG_ 116 FRS_Obj_ID_36Obj 255;
BA_ "GenSigStartValue" SG_ 115 FRS_Obj_XAccRel_35Obj 64;
BA_ "GenSigStartValue" SG_ 115 FRS_Obj_ID_35Obj 255;
BA_ "GenSigStartValue" SG_ 114 FRS_Obj_XAccRel_34Obj 64;
BA_ "GenSigStartValue" SG_ 114 FRS_Obj_ID_34Obj 255;
BA_ "GenSigStartValue" SG_ 113 FRS_Obj_XAccRel_33Obj 64;
BA_ "GenSigStartValue" SG_ 113 FRS_Obj_ID_33Obj 255;
BA_ "GenSigStartValue" SG_ 112 FRS_Obj_XAccRel_32Obj 64;
BA_ "GenSigStartValue" SG_ 112 FRS_Obj_ID_32Obj 255;
BA_ "GenSigStartValue" SG_ 111 FRS_Obj_XAccRel_31Obj 64;
BA_ "GenSigStartValue" SG_ 111 FRS_Obj_ID_31Obj 255;
BA_ "GenSigStartValue" SG_ 110 FRS_Obj_XAccRel_30Obj 64;
BA_ "GenSigStartValue" SG_ 110 FRS_Obj_ID_30Obj 255;
BA_ "GenSigStartValue" SG_ 109 FRS_Obj_XAccRel_29Obj 64;
BA_ "GenSigStartValue" SG_ 109 FRS_Obj_ID_29Obj 255;
BA_ "GenSigStartValue" SG_ 108 FRS_Obj_XAccRel_28Obj 64;
BA_ "GenSigStartValue" SG_ 108 FRS_Obj_ID_28Obj 255;
BA_ "GenSigStartValue" SG_ 107 FRS_Obj_XAccRel_27Obj 64;
BA_ "GenSigStartValue" SG_ 107 FRS_Obj_ID_27Obj 255;
BA_ "GenSigStartValue" SG_ 106 FRS_Obj_XAccRel_26Obj 64;
BA_ "GenSigStartValue" SG_ 106 FRS_Obj_ID_26Obj 255;
BA_ "GenSigStartValue" SG_ 105 FRS_Obj_XAccRel_25Obj 64;
BA_ "GenSigStartValue" SG_ 105 FRS_Obj_ID_25Obj 255;
BA_ "GenSigStartValue" SG_ 104 FRS_Obj_XAccRel_24Obj 64;
BA_ "GenSigStartValue" SG_ 104 FRS_Obj_ID_24Obj 255;
BA_ "GenSigStartValue" SG_ 103 FRS_Obj_XAccRel_23Obj 64;
BA_ "GenSigStartValue" SG_ 103 FRS_Obj_ID_23Obj 255;
BA_ "GenSigStartValue" SG_ 102 FRS_Obj_XAccRel_22Obj 64;
BA_ "GenSigStartValue" SG_ 102 FRS_Obj_ID_22Obj 255;
BA_ "GenSigStartValue" SG_ 101 FRS_Obj_XAccRel_21Obj 64;
BA_ "GenSigStartValue" SG_ 101 FRS_Obj_ID_21Obj 255;
BA_ "GenSigStartValue" SG_ 100 FRS_Obj_XAccRel_20Obj 64;
BA_ "GenSigStartValue" SG_ 100 FRS_Obj_ID_20Obj 255;
BA_ "GenSigStartValue" SG_ 99 FRS_Obj_XAccRel_19Obj 64;
BA_ "GenSigStartValue" SG_ 99 FRS_Obj_ID_19Obj 255;
BA_ "GenSigStartValue" SG_ 98 FRS_Obj_XAccRel_18Obj 64;
BA_ "GenSigStartValue" SG_ 98 FRS_Obj_ID_18Obj 255;
BA_ "GenSigStartValue" SG_ 97 FRS_Obj_XAccRel_17Obj 64;
BA_ "GenSigStartValue" SG_ 97 FRS_Obj_ID_17Obj 255;
BA_ "GenSigStartValue" SG_ 96 FRS_Obj_XAccRel_16Obj 64;
BA_ "GenSigStartValue" SG_ 96 FRS_Obj_ID_16Obj 255;
BA_ "GenSigStartValue" SG_ 95 FRS_Obj_XAccRel_15Obj 64;
BA_ "GenSigStartValue" SG_ 95 FRS_Obj_ID_15Obj 255;
BA_ "GenSigStartValue" SG_ 94 FRS_Obj_XAccRel_14Obj 64;
BA_ "GenSigStartValue" SG_ 94 FRS_Obj_ID_14Obj 255;
BA_ "GenSigStartValue" SG_ 93 FRS_Obj_XAccRel_13Obj 64;
BA_ "GenSigStartValue" SG_ 93 FRS_Obj_ID_13Obj 255;
BA_ "GenSigStartValue" SG_ 92 FRS_Obj_XAccRel_12Obj 64;
BA_ "GenSigStartValue" SG_ 92 FRS_Obj_ID_12Obj 255;
BA_ "GenSigStartValue" SG_ 91 FRS_Obj_XAccRel_11Obj 64;
BA_ "GenSigStartValue" SG_ 91 FRS_Obj_ID_11Obj 255;
BA_ "GenSigStartValue" SG_ 90 FRS_Obj_XAccRel_10Obj 64;
BA_ "GenSigStartValue" SG_ 90 FRS_Obj_ID_10Obj 255;
BA_ "GenSigStartValue" SG_ 89 FRS_Obj_XAccRel_09Obj 64;
BA_ "GenSigStartValue" SG_ 89 FRS_Obj_ID_09Obj 255;
BA_ "GenSigStartValue" SG_ 88 FRS_Obj_XAccRel_08Obj 64;
BA_ "GenSigStartValue" SG_ 88 FRS_Obj_ID_08Obj 255;
BA_ "GenSigStartValue" SG_ 87 FRS_Obj_XAccRel_07Obj 64;
BA_ "GenSigStartValue" SG_ 87 FRS_Obj_ID_07Obj 255;
BA_ "GenSigStartValue" SG_ 86 FRS_Obj_XAccRel_06Obj 64;
BA_ "GenSigStartValue" SG_ 86 FRS_Obj_ID_06Obj 255;
BA_ "GenSigStartValue" SG_ 85 FRS_Obj_XAccRel_05Obj 64;
BA_ "GenSigStartValue" SG_ 85 FRS_Obj_ID_05Obj 255;
BA_ "GenSigStartValue" SG_ 84 FRS_Obj_XAccRel_04Obj 64;
BA_ "GenSigStartValue" SG_ 84 FRS_Obj_ID_04Obj 255;
BA_ "GenSigStartValue" SG_ 83 FRS_Obj_XAccRel_03Obj 64;
BA_ "GenSigStartValue" SG_ 83 FRS_Obj_ID_03Obj 255;
BA_ "GenSigStartValue" SG_ 82 FRS_Obj_XAccRel_02Obj 64;
BA_ "GenSigStartValue" SG_ 82 FRS_Obj_ID_02Obj 255;
BA_ "GenSigStartValue" SG_ 81 FRS_Obj_XAccRel_01Obj 64;
BA_ "GenSigStartValue" SG_ 81 FRS_Obj_ID_01Obj 255;
BA_ "GenSigStartValue" SG_ 32 FRS_Obj_YVelRel_00Obj 1024;
BA_ "GenSigStartValue" SG_ 32 FRS_Obj_XVelRel_00Obj 1024;
BA_ "GenSigStartValue" SG_ 32 FRS_Obj_YPos_00Obj 4096;
BA_ "GenSigStartValue" SG_ 80 FRS_Obj_XAccRel_00Obj 64;
BA_ "GenSigStartValue" SG_ 80 FRS_Obj_ID_00Obj 255;
BA_ "GenSigStartValue" SG_ 128 FRS_MeasEnabled 1;
BA_ "GenSigStartValue" SG_ 128 FRS_Host_Yaw 1024;
BA_ "GenSigStartValue" SG_ 128 FRS_HostSpeed 800;
BA_ "GenSigStartValue" SG_ 291 ESC_RRWheelSpeedInvalid 1;
BA_ "GenSigStartValue" SG_ 291 ESC_RRWheelDirection 3;
BA_ "GenSigStartValue" SG_ 291 ESC_RLWheelDirection 3;
BA_ "GenSigStartValue" SG_ 291 ESC_RLWheelSpeedInvalid 1;
BA_ "GenSigStartValue" SG_ 290 ESC_FRWheelDirection 3;
BA_ "GenSigStartValue" SG_ 290 ESC_FRWheelSpeedInvalid 1;
BA_ "GenSigStartValue" SG_ 290 ESC_FLWheelDirection 3;
BA_ "GenSigStartValue" SG_ 290 ESC_FLWheelSpeedInvalid 1;
BA_ "GenSigSendType" SG_ 2015 Func_DiagReq_RXNpdu 7;
BA_ "GenSigSendType" SG_ 804 AlvBlMsg_TXNpdu 7;
BA_ "GenSigSendType" SG_ 1010 AlvBlMsg_RXNpdu 7;
BA_ "GenSigSendType" SG_ 1704 DevelopMessage_TXNpdu 7;
BA_ "GenSigSendType" SG_ 1696 DevelopMessage_RXNpdu 7;
BA_ "GenSigStartValue" SG_ 357 VCU_CurrentGearPosition 15;
BA_ "GenSigInactiveValue" SG_ 357 VCU_CurrentGearPosition 15;
BA_ "GenSigStartValue" SG_ 304 YRS_LateralSensorState 3;
BA_ "GenSigStartValue" SG_ 304 YRS_YawRateSensorState 3;
BA_ "GenSigStartValue" SG_ 305 YRS_LongitSensorState 3;
BA_ "GenSigInactiveValue" SG_ 224 SAS_SteerWheelAngle 32767;
BA_ "GenSigInactiveValue" SG_ 293 ESC_VehicleSpeedInvalid 1;
BA_ "GenSigStartValue" SG_ 275 TCU_CurrentGearPosition 15;
BA_ "GenSigInactiveValue" SG_ 275 TCU_CurrentGearPosition 15;
VAL_ 71 FRS_Obj_Type_39Obj 3 "Pedestrian" 2 "2 wheeler" 1 "4 wheeler" 0 "Unknown" ;
VAL_ 71 FRS_Obj_MeasFlag_39Obj 1 "Obj extrapolated in this cycle" 0 "Object measured in this cycle" ;
VAL_ 70 FRS_Obj_Type_38Obj 3 "Pedestrian" 2 "2 wheeler" 1 "4 wheeler" 0 "Unknown" ;
VAL_ 70 FRS_Obj_MeasFlag_38Obj 1 "Obj extrapolated in this cycle" 0 "Object measured in this cycle" ;
VAL_ 69 FRS_Obj_Type_37Obj 3 "Pedestrian" 2 "2 wheeler" 1 "4 wheeler" 0 "Unknown" ;
VAL_ 69 FRS_Obj_MeasFlag_37Obj 1 "Obj extrapolated in this cycle" 0 "Object measured in this cycle" ;
VAL_ 68 FRS_Obj_Type_36Obj 3 "Pedestrian" 2 "2 wheeler" 1 "4 wheeler" 0 "Unknown" ;
VAL_ 68 FRS_Obj_MeasFlag_36Obj 1 "Obj extrapolated in this cycle" 0 "Object measured in this cycle" ;
VAL_ 67 FRS_Obj_Type_35Obj 3 "Pedestrian" 2 "2 wheeler" 1 "4 wheeler" 0 "Unknown" ;
VAL_ 67 FRS_Obj_MeasFlag_35Obj 1 "Obj extrapolated in this cycle" 0 "Object measured in this cycle" ;
VAL_ 66 FRS_Obj_Type_34Obj 3 "Pedestrian" 2 "2 wheeler" 1 "4 wheeler" 0 "Unknown" ;
VAL_ 66 FRS_Obj_MeasFlag_34Obj 1 "Obj extrapolated in this cycle" 0 "Object measured in this cycle" ;
VAL_ 65 FRS_Obj_Type_33Obj 3 "Pedestrian" 2 "2 wheeler" 1 "4 wheeler" 0 "Unknown" ;
VAL_ 65 FRS_Obj_MeasFlag_33Obj 1 "Obj extrapolated in this cycle" 0 "Object measured in this cycle" ;
VAL_ 64 FRS_Obj_Type_32Obj 3 "Pedestrian" 2 "2 wheeler" 1 "4 wheeler" 0 "Unknown" ;
VAL_ 64 FRS_Obj_MeasFlag_32Obj 1 "Obj extrapolated in this cycle" 0 "Object measured in this cycle" ;
VAL_ 63 FRS_Obj_Type_31Obj 3 "Pedestrian" 2 "2 wheeler" 1 "4 wheeler" 0 "Unknown" ;
VAL_ 63 FRS_Obj_MeasFlag_31Obj 1 "Obj extrapolated in this cycle" 0 "Object measured in this cycle" ;
VAL_ 62 FRS_Obj_Type_30Obj 3 "Pedestrian" 2 "2 wheeler" 1 "4 wheeler" 0 "Unknown" ;
VAL_ 62 FRS_Obj_MeasFlag_30Obj 1 "Obj extrapolated in this cycle" 0 "Object measured in this cycle" ;
VAL_ 61 FRS_Obj_Type_29Obj 3 "Pedestrian" 2 "2 wheeler" 1 "4 wheeler" 0 "Unknown" ;
VAL_ 61 FRS_Obj_MeasFlag_29Obj 1 "Obj extrapolated in this cycle" 0 "Object measured in this cycle" ;
VAL_ 60 FRS_Obj_Type_28Obj 3 "Pedestrian" 2 "2 wheeler" 1 "4 wheeler" 0 "Unknown" ;
VAL_ 60 FRS_Obj_MeasFlag_28Obj 1 "Obj extrapolated in this cycle" 0 "Object measured in this cycle" ;
VAL_ 59 FRS_Obj_Type_27Obj 3 "Pedestrian" 2 "2 wheeler" 1 "4 wheeler" 0 "Unknown" ;
VAL_ 59 FRS_Obj_MeasFlag_27Obj 1 "Obj extrapolated in this cycle" 0 "Object measured in this cycle" ;
VAL_ 58 FRS_Obj_Type_26Obj 3 "Pedestrian" 2 "2 wheeler" 1 "4 wheeler" 0 "Unknown" ;
VAL_ 58 FRS_Obj_MeasFlag_26Obj 1 "Obj extrapolated in this cycle" 0 "Object measured in this cycle" ;
VAL_ 57 FRS_Obj_Type_25Obj 3 "Pedestrian" 2 "2 wheeler" 1 "4 wheeler" 0 "Unknown" ;
VAL_ 57 FRS_Obj_MeasFlag_25Obj 1 "Obj extrapolated in this cycle" 0 "Object measured in this cycle" ;
VAL_ 56 FRS_Obj_Type_24Obj 3 "Pedestrian" 2 "2 wheeler" 1 "4 wheeler" 0 "Unknown" ;
VAL_ 56 FRS_Obj_MeasFlag_24Obj 1 "Obj extrapolated in this cycle" 0 "Object measured in this cycle" ;
VAL_ 55 FRS_Obj_Type_23Obj 3 "Pedestrian" 2 "2 wheeler" 1 "4 wheeler" 0 "Unknown" ;
VAL_ 55 FRS_Obj_MeasFlag_23Obj 1 "Obj extrapolated in this cycle" 0 "Object measured in this cycle" ;
VAL_ 54 FRS_Obj_Type_22Obj 3 "Pedestrian" 2 "2 wheeler" 1 "4 wheeler" 0 "Unknown" ;
VAL_ 54 FRS_Obj_MeasFlag_22Obj 1 "Obj extrapolated in this cycle" 0 "Object measured in this cycle" ;
VAL_ 53 FRS_Obj_Type_21Obj 3 "Pedestrian" 2 "2 wheeler" 1 "4 wheeler" 0 "Unknown" ;
VAL_ 53 FRS_Obj_MeasFlag_21Obj 1 "Obj extrapolated in this cycle" 0 "Object measured in this cycle" ;
VAL_ 52 FRS_Obj_Type_20Obj 3 "Pedestrian" 2 "2 wheeler" 1 "4 wheeler" 0 "Unknown" ;
VAL_ 52 FRS_Obj_MeasFlag_20Obj 1 "Obj extrapolated in this cycle" 0 "Object measured in this cycle" ;
VAL_ 51 FRS_Obj_Type_19Obj 3 "Pedestrian" 2 "2 wheeler" 1 "4 wheeler" 0 "Unknown" ;
VAL_ 51 FRS_Obj_MeasFlag_19Obj 1 "Obj extrapolated in this cycle" 0 "Object measured in this cycle" ;
VAL_ 50 FRS_Obj_Type_18Obj 3 "Pedestrian" 2 "2 wheeler" 1 "4 wheeler" 0 "Unknown" ;
VAL_ 50 FRS_Obj_MeasFlag_18Obj 1 "Obj extrapolated in this cycle" 0 "Object measured in this cycle" ;
VAL_ 49 FRS_Obj_Type_17Obj 3 "Pedestrian" 2 "2 wheeler" 1 "4 wheeler" 0 "Unknown" ;
VAL_ 49 FRS_Obj_MeasFlag_17Obj 1 "Obj extrapolated in this cycle" 0 "Object measured in this cycle" ;
VAL_ 48 FRS_Obj_Type_16Obj 3 "Pedestrian" 2 "2 wheeler" 1 "4 wheeler" 0 "Unknown" ;
VAL_ 48 FRS_Obj_MeasFlag_16Obj 1 "Obj extrapolated in this cycle" 0 "Object measured in this cycle" ;
VAL_ 47 FRS_Obj_Type_15Obj 3 "Pedestrian" 2 "2 wheeler" 1 "4 wheeler" 0 "Unknown" ;
VAL_ 47 FRS_Obj_MeasFlag_15Obj 1 "Obj extrapolated in this cycle" 0 "Object measured in this cycle" ;
VAL_ 46 FRS_Obj_Type_14Obj 3 "Pedestrian" 2 "2 wheeler" 1 "4 wheeler" 0 "Unknown" ;
VAL_ 46 FRS_Obj_MeasFlag_14Obj 1 "Obj extrapolated in this cycle" 0 "Object measured in this cycle" ;
VAL_ 45 FRS_Obj_Type_13Obj 3 "Pedestrian" 2 "2 wheeler" 1 "4 wheeler" 0 "Unknown" ;
VAL_ 45 FRS_Obj_MeasFlag_13Obj 1 "Obj extrapolated in this cycle" 0 "Object measured in this cycle" ;
VAL_ 44 FRS_Obj_Type_12Obj 3 "Pedestrian" 2 "2 wheeler" 1 "4 wheeler" 0 "Unknown" ;
VAL_ 44 FRS_Obj_MeasFlag_12Obj 1 "Obj extrapolated in this cycle" 0 "Object measured in this cycle" ;
VAL_ 43 FRS_Obj_Type_11Obj 3 "Pedestrian" 2 "2 wheeler" 1 "4 wheeler" 0 "Unknown" ;
VAL_ 43 FRS_Obj_MeasFlag_11Obj 1 "Obj extrapolated in this cycle" 0 "Object measured in this cycle" ;
VAL_ 42 FRS_Obj_Type_10Obj 3 "Pedestrian" 2 "2 wheeler" 1 "4 wheeler" 0 "Unknown" ;
VAL_ 42 FRS_Obj_MeasFlag_10Obj 1 "Obj extrapolated in this cycle" 0 "Object measured in this cycle" ;
VAL_ 41 FRS_Obj_Type_09Obj 3 "Pedestrian" 2 "2 wheeler" 1 "4 wheeler" 0 "Unknown" ;
VAL_ 41 FRS_Obj_MeasFlag_09Obj 1 "Obj extrapolated in this cycle" 0 "Object measured in this cycle" ;
VAL_ 40 FRS_Obj_Type_08Obj 3 "Pedestrian" 2 "2 wheeler" 1 "4 wheeler" 0 "Unknown" ;
VAL_ 40 FRS_Obj_MeasFlag_08Obj 1 "Obj extrapolated in this cycle" 0 "Object measured in this cycle" ;
VAL_ 39 FRS_Obj_Type_07Obj 3 "Pedestrian" 2 "2 wheeler" 1 "4 wheeler" 0 "Unknown" ;
VAL_ 39 FRS_Obj_MeasFlag_07Obj 1 "Obj extrapolated in this cycle" 0 "Object measured in this cycle" ;
VAL_ 38 FRS_Obj_Type_06Obj 3 "Pedestrian" 2 "2 wheeler" 1 "4 wheeler" 0 "Unknown" ;
VAL_ 38 FRS_Obj_MeasFlag_06Obj 1 "Obj extrapolated in this cycle" 0 "Object measured in this cycle" ;
VAL_ 37 FRS_Obj_Type_05Obj 3 "Pedestrian" 2 "2 wheeler" 1 "4 wheeler" 0 "Unknown" ;
VAL_ 37 FRS_Obj_MeasFlag_05Obj 1 "Obj extrapolated in this cycle" 0 "Object measured in this cycle" ;
VAL_ 36 FRS_Obj_Type_04Obj 3 "Pedestrian" 2 "2 wheeler" 1 "4 wheeler" 0 "Unknown" ;
VAL_ 36 FRS_Obj_MeasFlag_04Obj 1 "Obj extrapolated in this cycle" 0 "Object measured in this cycle" ;
VAL_ 35 FRS_Obj_Type_03Obj 3 "Pedestrian" 2 "2 wheeler" 1 "4 wheeler" 0 "Unknown" ;
VAL_ 35 FRS_Obj_MeasFlag_03Obj 1 "Obj extrapolated in this cycle" 0 "Object measured in this cycle" ;
VAL_ 34 FRS_Obj_Type_02Obj 3 "Pedestrian" 2 "2 wheeler" 1 "4 wheeler" 0 "Unknown" ;
VAL_ 34 FRS_Obj_MeasFlag_02Obj 1 "Obj extrapolated in this cycle" 0 "Object measured in this cycle" ;
VAL_ 33 FRS_Obj_Type_01Obj 3 "Pedestrian" 2 "2 wheeler" 1 "4 wheeler" 0 "Unknown" ;
VAL_ 33 FRS_Obj_MeasFlag_01Obj 1 "Obj extrapolated in this cycle" 0 "Object measured in this cycle" ;
VAL_ 119 FRS_ObjMotionPattern_39Obj 7 "Reserved" 6 "Reserved" 5 "Reserved" 4 "Crossing" 3 "Moving" 2 "Stopped" 1 "Stationary" 0 "Unknown" ;
VAL_ 119 FRS_Obj_ValidFlag_39Obj 1 "Object valid" 0 "Object invalid" ;
VAL_ 119 FRS_Obj_UpdateFlag_39Obj 1 "Object existed in previous" 0 "New object in the cycle" ;
VAL_ 119 FRS_Obj_ID_39Obj 255 "Invalid" ;
VAL_ 118 FRS_ObjMotionPattern_38Obj 7 "Reserved" 6 "Reserved" 5 "Reserved" 4 "Crossing" 3 "Moving" 2 "Stopped" 1 "Stationary" 0 "Unknown" ;
VAL_ 118 FRS_Obj_ValidFlag_38Obj 1 "Object valid" 0 "Object invalid" ;
VAL_ 118 FRS_Obj_UpdateFlag_38Obj 1 "Object existed in previous" 0 "New object in the cycle" ;
VAL_ 118 FRS_Obj_ID_38Obj 255 "Invalid" ;
VAL_ 117 FRS_ObjMotionPattern_37Obj 7 "Reserved" 6 "Reserved" 5 "Reserved" 4 "Crossing" 3 "Moving" 2 "Stopped" 1 "Stationary" 0 "Unknown" ;
VAL_ 117 FRS_Obj_ValidFlag_37Obj 1 "Object valid" 0 "Object invalid" ;
VAL_ 117 FRS_Obj_UpdateFlag_37Obj 1 "Object existed in previous" 0 "New object in the cycle" ;
VAL_ 117 FRS_Obj_ID_37Obj 255 "Invalid" ;
VAL_ 116 FRS_ObjMotionPattern_36Obj 7 "Reserved" 6 "Reserved" 5 "Reserved" 4 "Crossing" 3 "Moving" 2 "Stopped" 1 "Stationary" 0 "Unknown" ;
VAL_ 116 FRS_Obj_ValidFlag_36Obj 1 "Object valid" 0 "Object invalid" ;
VAL_ 116 FRS_Obj_UpdateFlag_36Obj 1 "Object existed in previous" 0 "New object in the cycle" ;
VAL_ 116 FRS_Obj_ID_36Obj 255 "Invalid" ;
VAL_ 115 FRS_ObjMotionPattern_35Obj 7 "Reserved" 6 "Reserved" 5 "Reserved" 4 "Crossing" 3 "Moving" 2 "Stopped" 1 "Stationary" 0 "Unknown" ;
VAL_ 115 FRS_Obj_ValidFlag_35Obj 1 "Object valid" 0 "Object invalid" ;
VAL_ 115 FRS_Obj_UpdateFlag_35Obj 1 "Object existed in previous" 0 "New object in the cycle" ;
VAL_ 115 FRS_Obj_ID_35Obj 255 "Invalid" ;
VAL_ 114 FRS_ObjMotionPattern_34Obj 7 "Reserved" 6 "Reserved" 5 "Reserved" 4 "Crossing" 3 "Moving" 2 "Stopped" 1 "Stationary" 0 "Unknown" ;
VAL_ 114 FRS_Obj_ValidFlag_34Obj 1 "Object valid" 0 "Object invalid" ;
VAL_ 114 FRS_Obj_UpdateFlag_34Obj 1 "Object existed in previous" 0 "New object in the cycle" ;
VAL_ 114 FRS_Obj_ID_34Obj 255 "Invalid" ;
VAL_ 113 FRS_ObjMotionPattern_33Obj 7 "Reserved" 6 "Reserved" 5 "Reserved" 4 "Crossing" 3 "Moving" 2 "Stopped" 1 "Stationary" 0 "Unknown" ;
VAL_ 113 FRS_Obj_ValidFlag_33Obj 1 "Object valid" 0 "Object invalid" ;
VAL_ 113 FRS_Obj_UpdateFlag_33Obj 1 "Object existed in previous" 0 "New object in the cycle" ;
VAL_ 113 FRS_Obj_ID_33Obj 255 "Invalid" ;
VAL_ 112 FRS_ObjMotionPattern_32Obj 7 "Reserved" 6 "Reserved" 5 "Reserved" 4 "Crossing" 3 "Moving" 2 "Stopped" 1 "Stationary" 0 "Unknown" ;
VAL_ 112 FRS_Obj_ValidFlag_32Obj 1 "Object valid" 0 "Object invalid" ;
VAL_ 112 FRS_Obj_UpdateFlag_32Obj 1 "Object existed in previous" 0 "New object in the cycle" ;
VAL_ 112 FRS_Obj_ID_32Obj 255 "Invalid" ;
VAL_ 111 FRS_ObjMotionPattern_31Obj 7 "Reserved" 6 "Reserved" 5 "Reserved" 4 "Crossing" 3 "Moving" 2 "Stopped" 1 "Stationary" 0 "Unknown" ;
VAL_ 111 FRS_Obj_ValidFlag_31Obj 1 "Object valid" 0 "Object invalid" ;
VAL_ 111 FRS_Obj_UpdateFlag_31Obj 1 "Object existed in previous" 0 "New object in the cycle" ;
VAL_ 111 FRS_Obj_ID_31Obj 255 "Invalid" ;
VAL_ 110 FRS_ObjMotionPattern_30Obj 7 "Reserved" 6 "Reserved" 5 "Reserved" 4 "Crossing" 3 "Moving" 2 "Stopped" 1 "Stationary" 0 "Unknown" ;
VAL_ 110 FRS_Obj_ValidFlag_30Obj 1 "Object valid" 0 "Object invalid" ;
VAL_ 110 FRS_Obj_UpdateFlag_30Obj 1 "Object existed in previous" 0 "New object in the cycle" ;
VAL_ 110 FRS_Obj_ID_30Obj 255 "Invalid" ;
VAL_ 109 FRS_ObjMotionPattern_29Obj 7 "Reserved" 6 "Reserved" 5 "Reserved" 4 "Crossing" 3 "Moving" 2 "Stopped" 1 "Stationary" 0 "Unknown" ;
VAL_ 109 FRS_Obj_ValidFlag_29Obj 1 "Object valid" 0 "Object invalid" ;
VAL_ 109 FRS_Obj_UpdateFlag_29Obj 1 "Object existed in previous" 0 "New object in the cycle" ;
VAL_ 109 FRS_Obj_ID_29Obj 255 "Invalid" ;
VAL_ 108 FRS_ObjMotionPattern_28Obj 7 "Reserved" 6 "Reserved" 5 "Reserved" 4 "Crossing" 3 "Moving" 2 "Stopped" 1 "Stationary" 0 "Unknown" ;
VAL_ 108 FRS_Obj_ValidFlag_28Obj 1 "Object valid" 0 "Object invalid" ;
VAL_ 108 FRS_Obj_UpdateFlag_28Obj 1 "Object existed in previous" 0 "New object in the cycle" ;
VAL_ 108 FRS_Obj_ID_28Obj 255 "Invalid" ;
VAL_ 107 FRS_ObjMotionPattern_27Obj 7 "Reserved" 6 "Reserved" 5 "Reserved" 4 "Crossing" 3 "Moving" 2 "Stopped" 1 "Stationary" 0 "Unknown" ;
VAL_ 107 FRS_Obj_ValidFlag_27Obj 1 "Object valid" 0 "Object invalid" ;
VAL_ 107 FRS_Obj_UpdateFlag_27Obj 1 "Object existed in previous" 0 "New object in the cycle" ;
VAL_ 107 FRS_Obj_ID_27Obj 255 "Invalid" ;
VAL_ 106 FRS_ObjMotionPattern_26Obj 7 "Reserved" 6 "Reserved" 5 "Reserved" 4 "Crossing" 3 "Moving" 2 "Stopped" 1 "Stationary" 0 "Unknown" ;
VAL_ 106 FRS_Obj_ValidFlag_26Obj 1 "Object valid" 0 "Object invalid" ;
VAL_ 106 FRS_Obj_UpdateFlag_26Obj 1 "Object existed in previous" 0 "New object in the cycle" ;
VAL_ 106 FRS_Obj_ID_26Obj 255 "Invalid" ;
VAL_ 105 FRS_ObjMotionPattern_25Obj 7 "Reserved" 6 "Reserved" 5 "Reserved" 4 "Crossing" 3 "Moving" 2 "Stopped" 1 "Stationary" 0 "Unknown" ;
VAL_ 105 FRS_Obj_ValidFlag_25Obj 1 "Object valid" 0 "Object invalid" ;
VAL_ 105 FRS_Obj_UpdateFlag_25Obj 1 "Object existed in previous" 0 "New object in the cycle" ;
VAL_ 105 FRS_Obj_ID_25Obj 255 "Invalid" ;
VAL_ 104 FRS_ObjMotionPattern_24Obj 7 "Reserved" 6 "Reserved" 5 "Reserved" 4 "Crossing" 3 "Moving" 2 "Stopped" 1 "Stationary" 0 "Unknown" ;
VAL_ 104 FRS_Obj_ValidFlag_24Obj 1 "Object valid" 0 "Object invalid" ;
VAL_ 104 FRS_Obj_UpdateFlag_24Obj 1 "Object existed in previous" 0 "New object in the cycle" ;
VAL_ 104 FRS_Obj_ID_24Obj 255 "Invalid" ;
VAL_ 103 FRS_ObjMotionPattern_23Obj 7 "Reserved" 6 "Reserved" 5 "Reserved" 4 "Crossing" 3 "Moving" 2 "Stopped" 1 "Stationary" 0 "Unknown" ;
VAL_ 103 FRS_Obj_ValidFlag_23Obj 1 "Object valid" 0 "Object invalid" ;
VAL_ 103 FRS_Obj_UpdateFlag_23Obj 1 "Object existed in previous" 0 "New object in the cycle" ;
VAL_ 103 FRS_Obj_ID_23Obj 255 "Invalid" ;
VAL_ 102 FRS_ObjMotionPattern_22Obj 7 "Reserved" 6 "Reserved" 5 "Reserved" 4 "Crossing" 3 "Moving" 2 "Stopped" 1 "Stationary" 0 "Unknown" ;
VAL_ 102 FRS_Obj_ValidFlag_22Obj 1 "Object valid" 0 "Object invalid" ;
VAL_ 102 FRS_Obj_UpdateFlag_22Obj 1 "Object existed in previous" 0 "New object in the cycle" ;
VAL_ 102 FRS_Obj_ID_22Obj 255 "Invalid" ;
VAL_ 101 FRS_ObjMotionPattern_21Obj 7 "Reserved" 6 "Reserved" 5 "Reserved" 4 "Crossing" 3 "Moving" 2 "Stopped" 1 "Stationary" 0 "Unknown" ;
VAL_ 101 FRS_Obj_ValidFlag_21Obj 1 "Object valid" 0 "Object invalid" ;
VAL_ 101 FRS_Obj_UpdateFlag_21Obj 1 "Object existed in previous" 0 "New object in the cycle" ;
VAL_ 101 FRS_Obj_ID_21Obj 255 "Invalid" ;
VAL_ 100 FRS_ObjMotionPattern_20Obj 7 "Reserved" 6 "Reserved" 5 "Reserved" 4 "Crossing" 3 "Moving" 2 "Stopped" 1 "Stationary" 0 "Unknown" ;
VAL_ 100 FRS_Obj_ValidFlag_20Obj 1 "Object valid" 0 "Object invalid" ;
VAL_ 100 FRS_Obj_UpdateFlag_20Obj 1 "Object existed in previous" 0 "New object in the cycle" ;
VAL_ 100 FRS_Obj_ID_20Obj 255 "Invalid" ;
VAL_ 99 FRS_ObjMotionPattern_19Obj 7 "Reserved" 6 "Reserved" 5 "Reserved" 4 "Crossing" 3 "Moving" 2 "Stopped" 1 "Stationary" 0 "Unknown" ;
VAL_ 99 FRS_Obj_ValidFlag_19Obj 1 "Object valid" 0 "Object invalid" ;
VAL_ 99 FRS_Obj_UpdateFlag_19Obj 1 "Object existed in previous" 0 "New object in the cycle" ;
VAL_ 99 FRS_Obj_ID_19Obj 255 "Invalid" ;
VAL_ 98 FRS_ObjMotionPattern_18Obj 7 "Reserved" 6 "Reserved" 5 "Reserved" 4 "Crossing" 3 "Moving" 2 "Stopped" 1 "Stationary" 0 "Unknown" ;
VAL_ 98 FRS_Obj_ValidFlag_18Obj 1 "Object valid" 0 "Object invalid" ;
VAL_ 98 FRS_Obj_UpdateFlag_18Obj 1 "Object existed in previous" 0 "New object in the cycle" ;
VAL_ 98 FRS_Obj_ID_18Obj 255 "Invalid" ;
VAL_ 97 FRS_ObjMotionPattern_17Obj 7 "Reserved" 6 "Reserved" 5 "Reserved" 4 "Crossing" 3 "Moving" 2 "Stopped" 1 "Stationary" 0 "Unknown" ;
VAL_ 97 FRS_Obj_ValidFlag_17Obj 1 "Object valid" 0 "Object invalid" ;
VAL_ 97 FRS_Obj_UpdateFlag_17Obj 1 "Object existed in previous" 0 "New object in the cycle" ;
VAL_ 97 FRS_Obj_ID_17Obj 255 "Invalid" ;
VAL_ 96 FRS_ObjMotionPattern_16Obj 7 "Reserved" 6 "Reserved" 5 "Reserved" 4 "Crossing" 3 "Moving" 2 "Stopped" 1 "Stationary" 0 "Unknown" ;
VAL_ 96 FRS_Obj_ValidFlag_16Obj 1 "Object valid" 0 "Object invalid" ;
VAL_ 96 FRS_Obj_UpdateFlag_16Obj 1 "Object existed in previous" 0 "New object in the cycle" ;
VAL_ 96 FRS_Obj_ID_16Obj 255 "Invalid" ;
VAL_ 95 FRS_ObjMotionPattern_15Obj 7 "Reserved" 6 "Reserved" 5 "Reserved" 4 "Crossing" 3 "Moving" 2 "Stopped" 1 "Stationary" 0 "Unknown" ;
VAL_ 95 FRS_Obj_ValidFlag_15Obj 1 "Object valid" 0 "Object invalid" ;
VAL_ 95 FRS_Obj_UpdateFlag_15Obj 1 "Object existed in previous" 0 "New object in the cycle" ;
VAL_ 95 FRS_Obj_ID_15Obj 255 "Invalid" ;
VAL_ 94 FRS_ObjMotionPattern_14Obj 7 "Reserved" 6 "Reserved" 5 "Reserved" 4 "Crossing" 3 "Moving" 2 "Stopped" 1 "Stationary" 0 "Unknown" ;
VAL_ 94 FRS_Obj_ValidFlag_14Obj 1 "Object valid" 0 "Object invalid" ;
VAL_ 94 FRS_Obj_UpdateFlag_14Obj 1 "Object existed in previous" 0 "New object in the cycle" ;
VAL_ 94 FRS_Obj_ID_14Obj 255 "Invalid" ;
VAL_ 93 FRS_ObjMotionPattern_13Obj 7 "Reserved" 6 "Reserved" 5 "Reserved" 4 "Crossing" 3 "Moving" 2 "Stopped" 1 "Stationary" 0 "Unknown" ;
VAL_ 93 FRS_Obj_ValidFlag_13Obj 1 "Object valid" 0 "Object invalid" ;
VAL_ 93 FRS_Obj_UpdateFlag_13Obj 1 "Object existed in previous" 0 "New object in the cycle" ;
VAL_ 93 FRS_Obj_ID_13Obj 255 "Invalid" ;
VAL_ 92 FRS_ObjMotionPattern_12Obj 7 "Reserved" 6 "Reserved" 5 "Reserved" 4 "Crossing" 3 "Moving" 2 "Stopped" 1 "Stationary" 0 "Unknown" ;
VAL_ 92 FRS_Obj_ValidFlag_12Obj 1 "Object valid" 0 "Object invalid" ;
VAL_ 92 FRS_Obj_UpdateFlag_12Obj 1 "Object existed in previous" 0 "New object in the cycle" ;
VAL_ 92 FRS_Obj_ID_12Obj 255 "Invalid" ;
VAL_ 91 FRS_ObjMotionPattern_11Obj 7 "Reserved" 6 "Reserved" 5 "Reserved" 4 "Crossing" 3 "Moving" 2 "Stopped" 1 "Stationary" 0 "Unknown" ;
VAL_ 91 FRS_Obj_ValidFlag_11Obj 1 "Object valid" 0 "Object invalid" ;
VAL_ 91 FRS_Obj_UpdateFlag_11Obj 1 "Object existed in previous" 0 "New object in the cycle" ;
VAL_ 91 FRS_Obj_ID_11Obj 255 "Invalid" ;
VAL_ 90 FRS_ObjMotionPattern_10Obj 7 "Reserved" 6 "Reserved" 5 "Reserved" 4 "Crossing" 3 "Moving" 2 "Stopped" 1 "Stationary" 0 "Unknown" ;
VAL_ 90 FRS_Obj_ValidFlag_10Obj 1 "Object valid" 0 "Object invalid" ;
VAL_ 90 FRS_Obj_UpdateFlag_10Obj 1 "Object existed in previous" 0 "New object in the cycle" ;
VAL_ 90 FRS_Obj_ID_10Obj 255 "Invalid" ;
VAL_ 89 FRS_ObjMotionPattern_09Obj 7 "Reserved" 6 "Reserved" 5 "Reserved" 4 "Crossing" 3 "Moving" 2 "Stopped" 1 "Stationary" 0 "Unknown" ;
VAL_ 89 FRS_Obj_ValidFlag_09Obj 1 "Object valid" 0 "Object invalid" ;
VAL_ 89 FRS_Obj_UpdateFlag_09Obj 1 "Object existed in previous" 0 "New object in the cycle" ;
VAL_ 89 FRS_Obj_ID_09Obj 255 "Invalid" ;
VAL_ 88 FRS_ObjMotionPattern_08Obj 7 "Reserved" 6 "Reserved" 5 "Reserved" 4 "Crossing" 3 "Moving" 2 "Stopped" 1 "Stationary" 0 "Unknown" ;
VAL_ 88 FRS_Obj_ValidFlag_08Obj 1 "Object valid" 0 "Object invalid" ;
VAL_ 88 FRS_Obj_UpdateFlag_08Obj 1 "Object existed in previous" 0 "New object in the cycle" ;
VAL_ 88 FRS_Obj_ID_08Obj 255 "Invalid" ;
VAL_ 87 FRS_ObjMotionPattern_07Obj 7 "Reserved" 6 "Reserved" 5 "Reserved" 4 "Crossing" 3 "Moving" 2 "Stopped" 1 "Stationary" 0 "Unknown" ;
VAL_ 87 FRS_Obj_ValidFlag_07Obj 1 "Object valid" 0 "Object invalid" ;
VAL_ 87 FRS_Obj_UpdateFlag_07Obj 1 "Object existed in previous" 0 "New object in the cycle" ;
VAL_ 87 FRS_Obj_ID_07Obj 255 "Invalid" ;
VAL_ 86 FRS_ObjMotionPattern_06Obj 7 "Reserved" 6 "Reserved" 5 "Reserved" 4 "Crossing" 3 "Moving" 2 "Stopped" 1 "Stationary" 0 "Unknown" ;
VAL_ 86 FRS_Obj_ValidFlag_06Obj 1 "Object valid" 0 "Object invalid" ;
VAL_ 86 FRS_Obj_UpdateFlag_06Obj 1 "Object existed in previous" 0 "New object in the cycle" ;
VAL_ 86 FRS_Obj_ID_06Obj 255 "Invalid" ;
VAL_ 85 FRS_ObjMotionPattern_05Obj 7 "Reserved" 6 "Reserved" 5 "Reserved" 4 "Crossing" 3 "Moving" 2 "Stopped" 1 "Stationary" 0 "Unknown" ;
VAL_ 85 FRS_Obj_ValidFlag_05Obj 1 "Object valid" 0 "Object invalid" ;
VAL_ 85 FRS_Obj_UpdateFlag_05Obj 1 "Object existed in previous" 0 "New object in the cycle" ;
VAL_ 85 FRS_Obj_ID_05Obj 255 "Invalid" ;
VAL_ 84 FRS_ObjMotionPattern_04Obj 7 "Reserved" 6 "Reserved" 5 "Reserved" 4 "Crossing" 3 "Moving" 2 "Stopped" 1 "Stationary" 0 "Unknown" ;
VAL_ 84 FRS_Obj_ValidFlag_04Obj 1 "Object valid" 0 "Object invalid" ;
VAL_ 84 FRS_Obj_UpdateFlag_04Obj 1 "Object existed in previous" 0 "New object in the cycle" ;
VAL_ 84 FRS_Obj_ID_04Obj 255 "Invalid" ;
VAL_ 83 FRS_ObjMotionPattern_03Obj 7 "Reserved" 6 "Reserved" 5 "Reserved" 4 "Crossing" 3 "Moving" 2 "Stopped" 1 "Stationary" 0 "Unknown" ;
VAL_ 83 FRS_Obj_ValidFlag_03Obj 1 "Object valid" 0 "Object invalid" ;
VAL_ 83 FRS_Obj_UpdateFlag_03Obj 1 "Object existed in previous" 0 "New object in the cycle" ;
VAL_ 83 FRS_Obj_ID_03Obj 255 "Invalid" ;
VAL_ 82 FRS_ObjMotionPattern_02Obj 7 "Reserved" 6 "Reserved" 5 "Reserved" 4 "Crossing" 3 "Moving" 2 "Stopped" 1 "Stationary" 0 "Unknown" ;
VAL_ 82 FRS_Obj_ValidFlag_02Obj 1 "Object valid" 0 "Object invalid" ;
VAL_ 82 FRS_Obj_UpdateFlag_02Obj 1 "Object existed in previous" 0 "New object in the cycle" ;
VAL_ 82 FRS_Obj_ID_02Obj 255 "Invalid" ;
VAL_ 81 FRS_ObjMotionPattern_01Obj 7 "Reserved" 6 "Reserved" 5 "Reserved" 4 "Crossing" 3 "Moving" 2 "Stopped" 1 "Stationary" 0 "Unknown" ;
VAL_ 81 FRS_Obj_ValidFlag_01Obj 1 "Object valid" 0 "Object invalid" ;
VAL_ 81 FRS_Obj_UpdateFlag_01Obj 1 "Object existed in previous" 0 "New object in the cycle" ;
VAL_ 81 FRS_Obj_ID_01Obj 255 "Invalid" ;
VAL_ 32 FRS_Obj_Type_00Obj 3 "Pedestrian" 2 "2 wheeler" 1 "4 wheeler" 0 "Unknown" ;
VAL_ 32 FRS_Obj_MeasFlag_00Obj 1 "Obj extrapolated in this cycle" 0 "Object measured in this cycle" ;
VAL_ 80 FRS_ObjMotionPattern_00Obj 7 "Reserved" 6 "Reserved" 5 "Reserved" 4 "Crossing" 3 "Moving" 2 "Stopped" 1 "Stationary" 0 "Unknown" ;
VAL_ 80 FRS_Obj_ValidFlag_00Obj 1 "Object valid" 0 "Object invalid" ;
VAL_ 80 FRS_Obj_UpdateFlag_00Obj 1 "Object existed in previous" 0 "New object in the cycle" ;
VAL_ 80 FRS_Obj_ID_00Obj 255 "Invalid" ;
VAL_ 128 FRS_Status_HWErr 1 "Radar is failed" 0 "Radar NOT failed" ;
VAL_ 128 FRS_Status_BlkProg 1 "FRS is blocked" 0 "FRS is NOT blocked" ;
VAL_ 128 FRS_Status_MisAlign 4 "Uncalibratable" 3 "Calibration in progress" 2 "Sensor mis-alignment detected" 1 "Calibrated" 0 "Unknown" ;
VAL_ 128 FRS_Fail 1 "FRS radar is working" 0 "FRS radar is NOT working" ;
VAL_ 1074 FRS_AWB 1 "Active Wakeup" 0 "Passive wakeup" ;
VAL_ 1074 FRS_RMR 1 "Repeat Msg State requested" 0 "Repeat Msg State not requested" ;
VAL_ 1074 FRS_NMSts 1 "Normal Operation State" 0 "Repeat Message State" ;
VAL_ 1074 FRS_Wakeup_reasons 6 "Description for the value '0x6'" 5 "Description for the value '0x5'" 4 "Description for the value '0x4'" 3 "Description for the value '0x3'" 2 "NM PDU Received" 1 "Description for the value '0x1'" 0 "Default" ;
VAL_ 291 ESC_RRWheelSpeedKPH 8191 "Invalid" ;
VAL_ 291 ESC_RRWheelSpeedInvalid 1 "Invalid" 0 "Valid" ;
VAL_ 291 ESC_RRWheelDirection 3 "Invalid" 2 "Backward" 1 "Forward" 0 "Standstill" ;
VAL_ 291 ESC_RLWheelSpeedKPH 8191 "Invalid" ;
VAL_ 291 ESC_RLWheelDirection 3 "Invalid" 2 "Backward" 1 "Forward" 0 "Standstill" ;
VAL_ 291 ESC_RLWheelSpeedInvalid 1 "Invalid" 0 "Valid" ;
VAL_ 290 ESC_FRWheelDirection 3 "Invalid" 2 "Backward" 1 "Forward" 0 "Standstill" ;
VAL_ 290 ESC_FRWheelSpeedInvalid 1 "Invalid" 0 "Valid" ;
VAL_ 290 ESC_FRWheelSpeedKPH 8191 "Invalid" ;
VAL_ 290 ESC_FLWheelDirection 3 "Invalid" 2 "Backward" 1 "Forward" 0 "Standstill" ;
VAL_ 290 ESC_FLWheelSpeedInvalid 1 "Invalid" 0 "Valid" ;
VAL_ 290 ESC_FLWheelSpeedKPH 8191 "Invalid" ;
VAL_ 357 VCU_CurrentGearPosition 15 "Invalid" 12 "Current gear D" 11 "Current gear Reverse" 10 "Park" 0 "Current gear N" ;
VAL_ 304 YRS_LateralSensorState 3 "Initializing" 2 "Reserved" 1 "Invalid" 0 "Valid" ;
VAL_ 304 YRS_LateralAcce 65535 "Invalid" ;
VAL_ 304 YRS_YawRate 65535 "Invalid" ;
VAL_ 304 YRS_YawRateSensorState 3 "Initializing" 2 "Reserved" 1 "Invalid" 0 "Valid" ;
VAL_ 305 YRS_LongitSensorState 3 "Initializing" 2 "Reserved" 1 "Invalid" 0 "Valid" ;
VAL_ 305 YRS_LongitAcce 65535 "Invalid" ;
VAL_ 224 SAS_FailureSts 1 "Valid" 0 "Invalid" ;
VAL_ 224 SAS_SteerWheelAngle 32767 "Invalid" ;
VAL_ 293 ESC_VehicleSpeedInvalid 1 "Invalid" 0 "Valid" ;
VAL_ 293 ESC_VehicleSpeed 8190 "Abnormal" 8191 "Invalid value" ;
VAL_ 133 EMS_EngStatus 7 "Invalid" 6 "Abnormal" 5 "Reserved" 4 "Reserved" 3 "Running" 2 "Stopping" 1 "Cranking" 0 "Engine Stop" ;
VAL_ 275 TCU_CurrentGearPosition 15 "Invalid" 11 "Current gear Reverse" 10 "Park" 7 "Current gear 7(6AT Reserved)" 6 "Current gear 6" 5 "Current gear 5" 4 "Current gear 4" 3 "Current gear 3" 2 "Current gear 2" 1 "Current gear 1" 0 "Current gear N" ;
VAL_ 608 IPK_AEB_FCWSenlevel 3 "High" 2 "Medium" 1 "low" 0 "No Action" ;
VAL_ 608 IPK_ALOD_ControlTypeReq 3 "ICC" 2 "ACC" 1 "CC" 0 "No Action" ;
VAL_ 608 IPK_AEB_AEBStateReq 3 "Reserved" 2 "ON Request" 1 "OFF Request" 0 "No Action" ;
VAL_ 608 IPK_AEB_FCWStateReq 3 "Reserved" 2 "ON Request" 1 "OFF Request" 0 "No Action" ;
VAL_ 1009 IPK_IPKTotalOdometer 16777214 "Abnormal" 16777215 "Invalid" ;
SIG_GROUP_ 71 Obj39Part02_Grp 1 : FRS_Msg_CheckSum_39Obj02 FRS_Msg_AliveCounter_39Obj02 FRS_Obj_Type_39Obj FRS_Obj_MeasFlag_39Obj FRS_Obj_YVelRel_39Obj FRS_Obj_XVelRel_39Obj FRS_Obj_YPos_39Obj FRS_Obj_XPos_39Obj;
SIG_GROUP_ 70 Obj38Part02_Grp 1 : FRS_Msg_CheckSum_38Obj02 FRS_Msg_AliveCounter_38Obj02 FRS_Obj_Type_38Obj FRS_Obj_MeasFlag_38Obj FRS_Obj_YVelRel_38Obj FRS_Obj_XVelRel_38Obj FRS_Obj_YPos_38Obj FRS_Obj_XPos_38Obj;
SIG_GROUP_ 69 Obj37Part02_Grp 1 : FRS_Msg_CheckSum_37Obj02 FRS_Msg_AliveCounter_37Obj02 FRS_Obj_Type_37Obj FRS_Obj_MeasFlag_37Obj FRS_Obj_YVelRel_37Obj FRS_Obj_XVelRel_37Obj FRS_Obj_YPos_37Obj FRS_Obj_XPos_37Obj;
SIG_GROUP_ 68 Obj36Part02_Grp 1 : FRS_Msg_CheckSum_36Obj02 FRS_Msg_AliveCounter_36Obj02 FRS_Obj_Type_36Obj FRS_Obj_MeasFlag_36Obj FRS_Obj_YVelRel_36Obj FRS_Obj_XVelRel_36Obj FRS_Obj_YPos_36Obj FRS_Obj_XPos_36Obj;
SIG_GROUP_ 67 Obj35Part02_Grp 1 : FRS_Msg_CheckSum_35Obj02 FRS_Msg_AliveCounter_35Obj02 FRS_Obj_Type_35Obj FRS_Obj_MeasFlag_35Obj FRS_Obj_YVelRel_35Obj FRS_Obj_XVelRel_35Obj FRS_Obj_YPos_35Obj FRS_Obj_XPos_35Obj;
SIG_GROUP_ 66 Obj34Part02_Grp 1 : FRS_Msg_CheckSum_34Obj02 FRS_Msg_AliveCounter_34Obj02 FRS_Obj_Type_34Obj FRS_Obj_MeasFlag_34Obj FRS_Obj_YVelRel_34Obj FRS_Obj_XVelRel_34Obj FRS_Obj_YPos_34Obj FRS_Obj_XPos_34Obj;
SIG_GROUP_ 65 Obj33Part02_Grp 1 : FRS_Msg_CheckSum_33Obj02 FRS_Msg_AliveCounter_33Obj02 FRS_Obj_Type_33Obj FRS_Obj_MeasFlag_33Obj FRS_Obj_YVelRel_33Obj FRS_Obj_XVelRel_33Obj FRS_Obj_YPos_33Obj FRS_Obj_XPos_33Obj;
SIG_GROUP_ 64 Obj32Part02_Grp 1 : FRS_Msg_CheckSum_32Obj02 FRS_Msg_AliveCounter_32Obj02 FRS_Obj_Type_32Obj FRS_Obj_MeasFlag_32Obj FRS_Obj_YVelRel_32Obj FRS_Obj_XVelRel_32Obj FRS_Obj_YPos_32Obj FRS_Obj_XPos_32Obj;
SIG_GROUP_ 63 Obj31Part02_Grp 1 : FRS_Msg_CheckSum_31Obj02 FRS_Msg_AliveCounter_31Obj02 FRS_Obj_Type_31Obj FRS_Obj_MeasFlag_31Obj FRS_Obj_YVelRel_31Obj FRS_Obj_XVelRel_31Obj FRS_Obj_YPos_31Obj FRS_Obj_XPos_31Obj;
SIG_GROUP_ 62 Obj30Part02_Grp 1 : FRS_Msg_CheckSum_30Obj02 FRS_Msg_AliveCounter_30Obj02 FRS_Obj_Type_30Obj FRS_Obj_MeasFlag_30Obj FRS_Obj_YVelRel_30Obj FRS_Obj_XVelRel_30Obj FRS_Obj_YPos_30Obj FRS_Obj_XPos_30Obj;
SIG_GROUP_ 61 Obj29Part02_Grp 1 : FRS_Msg_CheckSum_29Obj02 FRS_Msg_AliveCounter_29Obj02 FRS_Obj_Type_29Obj FRS_Obj_MeasFlag_29Obj FRS_Obj_YVelRel_29Obj FRS_Obj_XVelRel_29Obj FRS_Obj_YPos_29Obj FRS_Obj_XPos_29Obj;
SIG_GROUP_ 60 Obj28Part02_Grp 1 : FRS_Msg_CheckSum_28Obj02 FRS_Msg_AliveCounter_28Obj02 FRS_Obj_Type_28Obj FRS_Obj_MeasFlag_28Obj FRS_Obj_YVelRel_28Obj FRS_Obj_XVelRel_28Obj FRS_Obj_YPos_28Obj FRS_Obj_XPos_28Obj;
SIG_GROUP_ 59 Obj27Part02_Grp 1 : FRS_Msg_CheckSum_27Obj02 FRS_Msg_AliveCounter_27Obj02 FRS_Obj_Type_27Obj FRS_Obj_MeasFlag_27Obj FRS_Obj_YVelRel_27Obj FRS_Obj_XVelRel_27Obj FRS_Obj_YPos_27Obj FRS_Obj_XPos_27Obj;
SIG_GROUP_ 58 Obj26Part02_Grp 1 : FRS_Msg_CheckSum_26Obj02 FRS_Msg_AliveCounter_26Obj02 FRS_Obj_Type_26Obj FRS_Obj_MeasFlag_26Obj FRS_Obj_YVelRel_26Obj FRS_Obj_XVelRel_26Obj FRS_Obj_YPos_26Obj FRS_Obj_XPos_26Obj;
SIG_GROUP_ 57 Obj25Part02_Grp 1 : FRS_Msg_CheckSum_25Obj02 FRS_Msg_AliveCounter_25Obj02 FRS_Obj_Type_25Obj FRS_Obj_MeasFlag_25Obj FRS_Obj_YVelRel_25Obj FRS_Obj_XVelRel_25Obj FRS_Obj_YPos_25Obj FRS_Obj_XPos_25Obj;
SIG_GROUP_ 56 Obj24Part02_Grp 1 : FRS_Msg_CheckSum_24Obj02 FRS_Msg_AliveCounter_24Obj02 FRS_Obj_Type_24Obj FRS_Obj_MeasFlag_24Obj FRS_Obj_YVelRel_24Obj FRS_Obj_XVelRel_24Obj FRS_Obj_YPos_24Obj FRS_Obj_XPos_24Obj;
SIG_GROUP_ 55 Obj23Part02_Grp 1 : FRS_Msg_CheckSum_23Obj02 FRS_Msg_AliveCounter_23Obj02 FRS_Obj_Type_23Obj FRS_Obj_MeasFlag_23Obj FRS_Obj_YVelRel_23Obj FRS_Obj_XVelRel_23Obj FRS_Obj_YPos_23Obj FRS_Obj_XPos_23Obj;
SIG_GROUP_ 54 Obj22Part02_Grp 1 : FRS_Msg_CheckSum_22Obj02 FRS_Msg_AliveCounter_22Obj02 FRS_Obj_Type_22Obj FRS_Obj_MeasFlag_22Obj FRS_Obj_YVelRel_22Obj FRS_Obj_XVelRel_22Obj FRS_Obj_YPos_22Obj FRS_Obj_XPos_22Obj;
SIG_GROUP_ 53 Obj21Part02_Grp 1 : FRS_Msg_CheckSum_21Obj02 FRS_Msg_AliveCounter_21Obj02 FRS_Obj_Type_21Obj FRS_Obj_MeasFlag_21Obj FRS_Obj_YVelRel_21Obj FRS_Obj_XVelRel_21Obj FRS_Obj_YPos_21Obj FRS_Obj_XPos_21Obj;
SIG_GROUP_ 52 Obj20Part02_Grp 1 : FRS_Msg_CheckSum_20Obj02 FRS_Msg_AliveCounter_20Obj02 FRS_Obj_Type_20Obj FRS_Obj_MeasFlag_20Obj FRS_Obj_YVelRel_20Obj FRS_Obj_XVelRel_20Obj FRS_Obj_YPos_20Obj FRS_Obj_XPos_20Obj;
SIG_GROUP_ 51 Obj19Part02_Grp 1 : FRS_Msg_CheckSum_19Obj02 FRS_Msg_AliveCounter_19Obj02 FRS_Obj_Type_19Obj FRS_Obj_MeasFlag_19Obj FRS_Obj_YVelRel_19Obj FRS_Obj_XVelRel_19Obj FRS_Obj_YPos_19Obj FRS_Obj_XPos_19Obj;
SIG_GROUP_ 50 Obj18Part02_Grp 1 : FRS_Msg_CheckSum_18Obj02 FRS_Msg_AliveCounter_18Obj02 FRS_Obj_Type_18Obj FRS_Obj_MeasFlag_18Obj FRS_Obj_YVelRel_18Obj FRS_Obj_XVelRel_18Obj FRS_Obj_YPos_18Obj FRS_Obj_XPos_18Obj;
SIG_GROUP_ 49 Obj17Part02_Grp 1 : FRS_Msg_CheckSum_17Obj02 FRS_Msg_AliveCounter_17Obj02 FRS_Obj_Type_17Obj FRS_Obj_MeasFlag_17Obj FRS_Obj_YVelRel_17Obj FRS_Obj_XVelRel_17Obj FRS_Obj_YPos_17Obj FRS_Obj_XPos_17Obj;
SIG_GROUP_ 48 Obj16Part02_Grp 1 : FRS_Msg_CheckSum_16Obj02 FRS_Msg_AliveCounter_16Obj02 FRS_Obj_Type_16Obj FRS_Obj_MeasFlag_16Obj FRS_Obj_YVelRel_16Obj FRS_Obj_XVelRel_16Obj FRS_Obj_YPos_16Obj FRS_Obj_XPos_16Obj;
SIG_GROUP_ 47 Obj15Part02_Grp 1 : FRS_Msg_CheckSum_15Obj02 FRS_Msg_AliveCounter_15Obj02 FRS_Obj_Type_15Obj FRS_Obj_MeasFlag_15Obj FRS_Obj_YVelRel_15Obj FRS_Obj_XVelRel_15Obj FRS_Obj_YPos_15Obj FRS_Obj_XPos_15Obj;
SIG_GROUP_ 46 Obj14Part02_Grp 1 : FRS_Msg_CheckSum_14Obj02 FRS_Msg_AliveCounter_14Obj02 FRS_Obj_Type_14Obj FRS_Obj_MeasFlag_14Obj FRS_Obj_YVelRel_14Obj FRS_Obj_XVelRel_14Obj FRS_Obj_YPos_14Obj FRS_Obj_XPos_14Obj;
SIG_GROUP_ 45 Obj13Part02_Grp 1 : FRS_Msg_CheckSum_13Obj02 FRS_Msg_AliveCounter_13Obj02 FRS_Obj_Type_13Obj FRS_Obj_MeasFlag_13Obj FRS_Obj_YVelRel_13Obj FRS_Obj_XVelRel_13Obj FRS_Obj_YPos_13Obj FRS_Obj_XPos_13Obj;
SIG_GROUP_ 44 Obj12Part02_Grp 1 : FRS_Msg_CheckSum_12Obj02 FRS_Msg_AliveCounter_12Obj02 FRS_Obj_Type_12Obj FRS_Obj_MeasFlag_12Obj FRS_Obj_YVelRel_12Obj FRS_Obj_XVelRel_12Obj FRS_Obj_YPos_12Obj FRS_Obj_XPos_12Obj;
SIG_GROUP_ 43 Obj11Part02_Grp 1 : FRS_Msg_CheckSum_11Obj02 FRS_Msg_AliveCounter_11Obj02 FRS_Obj_Type_11Obj FRS_Obj_MeasFlag_11Obj FRS_Obj_YVelRel_11Obj FRS_Obj_XVelRel_11Obj FRS_Obj_YPos_11Obj FRS_Obj_XPos_11Obj;
SIG_GROUP_ 42 Obj10Part02_Grp 1 : FRS_Msg_CheckSum_10Obj02 FRS_Msg_AliveCounter_10Obj02 FRS_Obj_Type_10Obj FRS_Obj_MeasFlag_10Obj FRS_Obj_YVelRel_10Obj FRS_Obj_XVelRel_10Obj FRS_Obj_YPos_10Obj FRS_Obj_XPos_10Obj;
SIG_GROUP_ 41 Obj09Part02_Grp 1 : FRS_Msg_CheckSum_09Obj02 FRS_Msg_AliveCounter_09Obj02 FRS_Obj_Type_09Obj FRS_Obj_MeasFlag_09Obj FRS_Obj_YVelRel_09Obj FRS_Obj_XVelRel_09Obj FRS_Obj_YPos_09Obj FRS_Obj_XPos_09Obj;
SIG_GROUP_ 40 Obj08Part02_Grp 1 : FRS_Msg_CheckSum_08Obj02 FRS_Msg_AliveCounter_08Obj02 FRS_Obj_Type_08Obj FRS_Obj_MeasFlag_08Obj FRS_Obj_YVelRel_08Obj FRS_Obj_XVelRel_08Obj FRS_Obj_YPos_08Obj FRS_Obj_XPos_08Obj;
SIG_GROUP_ 39 Obj07Part02_Grp 1 : FRS_Msg_CheckSum_07Obj02 FRS_Msg_AliveCounter_07Obj02 FRS_Obj_Type_07Obj FRS_Obj_MeasFlag_07Obj FRS_Obj_YVelRel_07Obj FRS_Obj_XVelRel_07Obj FRS_Obj_YPos_07Obj FRS_Obj_XPos_07Obj;
SIG_GROUP_ 38 Obj06Part02_Grp 1 : FRS_Msg_CheckSum_06Obj02 FRS_Msg_AliveCounter_06Obj02 FRS_Obj_Type_06Obj FRS_Obj_MeasFlag_06Obj FRS_Obj_YVelRel_06Obj FRS_Obj_XVelRel_06Obj FRS_Obj_YPos_06Obj FRS_Obj_XPos_06Obj;
SIG_GROUP_ 37 Obj05Part02_Grp 1 : FRS_Msg_CheckSum_05Obj02 FRS_Msg_AliveCounter_05Obj02 FRS_Obj_Type_05Obj FRS_Obj_MeasFlag_05Obj FRS_Obj_YVelRel_05Obj FRS_Obj_XVelRel_05Obj FRS_Obj_YPos_05Obj FRS_Obj_XPos_05Obj;
SIG_GROUP_ 36 Obj04Part02_Grp 1 : FRS_Msg_CheckSum_04Obj02 FRS_Msg_AliveCounter_04Obj02 FRS_Obj_Type_04Obj FRS_Obj_MeasFlag_04Obj FRS_Obj_YVelRel_04Obj FRS_Obj_XVelRel_04Obj FRS_Obj_YPos_04Obj FRS_Obj_XPos_04Obj;
SIG_GROUP_ 35 Obj03Part02_Grp 1 : FRS_Msg_CheckSum_03Obj02 FRS_Msg_AliveCounter_03Obj02 FRS_Obj_Type_03Obj FRS_Obj_MeasFlag_03Obj FRS_Obj_YVelRel_03Obj FRS_Obj_XVelRel_03Obj FRS_Obj_YPos_03Obj FRS_Obj_XPos_03Obj;
SIG_GROUP_ 34 Obj02Part02_Grp 1 : FRS_Msg_CheckSum_02Obj02 FRS_Msg_AliveCounter_02Obj02 FRS_Obj_Type_02Obj FRS_Obj_MeasFlag_02Obj FRS_Obj_YVelRel_02Obj FRS_Obj_XVelRel_02Obj FRS_Obj_YPos_02Obj FRS_Obj_XPos_02Obj;
SIG_GROUP_ 33 Obj01Part02_Grp 1 : FRS_Msg_CheckSum_01Obj02 FRS_Msg_AliveCounter_01Obj02 FRS_Obj_Type_01Obj FRS_Obj_MeasFlag_01Obj FRS_Obj_YVelRel_01Obj FRS_Obj_XVelRel_01Obj FRS_Obj_YPos_01Obj FRS_Obj_XPos_01Obj;
SIG_GROUP_ 119 Obj39Part01_Grp 1 : FRS_Msg_AliveCounter_39Obj01 FRS_Obj_ExstProb_39Obj FRS_Msg_CheckSum_39Obj01 FRS_Obj_XAccRel_39Obj FRS_Obj_XVelRel_Stdev_39Obj FRS_Obj_YPos_Stdev_39Obj FRS_Obj_XPos_Stdev_39Obj FRS_ObjMotionPattern_39Obj FRS_Obj_ValidFlag_39Obj FRS_Obj_UpdateFlag_39Obj FRS_Obj_ObstacleProb_39Obj FRS_Obj_ID_39Obj;
SIG_GROUP_ 118 Obj38Part01_Grp 1 : FRS_Msg_AliveCounter_38Obj01 FRS_Obj_ExstProb_38Obj FRS_Msg_CheckSum_38Obj01 FRS_Obj_XAccRel_38Obj FRS_Obj_XVelRel_Stdev_38Obj FRS_Obj_YPos_Stdev_38Obj FRS_Obj_XPos_Stdev_38Obj FRS_ObjMotionPattern_38Obj FRS_Obj_ValidFlag_38Obj FRS_Obj_UpdateFlag_38Obj FRS_Obj_ObstacleProb_38Obj FRS_Obj_ID_38Obj;
SIG_GROUP_ 117 Obj37Part01_Grp 1 : FRS_Msg_AliveCounter_37Obj01 FRS_Obj_ExstProb_37Obj FRS_Msg_CheckSum_37Obj01 FRS_Obj_XAccRel_37Obj FRS_Obj_XVelRel_Stdev_37Obj FRS_Obj_YPos_Stdev_37Obj FRS_Obj_XPos_Stdev_37Obj FRS_ObjMotionPattern_37Obj FRS_Obj_ValidFlag_37Obj FRS_Obj_UpdateFlag_37Obj FRS_Obj_ObstacleProb_37Obj FRS_Obj_ID_37Obj;
SIG_GROUP_ 116 Obj36Part01_Grp 1 : FRS_Msg_AliveCounter_36Obj01 FRS_Obj_ExstProb_36Obj FRS_Msg_CheckSum_36Obj01 FRS_Obj_XAccRel_36Obj FRS_Obj_XVelRel_Stdev_36Obj FRS_Obj_YPos_Stdev_36Obj FRS_Obj_XPos_Stdev_36Obj FRS_ObjMotionPattern_36Obj FRS_Obj_ValidFlag_36Obj FRS_Obj_UpdateFlag_36Obj FRS_Obj_ObstacleProb_36Obj FRS_Obj_ID_36Obj;
SIG_GROUP_ 115 Obj35Part01_Grp 1 : FRS_Msg_AliveCounter_35Obj01 FRS_Obj_ExstProb_35Obj FRS_Msg_CheckSum_35Obj01 FRS_Obj_XAccRel_35Obj FRS_Obj_XVelRel_Stdev_35Obj FRS_Obj_YPos_Stdev_35Obj FRS_Obj_XPos_Stdev_35Obj FRS_ObjMotionPattern_35Obj FRS_Obj_ValidFlag_35Obj FRS_Obj_UpdateFlag_35Obj FRS_Obj_ObstacleProb_35Obj FRS_Obj_ID_35Obj;
SIG_GROUP_ 114 Obj34Part01_Grp 1 : FRS_Msg_AliveCounter_34Obj01 FRS_Obj_ExstProb_34Obj FRS_Msg_CheckSum_34Obj01 FRS_Obj_XAccRel_34Obj FRS_Obj_XVelRel_Stdev_34Obj FRS_Obj_YPos_Stdev_34Obj FRS_Obj_XPos_Stdev_34Obj FRS_ObjMotionPattern_34Obj FRS_Obj_ValidFlag_34Obj FRS_Obj_UpdateFlag_34Obj FRS_Obj_ObstacleProb_34Obj FRS_Obj_ID_34Obj;
SIG_GROUP_ 113 Obj33Part01_Grp 1 : FRS_Msg_AliveCounter_33Obj01 FRS_Obj_ExstProb_33Obj FRS_Msg_CheckSum_33Obj01 FRS_Obj_XAccRel_33Obj FRS_Obj_XVelRel_Stdev_33Obj FRS_Obj_YPos_Stdev_33Obj FRS_Obj_XPos_Stdev_33Obj FRS_ObjMotionPattern_33Obj FRS_Obj_ValidFlag_33Obj FRS_Obj_UpdateFlag_33Obj FRS_Obj_ObstacleProb_33Obj FRS_Obj_ID_33Obj;
SIG_GROUP_ 112 Obj32Part01_Grp 1 : FRS_Msg_AliveCounter_32Obj01 FRS_Obj_ExstProb_32Obj FRS_Msg_CheckSum_32Obj01 FRS_Obj_XAccRel_32Obj FRS_Obj_XVelRel_Stdev_32Obj FRS_Obj_YPos_Stdev_32Obj FRS_Obj_XPos_Stdev_32Obj FRS_ObjMotionPattern_32Obj FRS_Obj_ValidFlag_32Obj FRS_Obj_UpdateFlag_32Obj FRS_Obj_ObstacleProb_32Obj FRS_Obj_ID_32Obj;
SIG_GROUP_ 111 Obj31Part01_Grp 1 : FRS_Msg_AliveCounter_31Obj01 FRS_Obj_ExstProb_31Obj FRS_Msg_CheckSum_31Obj01 FRS_Obj_XAccRel_31Obj FRS_Obj_XVelRel_Stdev_31Obj FRS_Obj_YPos_Stdev_31Obj FRS_Obj_XPos_Stdev_31Obj FRS_ObjMotionPattern_31Obj FRS_Obj_ValidFlag_31Obj FRS_Obj_UpdateFlag_31Obj FRS_Obj_ObstacleProb_31Obj FRS_Obj_ID_31Obj;
SIG_GROUP_ 110 Obj30Part01_Grp 1 : FRS_Msg_AliveCounter_30Obj01 FRS_Obj_ExstProb_30Obj FRS_Msg_CheckSum_30Obj01 FRS_Obj_XAccRel_30Obj FRS_Obj_XVelRel_Stdev_30Obj FRS_Obj_YPos_Stdev_30Obj FRS_Obj_XPos_Stdev_30Obj FRS_ObjMotionPattern_30Obj FRS_Obj_ValidFlag_30Obj FRS_Obj_UpdateFlag_30Obj FRS_Obj_ObstacleProb_30Obj FRS_Obj_ID_30Obj;
SIG_GROUP_ 109 Obj29Part01_Grp 1 : FRS_Msg_AliveCounter_29Obj01 FRS_Obj_ExstProb_29Obj FRS_Msg_CheckSum_29Obj01 FRS_Obj_XAccRel_29Obj FRS_Obj_XVelRel_Stdev_29Obj FRS_Obj_YPos_Stdev_29Obj FRS_Obj_XPos_Stdev_29Obj FRS_ObjMotionPattern_29Obj FRS_Obj_ValidFlag_29Obj FRS_Obj_UpdateFlag_29Obj FRS_Obj_ObstacleProb_29Obj FRS_Obj_ID_29Obj;
SIG_GROUP_ 108 Obj28Part01_Grp 1 : FRS_Msg_AliveCounter_28Obj01 FRS_Obj_ExstProb_28Obj FRS_Msg_CheckSum_28Obj01 FRS_Obj_XAccRel_28Obj FRS_Obj_XVelRel_Stdev_28Obj FRS_Obj_YPos_Stdev_28Obj FRS_Obj_XPos_Stdev_28Obj FRS_ObjMotionPattern_28Obj FRS_Obj_ValidFlag_28Obj FRS_Obj_UpdateFlag_28Obj FRS_Obj_ObstacleProb_28Obj FRS_Obj_ID_28Obj;
SIG_GROUP_ 107 Obj27Part01_Grp 1 : FRS_Msg_AliveCounter_27Obj01 FRS_Obj_ExstProb_27Obj FRS_Msg_CheckSum_27Obj01 FRS_Obj_XAccRel_27Obj FRS_Obj_XVelRel_Stdev_27Obj FRS_Obj_YPos_Stdev_27Obj FRS_Obj_XPos_Stdev_27Obj FRS_ObjMotionPattern_27Obj FRS_Obj_ValidFlag_27Obj FRS_Obj_UpdateFlag_27Obj FRS_Obj_ObstacleProb_27Obj FRS_Obj_ID_27Obj;
SIG_GROUP_ 106 Obj26Part01_Grp 1 : FRS_Msg_AliveCounter_26Obj01 FRS_Obj_ExstProb_26Obj FRS_Msg_CheckSum_26Obj01 FRS_Obj_XAccRel_26Obj FRS_Obj_XVelRel_Stdev_26Obj FRS_Obj_YPos_Stdev_26Obj FRS_Obj_XPos_Stdev_26Obj FRS_ObjMotionPattern_26Obj FRS_Obj_ValidFlag_26Obj FRS_Obj_UpdateFlag_26Obj FRS_Obj_ObstacleProb_26Obj FRS_Obj_ID_26Obj;
SIG_GROUP_ 105 Obj25Part01_Grp 1 : FRS_Msg_AliveCounter_25Obj01 FRS_Obj_ExstProb_25Obj FRS_Msg_CheckSum_25Obj01 FRS_Obj_XAccRel_25Obj FRS_Obj_XVelRel_Stdev_25Obj FRS_Obj_YPos_Stdev_25Obj FRS_Obj_XPos_Stdev_25Obj FRS_ObjMotionPattern_25Obj FRS_Obj_ValidFlag_25Obj FRS_Obj_UpdateFlag_25Obj FRS_Obj_ObstacleProb_25Obj FRS_Obj_ID_25Obj;
SIG_GROUP_ 104 Obj24Part01_Grp 1 : FRS_Msg_AliveCounter_24Obj01 FRS_Obj_ExstProb_24Obj FRS_Msg_CheckSum_24Obj01 FRS_Obj_XAccRel_24Obj FRS_Obj_XVelRel_Stdev_24Obj FRS_Obj_YPos_Stdev_24Obj FRS_Obj_XPos_Stdev_24Obj FRS_ObjMotionPattern_24Obj FRS_Obj_ValidFlag_24Obj FRS_Obj_UpdateFlag_24Obj FRS_Obj_ObstacleProb_24Obj FRS_Obj_ID_24Obj;
SIG_GROUP_ 103 Obj23Part01_Grp 1 : FRS_Msg_AliveCounter_23Obj01 FRS_Obj_ExstProb_23Obj FRS_Msg_CheckSum_23Obj01 FRS_Obj_XAccRel_23Obj FRS_Obj_XVelRel_Stdev_23Obj FRS_Obj_YPos_Stdev_23Obj FRS_Obj_XPos_Stdev_23Obj FRS_ObjMotionPattern_23Obj FRS_Obj_ValidFlag_23Obj FRS_Obj_UpdateFlag_23Obj FRS_Obj_ObstacleProb_23Obj FRS_Obj_ID_23Obj;
SIG_GROUP_ 102 Obj22Part01_Grp 1 : FRS_Msg_AliveCounter_22Obj01 FRS_Obj_ExstProb_22Obj FRS_Msg_CheckSum_22Obj01 FRS_Obj_XAccRel_22Obj FRS_Obj_XVelRel_Stdev_22Obj FRS_Obj_YPos_Stdev_22Obj FRS_Obj_XPos_Stdev_22Obj FRS_ObjMotionPattern_22Obj FRS_Obj_ValidFlag_22Obj FRS_Obj_UpdateFlag_22Obj FRS_Obj_ObstacleProb_22Obj FRS_Obj_ID_22Obj;
SIG_GROUP_ 101 Obj21Part01_Grp 1 : FRS_Msg_AliveCounter_21Obj01 FRS_Obj_ExstProb_21Obj FRS_Msg_CheckSum_21Obj01 FRS_Obj_XAccRel_21Obj FRS_Obj_XVelRel_Stdev_21Obj FRS_Obj_YPos_Stdev_21Obj FRS_Obj_XPos_Stdev_21Obj FRS_ObjMotionPattern_21Obj FRS_Obj_ValidFlag_21Obj FRS_Obj_UpdateFlag_21Obj FRS_Obj_ObstacleProb_21Obj FRS_Obj_ID_21Obj;
SIG_GROUP_ 100 Obj20Part01_Grp 1 : FRS_Msg_AliveCounter_20Obj01 FRS_Obj_ExstProb_20Obj FRS_Msg_CheckSum_20Obj01 FRS_Obj_XAccRel_20Obj FRS_Obj_XVelRel_Stdev_20Obj FRS_Obj_YPos_Stdev_20Obj FRS_Obj_XPos_Stdev_20Obj FRS_ObjMotionPattern_20Obj FRS_Obj_ValidFlag_20Obj FRS_Obj_UpdateFlag_20Obj FRS_Obj_ObstacleProb_20Obj FRS_Obj_ID_20Obj;
SIG_GROUP_ 99 Obj19Part01_Grp 1 : FRS_Msg_AliveCounter_19Obj01 FRS_Obj_ExstProb_19Obj FRS_Msg_CheckSum_19Obj01 FRS_Obj_XAccRel_19Obj FRS_Obj_XVelRel_Stdev_19Obj FRS_Obj_YPos_Stdev_19Obj FRS_Obj_XPos_Stdev_19Obj FRS_ObjMotionPattern_19Obj FRS_Obj_ValidFlag_19Obj FRS_Obj_UpdateFlag_19Obj FRS_Obj_ObstacleProb_19Obj FRS_Obj_ID_19Obj;
SIG_GROUP_ 98 Obj18Part01_Grp 1 : FRS_Msg_AliveCounter_18Obj01 FRS_Obj_ExstProb_18Obj FRS_Msg_CheckSum_18Obj01 FRS_Obj_XAccRel_18Obj FRS_Obj_XVelRel_Stdev_18Obj FRS_Obj_YPos_Stdev_18Obj FRS_Obj_XPos_Stdev_18Obj FRS_ObjMotionPattern_18Obj FRS_Obj_ValidFlag_18Obj FRS_Obj_UpdateFlag_18Obj FRS_Obj_ObstacleProb_18Obj FRS_Obj_ID_18Obj;
SIG_GROUP_ 97 Obj17Part01_Grp 1 : FRS_Msg_AliveCounter_17Obj01 FRS_Obj_ExstProb_17Obj FRS_Msg_CheckSum_17Obj01 FRS_Obj_XAccRel_17Obj FRS_Obj_XVelRel_Stdev_17Obj FRS_Obj_YPos_Stdev_17Obj FRS_Obj_XPos_Stdev_17Obj FRS_ObjMotionPattern_17Obj FRS_Obj_ValidFlag_17Obj FRS_Obj_UpdateFlag_17Obj FRS_Obj_ObstacleProb_17Obj FRS_Obj_ID_17Obj;
SIG_GROUP_ 96 Obj16Part01_Grp 1 : FRS_Msg_AliveCounter_16Obj01 FRS_Obj_ExstProb_16Obj FRS_Msg_CheckSum_16Obj01 FRS_Obj_XAccRel_16Obj FRS_Obj_XVelRel_Stdev_16Obj FRS_Obj_YPos_Stdev_16Obj FRS_Obj_XPos_Stdev_16Obj FRS_ObjMotionPattern_16Obj FRS_Obj_ValidFlag_16Obj FRS_Obj_UpdateFlag_16Obj FRS_Obj_ObstacleProb_16Obj FRS_Obj_ID_16Obj;
SIG_GROUP_ 95 Obj15Part01_Grp 1 : FRS_Msg_AliveCounter_15Obj01 FRS_Obj_ExstProb_15Obj FRS_Msg_CheckSum_15Obj01 FRS_Obj_XAccRel_15Obj FRS_Obj_XVelRel_Stdev_15Obj FRS_Obj_YPos_Stdev_15Obj FRS_Obj_XPos_Stdev_15Obj FRS_ObjMotionPattern_15Obj FRS_Obj_ValidFlag_15Obj FRS_Obj_UpdateFlag_15Obj FRS_Obj_ObstacleProb_15Obj FRS_Obj_ID_15Obj;
SIG_GROUP_ 94 Obj14Part01_Grp 1 : FRS_Msg_AliveCounter_14Obj01 FRS_Obj_ExstProb_14Obj FRS_Msg_CheckSum_14Obj01 FRS_Obj_XAccRel_14Obj FRS_Obj_XVelRel_Stdev_14Obj FRS_Obj_YPos_Stdev_14Obj FRS_Obj_XPos_Stdev_14Obj FRS_ObjMotionPattern_14Obj FRS_Obj_ValidFlag_14Obj FRS_Obj_UpdateFlag_14Obj FRS_Obj_ObstacleProb_14Obj FRS_Obj_ID_14Obj;
SIG_GROUP_ 93 Obj13Part01_Grp 1 : FRS_Msg_AliveCounter_13Obj01 FRS_Obj_ExstProb_13Obj FRS_Msg_CheckSum_13Obj01 FRS_Obj_XAccRel_13Obj FRS_Obj_XVelRel_Stdev_13Obj FRS_Obj_YPos_Stdev_13Obj FRS_Obj_XPos_Stdev_13Obj FRS_ObjMotionPattern_13Obj FRS_Obj_ValidFlag_13Obj FRS_Obj_UpdateFlag_13Obj FRS_Obj_ObstacleProb_13Obj FRS_Obj_ID_13Obj;
SIG_GROUP_ 92 Obj12Part01_Grp 1 : FRS_Msg_AliveCounter_12Obj01 FRS_Obj_ExstProb_12Obj FRS_Msg_CheckSum_12Obj01 FRS_Obj_XAccRel_12Obj FRS_Obj_XVelRel_Stdev_12Obj FRS_Obj_YPos_Stdev_12Obj FRS_Obj_XPos_Stdev_12Obj FRS_ObjMotionPattern_12Obj FRS_Obj_ValidFlag_12Obj FRS_Obj_UpdateFlag_12Obj FRS_Obj_ObstacleProb_12Obj FRS_Obj_ID_12Obj;
SIG_GROUP_ 91 Obj11Part01_Grp 1 : FRS_Msg_AliveCounter_11Obj01 FRS_Obj_ExstProb_11Obj FRS_Msg_CheckSum_11Obj01 FRS_Obj_XAccRel_11Obj FRS_Obj_XVelRel_Stdev_11Obj FRS_Obj_YPos_Stdev_11Obj FRS_Obj_XPos_Stdev_11Obj FRS_ObjMotionPattern_11Obj FRS_Obj_ValidFlag_11Obj FRS_Obj_UpdateFlag_11Obj FRS_Obj_ObstacleProb_11Obj FRS_Obj_ID_11Obj;
SIG_GROUP_ 90 Obj10Part01_Grp 1 : FRS_Msg_AliveCounter_10Obj01 FRS_Obj_ExstProb_10Obj FRS_Msg_CheckSum_10Obj01 FRS_Obj_XAccRel_10Obj FRS_Obj_XVelRel_Stdev_10Obj FRS_Obj_YPos_Stdev_10Obj FRS_Obj_XPos_Stdev_10Obj FRS_ObjMotionPattern_10Obj FRS_Obj_ValidFlag_10Obj FRS_Obj_UpdateFlag_10Obj FRS_Obj_ObstacleProb_10Obj FRS_Obj_ID_10Obj;
SIG_GROUP_ 89 Obj09Part01_Grp 1 : FRS_Msg_AliveCounter_09Obj01 FRS_Obj_ExstProb_09Obj FRS_Msg_CheckSum_09Obj01 FRS_Obj_XAccRel_09Obj FRS_Obj_XVelRel_Stdev_09Obj FRS_Obj_YPos_Stdev_09Obj FRS_Obj_XPos_Stdev_09Obj FRS_ObjMotionPattern_09Obj FRS_Obj_ValidFlag_09Obj FRS_Obj_UpdateFlag_09Obj FRS_Obj_ObstacleProb_09Obj FRS_Obj_ID_09Obj;
SIG_GROUP_ 88 Obj08Part01_Grp 1 : FRS_Msg_AliveCounter_08Obj01 FRS_Obj_ExstProb_08Obj FRS_Msg_CheckSum_08Obj01 FRS_Obj_XAccRel_08Obj FRS_Obj_XVelRel_Stdev_08Obj FRS_Obj_YPos_Stdev_08Obj FRS_Obj_XPos_Stdev_08Obj FRS_ObjMotionPattern_08Obj FRS_Obj_ValidFlag_08Obj FRS_Obj_UpdateFlag_08Obj FRS_Obj_ObstacleProb_08Obj FRS_Obj_ID_08Obj;
SIG_GROUP_ 87 Obj07Part01_Grp 1 : FRS_Msg_AliveCounter_07Obj01 FRS_Obj_ExstProb_07Obj FRS_Msg_CheckSum_07Obj01 FRS_Obj_XAccRel_07Obj FRS_Obj_XVelRel_Stdev_07Obj FRS_Obj_YPos_Stdev_07Obj FRS_Obj_XPos_Stdev_07Obj FRS_ObjMotionPattern_07Obj FRS_Obj_ValidFlag_07Obj FRS_Obj_UpdateFlag_07Obj FRS_Obj_ObstacleProb_07Obj FRS_Obj_ID_07Obj;
SIG_GROUP_ 86 Obj06Part01_Grp 1 : FRS_Msg_AliveCounter_06Obj01 FRS_Obj_ExstProb_06Obj FRS_Msg_CheckSum_06Obj01 FRS_Obj_XAccRel_06Obj FRS_Obj_XVelRel_Stdev_06Obj FRS_Obj_YPos_Stdev_06Obj FRS_Obj_XPos_Stdev_06Obj FRS_ObjMotionPattern_06Obj FRS_Obj_ValidFlag_06Obj FRS_Obj_UpdateFlag_06Obj FRS_Obj_ObstacleProb_06Obj FRS_Obj_ID_06Obj;
SIG_GROUP_ 85 Obj05Part01_Grp 1 : FRS_Msg_AliveCounter_05Obj01 FRS_Obj_ExstProb_05Obj FRS_Msg_CheckSum_05Obj01 FRS_Obj_XAccRel_05Obj FRS_Obj_XVelRel_Stdev_05Obj FRS_Obj_YPos_Stdev_05Obj FRS_Obj_XPos_Stdev_05Obj FRS_ObjMotionPattern_05Obj FRS_Obj_ValidFlag_05Obj FRS_Obj_UpdateFlag_05Obj FRS_Obj_ObstacleProb_05Obj FRS_Obj_ID_05Obj;
SIG_GROUP_ 84 Obj04Part01_Grp 1 : FRS_Msg_AliveCounter_04Obj01 FRS_Obj_ExstProb_04Obj FRS_Msg_CheckSum_04Obj01 FRS_Obj_XAccRel_04Obj FRS_Obj_XVelRel_Stdev_04Obj FRS_Obj_YPos_Stdev_04Obj FRS_Obj_XPos_Stdev_04Obj FRS_ObjMotionPattern_04Obj FRS_Obj_ValidFlag_04Obj FRS_Obj_UpdateFlag_04Obj FRS_Obj_ObstacleProb_04Obj FRS_Obj_ID_04Obj;
SIG_GROUP_ 83 Obj03Part01_Grp 1 : FRS_Msg_AliveCounter_03Obj01 FRS_Obj_ExstProb_03Obj FRS_Msg_CheckSum_03Obj01 FRS_Obj_XAccRel_03Obj FRS_Obj_XVelRel_Stdev_03Obj FRS_Obj_YPos_Stdev_03Obj FRS_Obj_XPos_Stdev_03Obj FRS_ObjMotionPattern_03Obj FRS_Obj_ValidFlag_03Obj FRS_Obj_UpdateFlag_03Obj FRS_Obj_ObstacleProb_03Obj FRS_Obj_ID_03Obj;
SIG_GROUP_ 82 Obj02Part01_Grp 1 : FRS_Msg_AliveCounter_02Obj01 FRS_Obj_ExstProb_02Obj FRS_Msg_CheckSum_02Obj01 FRS_Obj_XAccRel_02Obj FRS_Obj_XVelRel_Stdev_02Obj FRS_Obj_YPos_Stdev_02Obj FRS_Obj_XPos_Stdev_02Obj FRS_ObjMotionPattern_02Obj FRS_Obj_ValidFlag_02Obj FRS_Obj_UpdateFlag_02Obj FRS_Obj_ObstacleProb_02Obj FRS_Obj_ID_02Obj;
SIG_GROUP_ 81 Obj01Part01_Grp 1 : FRS_Msg_AliveCounter_01Obj01 FRS_Obj_ExstProb_01Obj FRS_Msg_CheckSum_01Obj01 FRS_Obj_XAccRel_01Obj FRS_Obj_XVelRel_Stdev_01Obj FRS_Obj_YPos_Stdev_01Obj FRS_Obj_XPos_Stdev_01Obj FRS_ObjMotionPattern_01Obj FRS_Obj_ValidFlag_01Obj FRS_Obj_UpdateFlag_01Obj FRS_Obj_ObstacleProb_01Obj FRS_Obj_ID_01Obj;
SIG_GROUP_ 32 Obj00Part02_Grp 1 : FRS_Msg_CheckSum_00Obj02 FRS_Msg_AliveCounter_00Obj02 FRS_Obj_Type_00Obj FRS_Obj_MeasFlag_00Obj FRS_Obj_YVelRel_00Obj FRS_Obj_XVelRel_00Obj FRS_Obj_YPos_00Obj FRS_Obj_XPos_00Obj;
SIG_GROUP_ 80 Obj00Part01_Grp 1 : FRS_Msg_AliveCounter_00Obj01 FRS_Obj_ExstProb_00Obj FRS_Msg_CheckSum_00Obj01 FRS_Obj_XAccRel_00Obj FRS_Obj_XVelRel_Stdev_00Obj FRS_Obj_YPos_Stdev_00Obj FRS_Obj_XPos_Stdev_00Obj FRS_ObjMotionPattern_00Obj FRS_Obj_ValidFlag_00Obj FRS_Obj_UpdateFlag_00Obj FRS_Obj_ObstacleProb_00Obj FRS_Obj_ID_00Obj;
SIG_GROUP_ 128 FSRStatus_Grp 1 : FRS_Status_HWErr FRS_Status_BlkProg FRS_Status_MisAlign FRS_Fail FRS_MeasEnabled FRS_Host_Yaw FRS_HostSpeed FRS_TimeStamp FRS_Latency FRS_Msg_CheckSum FRS_Msg_AliveCounter;
SIG_GROUP_ 291 RWheelSpeed_Grp 1 : ESC_RWheelSpeedsKPH_CheckSum ESC_RWheelSpeedsKPH_AliveCounter ESC_RRWheelSpeedKPH ESC_RRWheelSpeedInvalid ESC_RRWheelDirection ESC_RLWheelSpeedKPH ESC_RLWheelDirection ESC_RLWheelSpeedInvalid;
SIG_GROUP_ 290 FWheelSpeed_Grp 1 : ESC_FWheelSpeedsKPH_CheckSum ESC_FWheelSpeedsKPH_AliveCounter ESC_FRWheelDirection ESC_FRWheelSpeedInvalid ESC_FRWheelSpeedKPH ESC_FLWheelDirection ESC_FLWheelSpeedInvalid ESC_FLWheelSpeedKPH;
SIG_GROUP_ 357 GearPosition_Grp 1 : VCU_ModeControl_AliveCounter VCU_ModeControl_CheckSum VCU_CurrentGearPosition;
SIG_GROUP_ 304 YawRate_Grp 1 : YRS_LateralSensorState YRS1_CheckSum YRS_LateralAcce YRS_YawRate YRS1_AliveCounter YRS_YawRateSensorState;
SIG_GROUP_ 305 LongitAcce_Grp 1 : YRS_LongitSensorState YRS2_CheckSum YRS_LongitAcce YRS2_AliveCounter;
SIG_GROUP_ 224 SteerWheelAngle_Grp 1 : SAS_FailureSts SAS_Status_AliveCounter SAS_Status_CheckSum SAS_SteerWheelAngle;
SIG_GROUP_ 293 VehicleSpeed_Grp 1 : ESC_VehicleSpeedInvalid ESC_VehicleSpeed ESC_Status_AliveCounter ESC_Status_CheckSum;
SIG_GROUP_ 133 EngStatus_Grp 1 : EMS_EngineRPM_AliveCounter EMS_EngineRPM_CheckSum EMS_EngStatus;
SIG_GROUP_ 275 GearPosition_Grp 1 : TCU_Status_AliveCounter TCU_CurrentGearPosition TCU_Status_CheckSum;
